VERSION ""

NS_ :

BS_:

BU_: LMFS RMFS TPMS TCU_ERAGLONASS E_APU PCCM NOX_2 NOX_1 ENGINE_CONTROL_MODULE TRANSMISSION INTARDER EBS TACHOGRAPH INSTRUMENT_CLUSTER CAMERA RADAR BCM
VAL_TABLE_ User_Data_Services_Selection 2 "Data Services On" 1 "Data Services Off" 0 "No Command" ;
VAL_TABLE_ User_Location_Selection 2 "Location On" 1 "Location Off" 0 "No Command" ;
VAL_TABLE_ UserConnectivitySelection 2 "Connectivity On" 1 "Connectivity Off" 0 "No Command" ;
VAL_TABLE_ Location_Status 3 "Reserved" 2 "On" 1 "Off" 0 "No command" ;
VAL_TABLE_ ConnectionStatusforTelltale 3 "Reserved" 2 "Sharing Data & Location" 1 "Sharing Just Data" 0 "Off" ;
VAL_TABLE_ ConnectivityHMIEnable 3 "Reserved" 2 "Connectivity Enabled" 1 "Connectivity Disabled" 0 "No Command" ;
VAL_TABLE_ RC_Window_Status 3 "Window_Calibration_is_required" 2 "Open" 1 "Inprogress" 0 "Closed" ;
VAL_TABLE_ Vt_Trip_Reset_2 3 "N/A" 2 "Error" 1 "Trip2 resetted by driver" 0 "No reset" ;
VAL_TABLE_ Vt_Trip_Reset_1 3 "N/A" 2 "Error" 1 "Trip1 resetted by driver" 0 "No reset" ;
VAL_TABLE_ PTOStatus_Vt 3 "NA" 2 "Reserved" 1 "On" 0 "Off" ;
VAL_TABLE_ RearFogLampStatus_VT 3 "NA" 2 "Reserved" 1 "On" 0 "Off" ;
VAL_TABLE_ ConnectionStatus_vt 3 "NA" 2 "Reserved" 1 "Connected" 0 "Not Connected" ;
VAL_TABLE_ FrontFogLampStatus_VT 3 "NA" 2 "Reserved" 1 "Front Fog On" 0 "Front Fog Off" ;
VAL_TABLE_ DoorLockStatus_Vt 3 "NA" 2 "No Status" 1 "Door Status is Locked" 0 "Door Status is Unlocked" ;
VAL_TABLE_ LaneDepartureWarning 3 "NA" 2 "Error" 1 "Enable Lane Departure Warning" 0 "Disable Lane Departure Warning" ;
VAL_TABLE_ DrvActivationDemand 3 "don’t care / take no action" 2 "error" 1 "no deactivation of AEBS" 0 "deactivation of AEBS" ;
VAL_TABLE_ Vt_SeatbeltStatus 3 "NA" 2 "Error" 1 "Not Belted" 0 "Belted" ;
VAL_TABLE_ LowCoolantLevel 3 "NA" 2 "Reserved" 1 "LOW Coolant Level" 0 "Coolant Level OK" ;
VAL_TABLE_ AirFilterRestriction 3 "NA" 2 "Reserved" 1 "Restriction on filter " 0 "No restricition on filter" ;
VAL_TABLE_ AutoECall_Inhibit 3 "Not available" 2 "Error indicator" 1 "E-Call Inhibit Active" 0 "E-Call Inhibit Not Active" ;
VAL_TABLE_ Vt_HeaterTimer1Status_Recurrence 3 "NA" 2 "Error" 1 "Repetitive" 0 "One Time" ;
VAL_TABLE_ Vt_HeaterTimer1Status_Day 10 "Everyday" 9 "Weekends" 8 "Weekdays" 7 "Sunday" 6 "Saturday" 5 "Friday" 4 "Thursday" 3 "Wednesday" 2 "Tuesday" 1 "Monday" ;
VAL_TABLE_ Vt_Outside_Air_Temp_Stat_Climate 255 "Invalid" 254 "Unknown" ;
VAL_TABLE_ vt_PCCScreenSelection 3 "Not Available" 2 "Error" 1 "Active" 0 "Deactive" ;
VAL_TABLE_ Vt_HazardLampStatus 3 "not available " 2 "Error" 1 "On" 0 "Off" ;
VAL_TABLE_ Vt_AC_clutch_status 3 "Not Available" 2 "Error" 1 "A/C clutch is engaged" 0 "A/C clutch is not engaged" ;
VAL_TABLE_ Vt_EcoRollSelection 3 "not available" 2 "error" 1 "active" 0 "deactive" ;
VAL_TABLE_ Vt_SpeedLimitsExceedStatus 7 "Reserved " 6 "Reserved " 5 "Reserved " 4 "Reserved " 3 "ASLD  speed limit exceed" 2 "PCC upper speed limit exceed" 1 "Cruise control set speed exceed" 0 "No exceed" ;
VAL_TABLE_ DriverRequestRCU 8 "Memory 2 Level Save" 7 "Memory 2 Height Request" 6 "Memory 1 Level Save" 5 "Memory 1 Height Request" 4 "Raise Chassis Height" 3 "Lower Chassis Height" 2 "Stop Button Pressed" 1 "Ride Height Request" ;
VAL_TABLE_ LampStatus 1 "Lamp on" 0 "Lamp off" ;
VAL_TABLE_ VtSigAuxIO03RetarderLeverPos 3 "Not Available" 2 "Error" 1 "IntarderLeverpos on" 0 "IntarderLeverpos off " ;
VAL_TABLE_ Emergency_Braking_Active 3 "not availeble" 2 "reserved" 1 "active" 0 "in-active" ;
VAL_TABLE_ Error_State 255 "Not available" 254 "Error" ;
VAL_TABLE_ VINACK_status_values 5 "VIN vaildate with previously VIN" 4 "Timout during VIN validation" 3 "Timout during VIN configuration" 2 "VIN not match previosly VIN" 1 "VIN Configuration done " 0 "Factory Def.:Config. not start" ;
VAL_TABLE_ ActiveDeactiveMode 3 "Not available" 2 "Error" 1 "Active" 0 "Deactive" ;
VAL_TABLE_ SensorIDMissingWarning 3 "Not available" 2 "Error" 1 "LearntSensorIDSupported&Missing" 0 "LearntSensorIDSupported&Present" ;
VAL_TABLE_ Vtsig_BremsomatConfiguration 7 "Not available" 6 "Reserved" 5 "Bremsomat Set Speed" 4 "Permanent Signal" 3 "Two buttons" 2 "One button" 1 "Bremsomat on pos 1 of hand lever" 0 "No Bremsomat" ;
VAL_TABLE_ Line_type 7 "no available/not installed" 6 "error" 5 "Bott'sDots detected" 4 "Double line detected" 3 "Dashed line detected" 2 "RoadEdge detected" 1 "Solid line detected" 0 "No line detected" ;
VAL_TABLE_ Hand_Lever_Signals 31 "Position 4" 15 "Position 3" 7 "Position 2" 3 "Position 1" 1 "Position 0" ;
VAL_TABLE_ Hand_lever_signals 3 "NotAvailable" 2 "Error" 1 "TCEngaged" 0 "TCNotEngaged" ;
VAL_TABLE_ OutPointer 254 "Error indicator" 255 "N/A" ;
VAL_TABLE_ OutLCD 254 "Error indicator" 255 "N/A" ;
VAL_TABLE_ OutDial 254 "Error indicator" 255 "N/A" ;
VAL_TABLE_ Time_to_collision 255 "N/A" 238 "Error indicator" ;
VAL_TABLE_ Ext_Vehicle_Speed_Enb 3 "Not available" 2 "Error" 1 "Enable external speed limit" 0 "Disable external speed limit" ;
VAL_TABLE_ SPN3698 3 "N/a" 2 "Reserved" 1 "High Exhaust System Temperature" 0 "Low Exhaust System Temperature" ;
VAL_TABLE_ SPN3712 3 "N/A" 2 "Error" 1 "Inhibited" 0 "Not_Inhibited" ;
VAL_TABLE_ TC1_BCM 3 "TakeNoAction" 2 "Reserve" 1 "Enabled" 0 "Disabled" ;
VAL_TABLE_ PTODE 3 "NA" 2 "Error" 1 "Active" 0 "NotActive" ;
VAL_TABLE_ ETC7 3 "Takenoaction" 2 "Reserve" 1 "Enable" 0 "Disable" ;
VAL_TABLE_ LowOilindicatorstatus 4 "Overfill warning" 3 "Not defined" 2 "Low oil warning" 1 "Critical Low Oil level" 0 "Oil Level OK" ;
VAL_TABLE_ OilChangeWarningIndicator 3 "Error State (Blink @ 2Hz)" 2 "Lamp On (Blinking @ 1 Hz)" 1 "Lamp On (Continuous) " 0 "Lamp Off" ;
VAL_TABLE_ EngineFuelFilterRestrictionLamp 3 "NA" 2 "NA" 1 "Lamp On" 0 "Lamp Off" ;
VAL_TABLE_ ClutchProtectionBuzzer 3 "Error" 2 "Blinking Buzzer" 1 "Continuous Buzzer" 0 "No Buzzer" ;
VAL_TABLE_ ClutchProtectionWarning 3 "Error" 2 "Blinking clutch warning lamp" 1 "Continuous clutch warning lamp" 0 "No warning" ;
VAL_TABLE_ TamperingFaultsBlockedEGR 1 "Critical Emissions Failure" 0 "No warning" ;
VAL_TABLE_ AdblueConsumption 1 "AdBlue Dosing Malfunction" 0 "No warning" ;
VAL_TABLE_ TC1 255 "Error" 253 "Hold current gear" 249 "Upshift 1 gear from current pos" 248 "Upshift 2 gears from current pos" 247 "Downshift 1 gear fromcurrentpos" 246 "Downshift 2 gear fromcurrentpos" ;
VAL_TABLE_ Inhibit 3 "na" 2 "reserved" 1 "inhibited" 0 "not inhibited" ;
VAL_TABLE_ ChargeMode 15 "Error" 14 "Mode 14" 13 "Mode 13" 12 "Mode 12" 11 "Mode 11" 10 "Mode 10" 9 "Mode 9" 8 "Mode 8" 7 "Mode 7" 6 "Mode 6" 5 "Mode 5" 4 "Mode 4" 3 "Mode 3" 2 "Mode 2" 1 "Mode 1" 0 "Mode 0" ;
VAL_TABLE_ Flag 3 "Not Available" 2 "Error" 1 "Flag set" 0 "Flag not set" ;
VAL_TABLE_ ConcretePumpStartRequest 3 "NA Error" 2 "No Request" 1 "Engine Start" ;
VAL_TABLE_ APUPressureSwitch 3 "NotAvailable" 2 "Error" 1 "On" 0 "Off" ;
VAL_TABLE_ AxleState 3 "SelfSteer and TagAxle lifted" 2 "Tag axle lifted" 1 "Self steer axle lifted" 0 "SelfSteer and TagAxle not lifted" ;
VAL_TABLE_ Warning 65 "parking brake is engaged " 17 "Failure Mode is detected" 9 "axle is overloaded" 5 "speedisover30kphduringaxlelift" 3 "Lift/Drop Other axle first" 0 "no warning is active" ;
VAL_TABLE_ Action 99 "Tag axle can’t be lifted" 77 "Self-steer can’t be lifted" 66 "Self-steer can’t be dropped" 44 "Tag axle is being dropped" 22 "Self-steer is being dropped" 10 "Tag axle can’t be dropped" 9 "Tag axle can’t be lifted" 8 "Tag axle can’t be lifted" 7 "Self-steer can’t be lifted" 6 "Self-steer can’t be dropped " 5 "Self-steer can’t be dropped" 4 "Tag axle is being dropped" 3 "Tag axle is being lifted SSisup" 2 "SSisbeingdrped/AutoDropFunc" 1 "Self-steer is being lifted " 0 "No action is occurred " ;
VAL_TABLE_ BatteryService 3 "NotAvailable" 2 "Error" 1 "BatteryServiceNeeded" 0 "BatteryServiceNotNeeded" ;
VAL_TABLE_ EnableSwitchStatus 3 "NotAvailable" 2 "Error" 1 "Active" 0 "NotActive" ;
VAL_TABLE_ ConcretePumpTransferCaseACK 3 "NotAvailable" 2 "Error" 1 "TCEngaged" 0 "TCNotEngaged" ;
VAL_TABLE_ PTOApplicationMode 7 "SIGError" 6 "MinError" 5 "MaxError" 4 "NotPlausible" 3 "Mode3" 2 "Mode2" 1 "Mode1" 0 "Mode0" ;
VAL_TABLE_ CameraStatus 14 "NotAvailable" 13 "Error" 4 "Misaligned" 3 "Blocked" 2 "PartiallyBlocked" 1 "Warningup/Initializing" 0 "FullyOperational" ;
VAL_TABLE_ EGR2EDC 1 "Failure" 0 "NoFailure" ;
VAL_TABLE_ WheelBrakeLiningInfo 255 "NotAvailable" 254 "Error" 252 "BrkPadWearSensorNOK" 251 "BrkPadWearSensorOK" ;
VAL_TABLE_ QuickRockingMode 1 "Active" 0 "NotActive" ;
VAL_TABLE_ ReqstCruiseContrlSwtchOff 3 "NotAvailable" 2 "Reserved" 1 "IntrdrIsReqstCCSwtchOff" 0 "IntrdrIsNotReqstCCSwtchOff" ;
VAL_TABLE_ RetarderOnDriverDemand 3 "NotAvailable" 2 "Reserved" 1 "RetarderOnDriverDemand" 0 "NoRetarderOnDriverDemand" ;
VAL_TABLE_ RequestIntardrPilotLamp 3 "NotAvailable" 2 "Reserved" 1 "IntIsReqstngPilotLamp" 0 "IntIsNotReqstngPilotLamp" ;
VAL_TABLE_ IntPilotLampState 3 "NotAvailable" 2 "IntarderPilotLampFlashes" 1 "IntarderPilotLampOn" 0 "IntarderPilotLampOff" ;
VAL_TABLE_ RtrdrCtrlMthd 0 "ContinuousControl" ;
VAL_TABLE_ EngRqstSpeedCntrlCondition 3 "XStbOptDrvEngaged" 2 "StbOptDrvEngaged" 1 "StbOptDrvDisengaged" 0 "TrnstOptDrvDisengaged" ;
VAL_TABLE_ GearboxNeutralPosition 3 "NotAvailable" 2 "Error" 1 "SecuredNeutralPosition" 0 "NotInSecuredNeutralPosition" ;
VAL_TABLE_ TrailerABSFullyOperational 3 "NotAvailable" 2 "Error" 1 "TrailerABSFullyOperational" 0 "TrailerABSNotFullyOperational" ;
VAL_TABLE_ TrailerABSDetected 3 "NotAvailable" 2 "Error" 1 "TrailerABSDetected" 0 "TrailerABSNotDetected" ;
VAL_TABLE_ BlendingSwitchPos 3 "NotAvailable" 2 "Error" 1 "RetarderBlendingEnabled" 0 "RetarderBlendingDiasabled" ;
VAL_TABLE_ AuxI_O05_TrailerConnected 3 "NotAvailable" 1 "TrailerConnected" 0 "TrailerNotConnected" ;
VAL_TABLE_ LaneDepartureWarningSystemStatus 15 "NotAvailable" 14 "Error" 5 "SystemIsWarning" 4 "DriverOverridesSystem" 3 "SystemIsReady" 2 "SystemIsDeactivatedByDriver" 1 "SystemIsTempNotAvailable" 0 "SystemIsNotReady" ;
VAL_TABLE_ OpticalAcousticWarning 3 "NotAvailable" 2 "Error" 1 "Active" 0 "Inactive" ;
VAL_TABLE_ AdvancedEmergencyBrkSysState 15 "NotAvailable" 14 "ErrorIndication" 7 "EmergencyBrakingActive" 6 "CollisionWarningWithBraking" 5 "CollisionWarningActive" 4 "DriverOverridesSystem" 3 "SystemIsReady" 2 "SystemDeactivatedbyDriver" 1 "SystemTemporaryNotAvailable" 0 "SystemIsnotReady" ;
VAL_TABLE_ WiperActive 3 "NotAvailable" 2 "Error" 1 "WiperActive" 0 "WiperIsNotActive" ;
VAL_TABLE_ Interlock 3 "NotAvailable" 2 "Error" 1 "InterlockEngaged" 0 "InterlockDisengaged" ;
VAL_TABLE_ ReverseGearState 255 "NotAvailable" 254 "Error" 240 "NotDefined" 223 "GearInReversePosition" 1 "NotDefined" 0 "NotInReverseGear" ;
VAL_TABLE_ ParticulateTrapRegenForceSw 3 "NotAvailable" 2 "Error" 1 "Active" 0 "NotActive" ;
VAL_TABLE_ ParticulateTrapRegenInSwitch 3 "NotAvailable" 2 "Error" 1 "Active" 0 "NotActive" ;
VAL_TABLE_ ACCompressorSwitch 3 "NotAvailable" 2 "Error" 1 "PressureNormal" 0 "Pressureisnotnormal" ;
VAL_TABLE_ AEBS2_DriverActivationDemand 3 "NotAvailable" 2 "Error" 1 "NoDeactivationofAEBS" 0 "DeactivationofAEBS" ;
VAL_TABLE_ ERC_Int_RetarderTorqueMode 15 "NotAvailable" 14 "VCMNegativeTorqueLimit" 13 "NotDefined" 12 "NotDefined" 11 "NotDefined" 10 "RetarderControl" 9 "HighSpeedGovernor" 8 "TorqueLimiter" 7 "ABSControl" 6 "TransmissionControl" 5 "ASRControl" 4 "RoadSpeedLimiter" 3 "PowerTakeOffGovernor" 2 "CruiseControl" 1 "OperatorSelection" 0 "NoRequest" ;
VAL_TABLE_ ERC1_ECM_RetarderTorqueMode 15 "NotAvailable" 14 "VCMNegativeTorqueDemand" 13 "NotDefined" 12 "NotDefined" 11 "NotDefined" 10 "RetarderControl" 9 "HighSpeedLimiter" 8 "TorqueLimiter" 7 "ABSControl" 6 "TransmissionControl" 5 "ASRControl" 4 "RoadSpeedLimiter" 3 "PowerTakeOffGovernor" 2 "CruiseControl" 1 "OperatorSelection" 0 "NoRequest" ;
VAL_TABLE_ SourceAdrsControllingDevice_EEC1 5 "Description for the value '0x5'" 4 "GearBoxControlstheEngineTorque" 3 "PTOcontrolstheEngineTorque" 2 "RetarderControlstheEngineTorque" 1 "ABS/ASRcontrolstheenginetorque" 0 "EDCcontrolsTheEngineTorque" ;
VAL_TABLE_ TBMTelltale 3 "Unknown" 2 "Flash" 1 "Off" 0 "On" ;
VAL_TABLE_ ErrorIndication 63 "ErrorCode" 62 "ErrorCode" 61 "ErrorCode" 60 "ForbiddenValues" 59 "ErrorCode" 58 "ErrorCode" 57 "ErrorCode" 56 "ErrorCode" 55 "ErrorCode" 54 "ErrorCode" 53 "ErrorCode" 52 "ErrorCode" 51 "ErrorCode" 50 "ForbiddenValues" 49 "ErrorCode" 48 "ErrorCode" 47 "ErrorCode" 46 "ErrorCode" 45 "ErrorCode" 44 "ErrorCode" 43 "ErrorCode" 42 "ErrorCode" 41 "ErrorCode" 40 "ForbiddenValues" 39 "ErrorCode" 38 "ErrorCode" 37 "ErrorCode" 36 "ErrorCode" 35 "ErrorCode" 34 "ErrorCode" 33 "ErrorCode" 32 "ErrorCode" 31 "ErrorCode" 30 "ForbiddenValues" 29 "ErrorCode" 28 "ErrorCode" 27 "ErrorCode" 26 "ErrorCode" 25 "ErrorCode" 24 "ErrorCode" 23 "ErrorCode" 22 "ErrorCode" 21 "ErrorCode" 20 "ForbiddenValues" 19 "ErrorCode" 18 "ErrorCode" 17 "ErrorCode" 16 "ErrorCode" 15 "ErrorCode" 14 "ErrorCode" 13 "ErrorCode" 12 "ErrorCode" 11 "ErrorCode" 10 "ForbiddenValues" 9 "ForbiddenValues" 8 "ForbiddenValues" 7 "ForbiddenValues" 6 "ForbiddenValues" 5 "ForbiddenValues" 4 "ForbiddenValues" 3 "ForbiddenValues" 2 "ForbiddenValues" 1 "ForbiddenValues" 0 "ForbiddenValues" ;
VAL_TABLE_ ROPSystem 3 "NotAvailable" 2 "Error" 1 "Enabled" 0 "Disabled" ;
VAL_TABLE_ YCsystemEnabledDisabled 3 "NotAvailable" 2 "Error" 1 "Enabled" 0 "Disabled" ;
VAL_TABLE_ ChechPhaseWarnings2 3 "NotAvailable" 2 "Error" 1 "CheckPhaseActive" 0 "CheckPhaseNotActive" ;
VAL_TABLE_ ReleaseAcceleratorPedalWarn2 3 "NotAvailable" 2 "Error" 1 "ReleaseAccPedal" 0 "Acc.PedalPosOk" ;
VAL_TABLE_ PTO1activeWarnings2 3 "NotAvailable" 2 "Error" 1 "PTO1Active" 0 "PTO1notActive" ;
VAL_TABLE_ PTO2activeWarning2 3 "NotAvailable" 2 "Error" 1 "PTO2Active" 0 "PTO2notactive" ;
VAL_TABLE_ ClutchWearWarnings1 3 "NotAvailable" 2 "Error" 1 "ClutchWornOut" 0 "ClutchOk" ;
VAL_TABLE_ ClutchOverloadWarnings1 3 "NotAvailable" 2 "Error" 1 "ClutchOverloaded" 0 "ClutchNotOverloaded" ;
VAL_TABLE_ ASTronicLowAirWarnings1 3 "NotAvailable" 2 "Error" 1 "AirPressureSupplytooLow" 0 "AirPressureSupplyOk" ;
VAL_TABLE_ TemperatureTooHighWarnings1 3 "NotAvailable" 2 "Error" 1 "TemperaturetooHigh" 0 "TemperatureOK" ;
VAL_TABLE_ StopWarningStatus 3 "NotAvailable" 2 "Error" 1 "StopWarning" 0 "NoStopWarning" ;
VAL_TABLE_ SpannerWarningStatus 3 "NotAvailanle" 2 "Error" 1 "SpannerWarning" 0 "NoSpannerWarning" ;
VAL_TABLE_ ManouveringModeStatus 3 "NotAvailable" 2 "Error" 1 "ManoeuveringModeActive" 0 "ManoeuveringModeNotActive" ;
VAL_TABLE_ AutomaticManualModeStat 3 "NotAvailable" 2 "Error" 1 "AutomaticModeActive" 0 "ManualModeActive" ;
VAL_TABLE_ EngineDegradationLevel 15 "notDefined" 14 "notDefined" 13 "notDefined" 12 "notDefined" 11 "notDefined" 10 "notDefined" 9 "notDefined" 8 "notDefined" 7 "notDefined" 6 "notDefined" 5 "notDefined" 4 "Degradation Level 4" 3 "Degradation Level 3" 2 "Degradation Level 2" 1 "Degradation Level 1" 0 "NoDegradation" ;
VAL_TABLE_ EDCOperationStat 15 "NotDefined" 14 "NotDefined" 13 "NotDefined" 12 "NotDefined" 11 "NotDefined" 10 "NotDefined" 9 "NotDefined" 8 "NotDefined" 7 "NotDefined" 6 "NotDefined" 5 "NotDefined" 4 "NotDefined" 3 "OverRunMonitoringActive" 2 "DiagnosticTest" 1 "AfterrunActive" 0 "NormalOperation" ;
VAL_TABLE_ EngineOilPressureLow 3 "NotAvailable" 2 "Reserved" 1 "AboveOperatingRange" 0 "Normal" ;
VAL_TABLE_ WaterInFuelDetection 3 "Description for the value '0x3'" 2 "Reserved" 1 "Yes" 0 "No" ;
VAL_TABLE_ FuelFilterHeaterStatus 3 "NotAvailable" 2 "Reserved" 1 "On" 0 "Off" ;
VAL_TABLE_ EngineOilTempHigh 3 "NotAvailable" 2 "Reserved" 1 "AboveOperatingRange" 0 "Normal" ;
VAL_TABLE_ StatOfEngCompStpButton 3 "NotAvailable" 2 "Reserved" 1 "On" 0 "Off" ;
VAL_TABLE_ StatOfEngCompStrtBut 3 "NotAvailable" 2 "Reserved" 1 "On" 0 "Off" ;
VAL_TABLE_ MILStats 3 "NotAvailable" 2 "Blink" 1 "On" 0 "Off" ;
VAL_TABLE_ AdjustableSpeedLimiterStatus 3 "Description for the value '0x3'" 2 "onn(LmtnActive" 1 "on(viaCC)" 0 "off" ;
VAL_TABLE_ ECMFuellingState 3 "NotAvailable" 1 "NotReadyto Inject" 0 "ReadytoInject" ;
VAL_TABLE_ SpeedLimiterStatus 3 "2ndspeedandprogSpdLmtnRq" 2 "Progr.VehicleSpeedLmtnrequested" 1 "2ndSpeedLimitationRequest" 0 "NoSpeedLimitationRequest" ;
VAL_TABLE_ EngineOverSpeed 3 "NotAvailable" 2 "Reserved" 1 "AboveOperatingRange" 0 "Normal" ;
VAL_TABLE_ EngineOverTemperature 3 "NotDefined" 2 "Warning" 1 "PreWarning" 0 "NoWarning" ;
VAL_TABLE_ ColdStartHeaterStatus 15 "NotDefined" 14 "NotDefined" 13 "NotDefined" 12 "NotDefined" 11 "NotDefined" 10 "NotDefined" 9 "CldStrtHtActvtdPrtcleFilterRgnrt" 8 "ColdStartHeaterTestinProgress" 7 "TemperaturePre-EvaluationPhase" 6 "PostHeatingPhase" 5 "CrankwithExtraHeatingPhase" 4 "CrankPhase" 3 "StandbyPhasew/oHeating" 2 "StandbyPhasewithHeating" 1 "Pre-HeatingPhase" 0 "OffPhase" ;
VAL_TABLE_ FuelBlockStatByImmobilizer 2 "NoImmobilizer" 1 "FuelBlocked" 0 "FuelReleased" ;
VAL_TABLE_ DiagnosticlampStat 3 "NoAction" 2 "reserved" 1 "on" 0 "off" ;

BO_ 3221225472 VECTOR__INDEPENDENT_SIG_MSG: 0 Vector__XXX
 SG_ New_Signal_4901 : 0|8@1- (1,0) [0|0] "" Vector__XXX
 SG_ ACCSetDistanceMode : 0|3@1+ (1,0) [0|7] "" Vector__XXX
 SG_ ACCMode : 0|3@1+ (1,0) [0|7] "" Vector__XXX
 SG_ ACCSetSpeed : 0|8@1+ (1,0) [0|250] "Km/h" Vector__XXX
 SG_ DistancetoForwardVehicle : 0|8@1+ (1,0) [0|250] "m" Vector__XXX
 SG_ SpeedofForwardVehicle : 0|8@1+ (1,0) [0|250] "km/h" Vector__XXX
 SG_ TesterReqTransmission : 0|64@1- (1,0) [0|0] "" Vector__XXX
 SG_ TesterReqTachograpgh : 0|64@1- (1,0) [0|0] "" Vector__XXX
 SG_ TrailerWeight : 0|16@1+ (2,0) [0|128510] "kg" Vector__XXX
 SG_ ReferenceTirePressSetting : 0|8@1+ (8,0) [0|2000] "kPa" Vector__XXX
 SG_ ReferenceTirePress : 0|8@1+ (8,0) [0|2000] "kPa" Vector__XXX
 SG_ TirePressThresholdDetection : 0|3@1+ (1,0) [0|7] "" Vector__XXX
 SG_ TireAirLeakageRate : 0|16@1+ (0.1,0) [0|6425.5] "Pa/s" Vector__XXX
 SG_ CTIWheelEndElectricalFault : 0|2@1+ (1,0) [0|3] "" Vector__XXX
 SG_ CTITireStatus : 0|2@1+ (1,0) [0|3] "" Vector__XXX
 SG_ CTIWheelSensorStatus : 0|2@1+ (1,0) [0|3] "" Vector__XXX
 SG_ TireTemp : 0|16@1+ (0.03125,-273) [-273|1734.96875] "deg C" Vector__XXX
 SG_ TirePress : 0|8@1+ (4,0) [0|1000] "kPa" Vector__XXX
 SG_ AntitheftRandomNumber : 0|56@1+ (1,0) [0|255] "" Vector__XXX
 SG_ AntitheftComponentStatusStates : 0|2@1+ (1,0) [0|3] "" Vector__XXX
 SG_ AntthftEncryptnSdPrsntIndicator : 0|2@1+ (1,0) [0|3] "" Vector__XXX
 SG_ AntitheftModifyPwdStates : 0|2@1+ (1,0) [0|3] "" Vector__XXX
 SG_ AntitheftPwdValidIndicator : 0|2@1+ (1,0) [0|3] "" Vector__XXX
 SG_ EngBuildHoursReset : 0|2@1+ (1,0) [0|3] "" Vector__XXX
 SG_ SteerStraightAheadPosReset : 0|2@1+ (1,0) [0|3] "" Vector__XXX
 SG_ ServiceComponentIdentification : 0|8@1+ (1,0) [0|250] "ID" Vector__XXX
 SG_ ServiceComponentIdentificationC : 0|8@1+ (1,0) [0|250] "ID" Vector__XXX
 SG_ ATR_Notdefined : 0|8@1+ (1,0) [0|0] "" Vector__XXX
 SG_ TrnsShftSlctorDisplayModeSwitch : 0|2@1+ (1,0) [0|3] "" Vector__XXX
 SG_ TransMode4 : 0|2@1+ (1,0) [0|3] "" Vector__XXX
 SG_ TransMode3 : 0|2@1+ (1,0) [0|3] "" Vector__XXX
 SG_ TransMode2 : 0|2@1+ (1,0) [0|3] "" Vector__XXX
 SG_ DisengageDiffLockRqCentralRear : 0|2@1+ (1,0) [0|3] "" Vector__XXX
 SG_ DisengageDiffLockRqCentralFront : 0|2@1+ (1,0) [0|3] "" Vector__XXX
 SG_ DisengageDiffLockRqCentral : 0|2@1+ (1,0) [0|3] "" Vector__XXX
 SG_ DisengageDiffLockRqRearAxle2 : 0|2@1+ (1,0) [0|3] "" Vector__XXX
 SG_ DisengageDiffLockRqRearAxle1 : 0|2@1+ (1,0) [0|3] "" Vector__XXX
 SG_ DisengageDiffLockRqFrontAxle2 : 0|2@1+ (1,0) [0|3] "" Vector__XXX
 SG_ DisengageDiffLockRqFrontAxle1 : 0|2@1+ (1,0) [0|3] "" Vector__XXX
 SG_ TransRqedGear : 0|8@1+ (1,-125) [-125|125] "" Vector__XXX
 SG_ RqedPercentClutchSlip : 0|8@1+ (0.4,0) [0|100] "%" Vector__XXX
 SG_ DisengageDrivelineRq : 0|2@1+ (1,0) [0|3] "" Vector__XXX
 SG_ TrnsTrqConverterLockupDisableRq : 0|2@1+ (1,0) [0|3] "" Vector__XXX
 SG_ TransRqedLaunchGear : 0|4@1+ (1,0) [0|15] "" Vector__XXX
 SG_ TransReverseGearShiftInhibitRq : 0|2@1+ (1,0) [0|3] "" Vector__XXX
 SG_ TransMode8 : 0|2@1+ (1,0) [0|3] "" Vector__XXX
 SG_ TransMode7 : 0|2@1+ (1,0) [0|3] "" Vector__XXX
 SG_ TransMode6 : 0|2@1+ (1,0) [0|3] "" Vector__XXX
 SG_ TransMode5 : 0|2@1+ (1,0) [0|3] "" Vector__XXX
 SG_ MessageCounter : 0|4@1+ (1,0) [0|15] "" Vector__XXX
 SG_ ControlPurpose : 0|5@1+ (1,0) [0|31] "" Vector__XXX
 SG_ TransmissionRate : 0|3@1+ (1,0) [0|7] "" Vector__XXX
 SG_ EngineRequestedTorqueHiRes : 0|4@1+ (0.125,0) [0|0.875] "%" Vector__XXX
 SG_ ControlPurpose : 0|5@1+ (1,0) [0|31] "" Vector__XXX
 SG_ TransmissionRate : 0|3@1+ (1,0) [0|7] "" Vector__XXX
 SG_ EngineRequestedTorqueHiRes : 0|4@1+ (0.125,0) [0|0.875] "%" Vector__XXX
 SG_ MessageCounter : 0|4@1+ (1,0) [0|15] "" Vector__XXX
 SG_ ControlPurpose : 0|5@1+ (1,0) [0|31] "" Vector__XXX
 SG_ TransmissionRate : 0|3@1+ (1,0) [0|7] "" Vector__XXX
 SG_ MessageChecksum : 0|4@1+ (1,0) [0|15] "" Vector__XXX
 SG_ EngineRequestedTorqueHiRes : 0|4@1+ (0.125,0) [0|0.875] "%" Vector__XXX
 SG_ PrkngBrkeActuatorFullyActivated : 0|2@1+ (1,0) [0|3] "" Vector__XXX
 SG_ DslPrtcltFltrActvRgnrtnFrcdStts : 0|3@1+ (1,0) [0|7] "" Vector__XXX
 SG_ ExhaustSystemHighTempLampCmd : 0|3@1+ (1,0) [0|7] "" Vector__XXX
 SG_ DslPrtcltFltrAtmtcActvRgnrtnIntt : 0|2@1+ (1,0) [0|3] "" Vector__XXX
 SG_ DslPrtcltFltrActvRgnrtnInhbtdDTV : 0|2@1+ (1,0) [0|3] "" Vector__XXX
 SG_ DslPrtcltFltrActvRgnrtnInhbtdDTE : 0|2@1+ (1,0) [0|3] "" Vector__XXX
 SG_ DslPrtcltFltrActvRgnrtnInhbtdDTP : 0|2@1+ (1,0) [0|3] "" Vector__XXX
 SG_ DslPrtcltFltrActvRgnrtnInhbtdDTT : 0|2@1+ (1,0) [0|3] "" Vector__XXX
 SG_ DslPrtcltFltrActvRgnrtnInhbtdDTS : 0|2@1+ (1,0) [0|3] "" Vector__XXX
 SG_ DslPrtcltFltrActvRgnrtnInhb_0000 : 0|2@1+ (1,0) [0|3] "" Vector__XXX
 SG_ DslPrtcltFltrActvRgnrtnInhbtdDTL : 0|2@1+ (1,0) [0|3] "" Vector__XXX
 SG_ DslPrtcltFltrActvRgnrtnInhb_0001 : 0|2@1+ (1,0) [0|3] "" Vector__XXX
 SG_ DslPrtcltFltrActvRgnrtnInhb_0002 : 0|2@1+ (1,0) [0|3] "" Vector__XXX
 SG_ DslPrtcltFltrActvRgnrtnInhbtdDTO : 0|2@1+ (1,0) [0|3] "" Vector__XXX
 SG_ DslPrtcltFltrActvRgnrtnInhbtdDTA : 0|2@1+ (1,0) [0|3] "" Vector__XXX
 SG_ DslPrtcltFltrActvRgnrtnInhb_0003 : 0|2@1+ (1,0) [0|3] "" Vector__XXX
 SG_ DslPrtcltFltrActvRgnrtnInhb_0004 : 0|2@1+ (1,0) [0|3] "" Vector__XXX
 SG_ DslPrtcltFltrActvRgnrtnInhbtdDTC : 0|2@1+ (1,0) [0|3] "" Vector__XXX
 SG_ DslPrtcltFltrActvRgnrtnInhbtdDTI : 0|2@1+ (1,0) [0|3] "" Vector__XXX
 SG_ DslPrtcltFltrActvRgnrtnInhbtdStt : 0|2@1+ (1,0) [0|3] "" Vector__XXX
 SG_ DslPrtcltFltrActvRgnrtionStatus : 0|2@1+ (1,0) [0|3] "" Vector__XXX
 SG_ DslPrtcltFltrPssvRgnrtionStatus : 0|2@1+ (1,0) [0|3] "" Vector__XXX
 SG_ DieselParticulateFilterLampCmd : 0|3@1+ (1,0) [0|7] "" Vector__XXX
 SG_ Aftrtrtmnt1SCRCtlystRgntTnk1HtrP : 0|5@1+ (1,0) [0|31] "" Vector__XXX
 SG_ Aftrtrtmnt1SCRCtalystTankHeater : 0|8@1+ (0.4,0) [0|100] "%" Vector__XXX
 SG_ AftrtrtmntSCROprtrIndcmntSvrity : 0|3@1+ (1,0) [0|7] "" Vector__XXX
 SG_ Aftrtrtmnt1SCRCtlystRgntTnk1TmpP : 0|5@1+ (1,0) [0|31] "" Vector__XXX
 SG_ Aftrtrtmnt1DEFTnkLwLvlIndicator : 0|3@1+ (1,0) [0|7] "" Vector__XXX
 SG_ Aftrtrtmnt1SCRCtlystTnkLvlPrlmnr : 0|5@1+ (1,0) [0|31] "" Vector__XXX
 SG_ Aftrtrtmnt1SCRCtalystTankLevel2 : 0|16@1+ (0.1,0) [0|6425.5] "mm" Vector__XXX
 SG_ Aftrtrtment1SCRCatalystTankTemp : 0|8@1+ (1,-40) [-40|210] "deg C" Vector__XXX
 SG_ Aftrtrtmnt1SCRCatalystTankLevel : 0|8@1+ (0.4,0) [0|100] "%" Vector__XXX
 SG_ EngShutdownOverrideSwitch : 0|2@1+ (1,0) [0|3] "" Vector__XXX
 SG_ EngTestModeSwitch : 0|2@1+ (1,0) [0|3] "" Vector__XXX
 SG_ EngIdleDecrementSwitch : 0|2@1+ (1,0) [0|3] "" Vector__XXX
 SG_ EngIdleIncrementSwitch : 0|2@1+ (1,0) [0|3] "" Vector__XXX
 SG_ OprtrsDesiredDelayedLampOffTime : 0|16@1+ (1,0) [0|64255] "s" Vector__XXX
 SG_ CruiseCtrlStates : 0|3@1+ (1,0) [0|7] "" Vector__XXX
 SG_ Hand_Lever_Signals : 0|8@1+ (1,0) [0|31] "" Vector__XXX
 SG_ AxleWeight_30 : 0|16@1+ (0.5,0) [0|32127.5] "kg" Vector__XXX
 SG_ AxleWeight_20 : 0|16@1+ (0.5,0) [0|32127.5] "kg" Vector__XXX
 SG_ AxleWeight_10 : 0|16@1+ (0.5,0) [0|32127.5] "kg" Vector__XXX
 SG_ AuxI_O08_GearboxNeutralPos : 0|2@1+ (1,0) [0|3] "" Vector__XXX
 SG_ AuxI_O07_TrailerABSFulOper : 0|2@1+ (1,0) [0|3] "" Vector__XXX
 SG_ AuxI_O06_TrailerABSDetected : 0|2@1+ (1,0) [0|3] "" Vector__XXX
 SG_ AuxI_O05_TrailerConnected : 0|2@1+ (1,0) [0|3] "" Vector__XXX
 SG_ AuxI_O02_BlendingSwitchPos : 0|2@1+ (1,0) [0|3] "" Vector__XXX
 SG_ PCCM_TransReqGearPriority : 0|4@1+ (1,0) [0|15] "" Vector__XXX
 SG_ PCCM_TransGearShiftRequest : 0|8@1+ (1,-125) [0|125] "" Vector__XXX
 SG_ ATS_Notdefined : 0|8@1+ (1,0) [0|255] "" Vector__XXX
 SG_ PCCMaxPosSpdOffset : 0|8@1+ (0.125,31.25) [0|32] "kmh" Vector__XXX
 SG_ PCCMaxNegSpdOffset : 0|8@1+ (0.125,-31.25) [0|32] "kmh" Vector__XXX
 SG_ TrailerBrakeStatus : 0|2@1+ (1,0) [0|3] "" Vector__XXX
 SG_ AuxHeaterMode : 0|4@1+ (1,0) [0|15] "" Vector__XXX
 SG_ EngThrottleValve2Pos : 0|8@1+ (0.4,0) [0|100] "%" Vector__XXX
 SG_ EngThrottleValve2Pos : 0|8@1+ (0.4,0) [0|100] "%" Vector__XXX
 SG_ AuxEquipmentSupplyPress : 0|8@1+ (8,0) [0|2000] "kPa" Vector__XXX
 SG_ VhclSped_Ctrl_Override_Request : 0|2@1+ (1,0) [0|3] "" Vector__XXX
 SG_ VhclSped_Ctrl_Override_EvntIndic : 0|2@1+ (1,0) [0|3] "" Vector__XXX
 SG_ PreCru_CtrlDriv_Disgage_inhbtReq : 0|2@1+ (1,0) [0|3] "" Vector__XXX
 SG_ PreCru_Ctrl_SpeedEventIndicator : 0|2@1+ (1,0) [0|3] "" Vector__XXX
 SG_ PreCru_Ctrl_NextGrade : 0|8@1- (0.125,-16) [-16|15.25] "%" Vector__XXX
 SG_ PreCru_Ctrl_EventinRange : 0|2@1+ (1,0) [0|3] "" Vector__XXX
 SG_ AuxI_O03_RetarderLeverPos : 0|3@1+ (1,0) [0|7] "SED" Vector__XXX
 SG_ ReverseGearState : 0|8@1+ (1,0) [0|0] "" Vector__XXX
 SG_ AuxiliaryHeaterMode : 0|4@1- (1,0) [-8|7] "" Vector__XXX
 SG_ GearShiftPriority : 0|4@1+ (1,0) [0|15] "" Vector__XXX
 SG_ CruiseCtrlLowSetLimitSpeed : 0|8@1+ (1,0) [0|250] "km/h" Vector__XXX
 SG_ CruiseCtrlHighSetLimitSpeed : 0|8@1+ (1,0) [0|250] "km/h" Vector__XXX
 SG_ MaxVehicleSpeedLimit : 0|8@1+ (1,0) [0|250] "km/h" Vector__XXX
 SG_ FlashRedStopLamp : 0|2@1+ (1,0) [0|3] "" Vector__XXX
 SG_ FlashProtectLamp : 0|2@1+ (1,0) [0|3] "" Vector__XXX
 SG_ FlashMalfuncIndicatorLamp : 0|2@1+ (1,0) [0|3] "" Vector__XXX
 SG_ FlashAmberWarningLamp : 0|2@1+ (1,0) [0|3] "" Vector__XXX
 SG_ MalfunctionIndicatorLampStatus : 0|2@1+ (1,0) [0|3] "" Vector__XXX
 SG_ AmberWarningLampStatus : 0|2@1+ (1,0) [0|3] "" Vector__XXX
 SG_ ProtectLampStatus : 0|2@1+ (1,0) [0|3] "" Vector__XXX
 SG_ DTC5 : 0|32@1+ (1,0) [0|4294967295] "" Vector__XXX
 SG_ DTC4 : 0|32@1+ (1,0) [0|4294967295] "" Vector__XXX
 SG_ DTC3 : 0|32@1+ (1,0) [0|4294967295] "" Vector__XXX
 SG_ DTC2 : 0|32@1+ (1,0) [0|4294967295] "" Vector__XXX
 SG_ DTC1 : 0|32@1+ (1,0) [0|4294967295] "" Vector__XXX
 SG_ SCRThermalManagementActive : 0|2@1+ (1,0) [0|3] "" Vector__XXX
 SG_ MmntryEngMaxPowerEnableFeedback : 0|2@1+ (1,0) [0|3] "" Vector__XXX
 SG_ DPFThermalManagementActive : 0|2@1+ (1,0) [0|3] "" Vector__XXX
 SG_ TwoSpeedAxleSwitch : 0|2@1+ (1,0) [0|3] "" Vector__XXX
 SG_ OTAUpdateRequest2 : 0|2@1- (1,0) [0|3] "SED" Vector__XXX
 SG_ ACC_Inhibit_CCVS : 0|2@1- (1,0) [0|3] "SED" Vector__XXX
 SG_ CatalystTankLevelPreliminaryFMI : 0|8@1+ (1,0) [0|0] "" Vector__XXX
 SG_ CatalystTankLevel2 : 0|16@1+ (0.1,0) [0|6425.5] "mm" Vector__XXX
 SG_ EngIntakeManifold1Press : 0|8@1+ (2,0) [0|500] "kPa" Vector__XXX
 SG_ FreezeFrameLength : 0|8@1+ (1,0) [0|255] "Byte" Vector__XXX
 SG_ EngSpeed : 0|16@1+ (0.125,0) [0|8031.875] "rpm" Vector__XXX
 SG_ EngTorqueMode : 0|4@1+ (1,0) [0|15] "" Vector__XXX
 SG_ WheelBasedVehicleSpeed : 0|16@1+ (0.00390625,0) [0|250.996] "km/h" Vector__XXX
 SG_ EngPercentLoadAtCurrentSpeed : 0|8@1+ (1,0) [0|250] "%" Vector__XXX
 SG_ EngineCoolantTemperature : 0|8@1+ (1,-40) [-40|210] "°C" Vector__XXX
 SG_ DTC1 : 0|32@1+ (1,0) [0|4294967295] "" Vector__XXX
 SG_ MeasuredPercentMotorSpeed : 0|16@1- (0.5,0) [0|0] "%bit" Vector__XXX
 SG_ MeasuredMotorPower : 0|16@1- (1,0) [0|0] "W/bit" Vector__XXX
 SG_ MeasuredMotorControllerTemp : 0|16@1- (0.3125,-273) [0|0] "degC/bit" Vector__XXX
 SG_ MeasuredMotorSpeed : 0|16@1- (0.5,0) [0|0] "rpm/bit" Vector__XXX
 SG_ AMTMode : 0|2@1- (1,0) [0|3] "SED" Vector__XXX
 SG_ AMTMode_BCM : 0|2@1- (1,0) [0|3] "SED" Vector__XXX
 SG_ RedStopLampState : 0|2@1+ (1,0) [0|3] "" Vector__XXX
 SG_ ProtectLampStatus : 0|2@1+ (1,0) [0|3] "" Vector__XXX
 SG_ FlashRedStopLamp : 0|2@1+ (1,0) [0|3] "" Vector__XXX
 SG_ FlashProtectLamp : 0|2@1+ (1,0) [0|3] "" Vector__XXX
 SG_ FlashMalfuncIndicatorLamp : 0|2@1+ (1,0) [0|3] "" Vector__XXX
 SG_ FlashAmberWarningLamp : 0|2@1+ (1,0) [0|3] "" Vector__XXX
 SG_ DTC5 : 0|32@1+ (1,0) [0|4294967295] "" Vector__XXX
 SG_ DTC4 : 0|32@1+ (1,0) [0|4294967295] "" Vector__XXX
 SG_ DTC3 : 0|32@1+ (1,0) [0|4294967295] "" Vector__XXX
 SG_ DTC2 : 0|32@1+ (1,0) [0|4294967295] "" Vector__XXX
 SG_ DTC1 : 0|32@1+ (1,0) [0|4294967295] "" Vector__XXX
 SG_ MalfunctionIndicatorLampStatus : 0|2@1+ (1,0) [0|3] "" Vector__XXX
 SG_ AmberWarningLampStatus : 0|2@1+ (1,0) [0|3] "" Vector__XXX
 SG_ RedStopLampState : 0|2@1+ (1,0) [0|3] "" Vector__XXX
 SG_ ProtectLampStatus : 0|2@1+ (1,0) [0|3] "" Vector__XXX
 SG_ DTC5 : 0|32@1+ (1,0) [0|4294967295] "" Vector__XXX
 SG_ DTC4 : 0|32@1+ (1,0) [0|4294967295] "" Vector__XXX
 SG_ DTC3 : 0|32@1+ (1,0) [0|4294967295] "" Vector__XXX
 SG_ DTC2 : 0|32@1+ (1,0) [0|4294967295] "" Vector__XXX
 SG_ DTC1 : 0|32@1+ (1,0) [0|4294967295] "" Vector__XXX
 SG_ ParkingBrakeSwitch_BCM : 0|2@1+ (1,0) [0|3] "" Vector__XXX
 SG_ ParkBrakeReleaseInhibitRq : 0|2@1+ (1,0) [0|3] "" Vector__XXX
 SG_ CruiseCtrlPauseSwitch : 0|2@1+ (1,0) [0|3] "" Vector__XXX
 SG_ TwoSpeedAxleSwitch : 0|2@1+ (1,0) [0|3] "" Vector__XXX
 SG_ BremsomatConfiguration : 0|3@1+ (1,0) [0|7] "" Vector__XXX
 SG_ TotalNumberOfPacketsEoMA : 0|8@1+ (1,0) [0|255] "" Vector__XXX
 SG_ TotalMessageSizeEoMA : 0|16@1+ (1,0) [0|64255] "counts" Vector__XXX
 SG_ TotalMessageSizeBAM : 0|16@1+ (1,0) [0|64255] "counts" Vector__XXX
 SG_ TotalNumberOfPacketsBAM : 0|8@1+ (1,0) [0|255] "" Vector__XXX
 SG_ ConnectionAbortReason : 0|8@1+ (1,0) [0|255] "" Vector__XXX
 SG_ NextPacketNumberToBeSent : 0|8@1+ (1,0) [0|255] "" Vector__XXX
 SG_ NumberOfPacketsThatCanBeSent : 0|8@1+ (1,0) [0|255] "" Vector__XXX
 SG_ PGNumber : 0|24@1+ (1,0) [0|16777200] "" Vector__XXX
 SG_ MaximumNumberOfPackets : 0|8@1+ (1,0) [0|255] "" Vector__XXX
 SG_ TotalNumberOfPackets : 0|8@1+ (1,0) [0|255] "" Vector__XXX
 SG_ TotalMessageSize : 0|16@1+ (1,0) [0|64255] "counts" Vector__XXX
 SG_ ControlByte : 0|8@1+ (1,0) [0|255] "" Vector__XXX
 SG_ SequenceNumber : 0|8@1+ (1,0) [0|255] "" Vector__XXX
 SG_ SPNConvMethod : 0|1@1+ (1,0) [0|1] "SED" Vector__XXX
 SG_ OccuranceCount : 0|7@1+ (1,0) [0|126] "" Vector__XXX
 SG_ FMI : 0|5@1+ (1,0) [0|31] "SED" Vector__XXX
 SG_ SPN_settozeroorPriofErr : 0|3@1+ (1,0) [0|7] "" Vector__XXX
 SG_ SPN_8LeastSigBitofSPN_2nd : 0|8@1+ (1,0) [0|255] "" Vector__XXX
 SG_ SPN_8LeastSigBitofSPN : 0|8@1+ (1,0) [0|255] "" Vector__XXX
 SG_ FlashRedStopLamp : 0|2@1+ (1,0) [0|3] "" Vector__XXX
 SG_ FlashProtectLamp : 0|2@1+ (1,0) [0|3] "" Vector__XXX
 SG_ FlashMalfuncIndicatorLamp : 0|2@1+ (1,0) [0|3] "" Vector__XXX
 SG_ FlashAmberWarningLamp : 0|2@1+ (1,0) [0|3] "" Vector__XXX
 SG_ MalfunctionIndicatorLampStatus : 0|2@1+ (1,0) [0|3] "" Vector__XXX
 SG_ AmberWarningLampStatus : 0|2@1+ (1,0) [0|3] "" Vector__XXX
 SG_ RedStopLampState : 0|2@1+ (1,0) [0|3] "" Vector__XXX
 SG_ ProtectLampStatus : 0|2@1+ (1,0) [0|3] "" Vector__XXX
 SG_ TesterReqPCCM : 0|64@1+ (1,0) [0|0] "" Vector__XXX
 SG_ TesterReqIntarder : 0|64@1+ (1,0) [0|0] "" Vector__XXX
 SG_ TesterReqEAPU : 0|64@1+ (1,0) [0|0] "" Vector__XXX
 SG_ TesterReqECM : 0|64@1+ (1,0) [0|0] "" Vector__XXX
 SG_ Memory2HeightRequest : 0|1@1+ (1,0) [0|1] "SED" Vector__XXX
 SG_ Memory2LevelSave : 0|1@1+ (1,0) [0|1] "SED" Vector__XXX
 SG_ Memory1LevelSave : 0|1@1+ (1,0) [0|1] "SED" Vector__XXX
 SG_ Memory1HeightRequest : 0|1@1+ (1,0) [0|1] "SED" Vector__XXX
 SG_ StopButtonPressed : 0|1@1+ (1,0) [0|1] "SED" Vector__XXX
 SG_ RideHeightRequest_RCU : 0|1@1+ (1,0) [0|1] "SED" Vector__XXX
 SG_ BremsomatSetSpeed : 0|8@1+ (1,0) [0|250] "km/h" Vector__XXX
 SG_ BremsomatControlPriority : 0|4@1+ (1,0) [0|15] "" Vector__XXX
 SG_ TransGearShiftInhibitRq : 0|2@1+ (1,0) [0|3] "SED" Vector__XXX
 SG_ RequestedPercentFanSpeed : 0|8@1+ (0.4,0) [0|100] "%" Vector__XXX
 SG_ Aftertreatment1OutletNOx : 0|16@1+ (0.05,-200) [-200|3012.75] "ppm" Vector__XXX
 SG_ UserLocationSelection : 0|2@1+ (1,0) [0|2] "" Vector__XXX

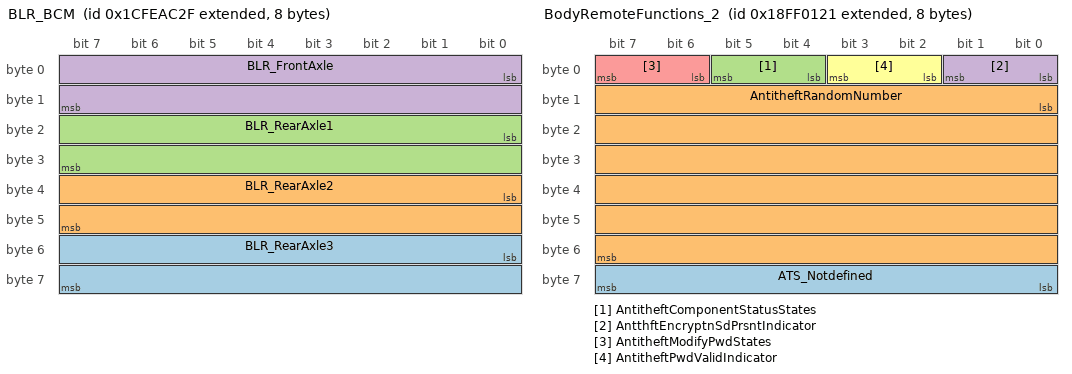
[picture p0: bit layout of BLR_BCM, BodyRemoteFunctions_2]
BO_ 2633935919 BLR_BCM: 8 BCM
 SG_ BLR_RearAxle3 : 48|16@1+ (10,0) [0|300000] "km/bit"  INSTRUMENT_CLUSTER
 SG_ BLR_RearAxle2 : 32|16@1+ (10,0) [0|300000] "km/bit"  INSTRUMENT_CLUSTER
 SG_ BLR_RearAxle1 : 16|16@1+ (10,0) [0|300000] "km/bit"  INSTRUMENT_CLUSTER
 SG_ BLR_FrontAxle : 0|16@1+ (10,0) [0|300000] "km/bit"  INSTRUMENT_CLUSTER

BO_ 2566848801 BodyRemoteFunctions_2: 8 BCM
 SG_ ATS_Notdefined : 56|8@1+ (1,0) [0|255] ""  PCCM
 SG_ AntitheftRandomNumber : 8|48@1+ (1,0) [0|4] ""  PCCM
 SG_ AntitheftComponentStatusStates : 4|2@1+ (1,0) [0|3] ""  PCCM
 SG_ AntthftEncryptnSdPrsntIndicator : 0|2@1+ (1,0) [0|3] ""  PCCM
 SG_ AntitheftModifyPwdStates : 6|2@1+ (1,0) [0|3] ""  PCCM
 SG_ AntitheftPwdValidIndicator : 2|2@1+ (1,0) [0|3] ""  PCCM

BO_ 2566848768 Prop_ECM_to_PCCM_Reserved2: 8 Vector__XXX
 SG_ dummy_ECM_to_PCCM : 0|8@1- (1,0) [0|0] ""  PCCM

BO_ 2566848512 Prop_ECM_to_PCCM_Reserved: 8 Vector__XXX
 SG_ dummy_ECm_to_PCCM : 0|8@1- (1,0) [0|0] ""  PCCM

BO_ 2564487683 UDSClientTCM_resp: 8 Vector__XXX
 SG_ SignalFiller1 : 32|32@1- (1,0) [0|0] ""  PCCM
 SG_ SignalFiller0 : 0|32@1- (1,0) [0|0] ""  PCCM

BO_ 2564488174 UDSClientTACHO_resp: 8 Vector__XXX
 SG_ SignalFiller1 : 32|32@1- (1,0) [0|0] ""  PCCM
 SG_ SignalFiller0 : 0|32@1- (1,0) [0|0] ""  PCCM

BO_ 2564485418 UDSClientRadar_resp: 8 Vector__XXX
 SG_ SignalFiller1 : 32|32@1- (1,0) [0|0] ""  PCCM
 SG_ SignalFiller0 : 0|32@1- (1,0) [0|0] ""  PCCM

BO_ 2564487696 UDSClientIntarder_resp: 8 Vector__XXX
 SG_ SignalFiller1 : 32|32@1- (1,0) [0|0] ""  PCCM
 SG_ SignalFiller0 : 0|32@1- (1,0) [0|0] ""  PCCM

BO_ 2564487680 UDSClientECM_resp: 8 Vector__XXX
 SG_ SignalFiller1 : 32|32@1- (1,0) [0|0] ""  PCCM
 SG_ SignalFiller0 : 0|32@1- (1,0) [0|0] ""  PCCM

BO_ 2564485387 UDSClientEBS_Resp: 8 Vector__XXX
 SG_ SignalFiller1 : 32|32@1- (1,0) [0|0] ""  PCCM
 SG_ SignalFiller0 : 0|32@1- (1,0) [0|0] ""  PCCM

BO_ 2564485399 UDSClientCluster_resp: 8 Vector__XXX
 SG_ SignalFiller1 : 32|32@1- (1,0) [0|0] ""  PCCM
 SG_ SignalFiller0 : 0|32@1- (1,0) [0|0] ""  PCCM

BO_ 2564485608 UDSClientCamera_resp: 8 Vector__XXX
 SG_ SignalFiller1 : 32|32@1- (1,0) [0|0] ""  PCCM
 SG_ SignalFiller0 : 0|32@1- (1,0) [0|0] ""  PCCM

BO_ 2566845212 Vehicle_Position: 8 PCCM

BO_ 2564436985 UDSClientTPMS_req: 8 PCCM
 SG_ SignalFiller1 : 32|32@1- (1,0) [0|0] "" Vector__XXX
 SG_ SignalFiller0 : 0|32@1- (1,0) [0|0] "" Vector__XXX

BO_ 2564424698 UDSClientTCM_req: 8 PCCM
 SG_ SignalFiller1 : 32|32@1- (1,0) [0|0] "" Vector__XXX
 SG_ SignalFiller0 : 0|32@1- (1,0) [0|0] "" Vector__XXX

BO_ 2564484859 UDSClientTACHO_req: 8 PCCM
 SG_ SignalFiller1 : 32|32@1- (1,0) [0|0] "" Vector__XXX
 SG_ SignalFiller0 : 0|32@1- (1,0) [0|0] "" Vector__XXX

BO_ 2564428026 UDSClientIntarder_req: 8 PCCM
 SG_ SignalFiller1 : 32|32@1- (1,0) [0|0] "" Vector__XXX
 SG_ SignalFiller0 : 0|32@1- (1,0) [0|0] "" Vector__XXX

BO_ 2564423930 UDSClientECM_req: 8 PCCM
 SG_ SignalFiller1 : 32|32@1- (1,0) [0|0] "" Vector__XXX
 SG_ SignalFiller0 : 0|32@1- (1,0) [0|0] "" Vector__XXX

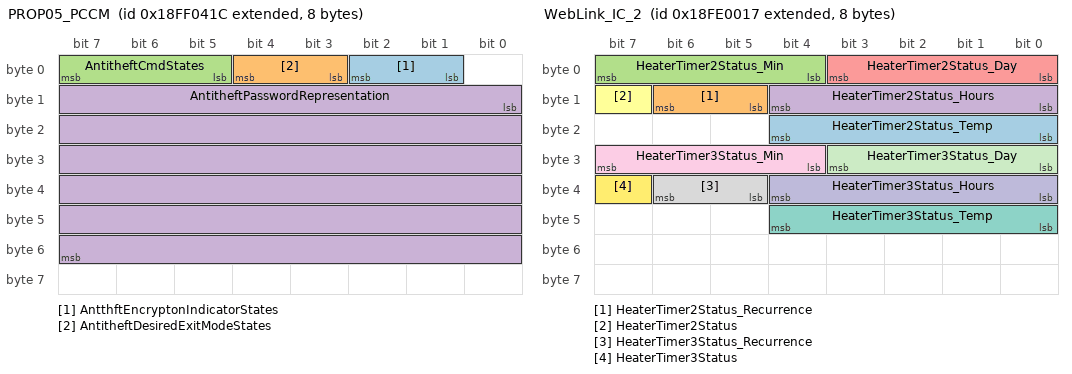
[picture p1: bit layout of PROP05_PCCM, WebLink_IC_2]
BO_ 2566849564 PROP05_PCCM: 8 PCCM
 SG_ AntthftEncryptonIndicatorStates : 1|2@1+ (1,0) [0|3] ""  BCM
 SG_ AntitheftDesiredExitModeStates : 3|2@1+ (1,0) [0|3] ""  BCM
 SG_ AntitheftCmdStates : 5|3@1+ (1,0) [0|7] ""  BCM
 SG_ AntitheftPasswordRepresentation : 8|48@1+ (1,0) [0|4] ""  BCM

BO_ 2566849308 PROP04_PCCM: 8 PCCM

BO_ 2566848545 BodyRemoteFunctionsStatus: 8 BCM
 SG_ HeaterStatus : 48|5@1+ (0.5,0) [15|30] ""  PCCM
 SG_ PassWinPosStatus : 45|3@1+ (1,0) [0|3] ""  PCCM
 SG_ DriverWinPosStatus : 42|3@1+ (1,0) [0|3] ""  PCCM
 SG_ GlobalLampStatus : 40|2@1+ (1,0) [0|3] ""  PCCM
 SG_ ParkLampStatus : 38|2@1+ (1,0) [0|3] ""  PCCM
 SG_ LowBeamStatus : 32|2@1+ (1,0) [0|3] ""  PCCM
 SG_ RmtCntrl_HighBeamStatus : 34|2@1+ (1,0) [0|3] ""  PCCM
 SG_ RearFogLampStatus : 36|2@1+ (1,0) [0|3] ""  PCCM
 SG_ PTOStatus : 29|2@1+ (1,0) [0|3] ""  PCCM
 SG_ ConnectionStatus : 6|2@1+ (1,0) [0|3] ""  PCCM
 SG_ FrontFogLampStatus : 27|2@1+ (1,0) [0|3] ""  PCCM
 SG_ TurnSignStatus : 24|3@1+ (1,0) [0|7] ""  PCCM
 SG_ DoorLockStatus : 22|2@1+ (1,0) [0|3] ""  PCCM
 SG_ SunroofStatus : 20|2@1+ (1,0) [0|3] ""  PCCM
 SG_ BedAreaLampDimmSt : 16|4@1+ (1,0) [0|15] ""  PCCM
 SG_ DomeLampDimmSt : 12|4@1+ (1,0) [0|15] ""  PCCM
 SG_ MapReadDimmLeftSt : 8|4@1+ (1,0) [0|15] ""  PCCM
 SG_ MapReadDimmRightSt : 2|4@1+ (1,0) [0|15] ""  PCCM
 SG_ AmbientLightSt : 0|2@1+ (1,0) [0|3] ""  PCCM

BO_ 2566782999 WebLink_IC_2: 8 INSTRUMENT_CLUSTER
 SG_ HeaterTimer2Status_Temp : 16|5@1+ (0.5,0) [15|30] "Degrees C"  PCCM,BCM
 SG_ HeaterTimer2Status_Recurrence : 13|2@1+ (1,0) [0|3] ""  PCCM,BCM
 SG_ HeaterTimer2Status_Min : 4|4@1+ (5,0) [0|55] "min"  PCCM,BCM
 SG_ HeaterTimer2Status_Hours : 8|5@1+ (1,0) [0|23] "h" Vector__XXX
 SG_ HeaterTimer2Status_Day : 0|4@1+ (1,0) [1|10] ""  PCCM,BCM
 SG_ HeaterTimer2Status : 15|1@1+ (1,0) [0|1] ""  PCCM,BCM
 SG_ HeaterTimer3Status_Temp : 40|5@1+ (0.5,0) [15|30] "Degrees C"  PCCM,BCM
 SG_ HeaterTimer3Status_Recurrence : 37|2@1+ (1,0) [0|3] ""  PCCM,BCM
 SG_ HeaterTimer3Status_Min : 28|4@1+ (5,0) [0|55] "min"  PCCM,BCM
 SG_ HeaterTimer3Status_Hours : 32|5@1+ (1,0) [0|23] "h" Vector__XXX
 SG_ HeaterTimer3Status_Day : 24|4@1+ (1,0) [1|10] ""  PCCM,BCM
 SG_ HeaterTimer3Status : 39|1@1+ (1,0) [0|1] ""  PCCM,BCM

BO_ 2566849052 BodyRemoteRequest: 8 PCCM
 SG_ HeaterReq : 56|5@1+ (0.5,0) [15|30] "Degrees C"  BCM
 SG_ WetFFHReq : 54|2@1+ (1,0) [0|3] ""  BCM
 SG_ DryFFHReq : 52|2@1+ (1,0) [0|3] ""  BCM
 SG_ CabTiltReq : 50|2@1+ (1,0) [0|3] ""  BCM
 SG_ PTOReq : 48|2@1+ (1,0) [0|3] ""  BCM
 SG_ EngStartReq : 46|2@1+ (1,0) [0|3] ""  BCM
 SG_ VolumeReq : 14|2@1+ (1,0) [0|3] ""  BCM
 SG_ RearFogLampReq : 44|2@1+ (1,0) [0|3] ""  BCM
 SG_ FrontFogLampReq : 42|2@1+ (1,0) [0|3] ""  BCM
 SG_ ParkLampReq : 40|2@1+ (1,0) [0|3] ""  BCM
 SG_ TurnSignReq : 36|3@1+ (1,0) [0|7] ""  BCM
 SG_ HighBeamSignReq : 34|2@1+ (1,0) [0|3] ""  BCM
 SG_ LowBeamSignReq : 32|2@1+ (1,0) [0|3] ""  BCM
 SG_ BedAreaLampDimmReq : 28|4@1+ (1,0) [0|15] "%"  BCM
 SG_ DomeLampDimmReq : 24|4@1+ (1,0) [0|15] "%"  BCM
 SG_ MapReadDimmL : 20|4@1+ (1,0) [0|15] "%"  BCM
 SG_ MapReadDimmR : 16|4@1+ (1,0) [0|15] "%"  BCM
 SG_ GlobLampOffReq : 12|2@1+ (1,0) [0|3] ""  BCM
 SG_ AmbLightReq : 10|2@1+ (1,0) [0|3] ""  BCM
 SG_ CentralLockUnlock : 8|2@1+ (1,0) [0|3] ""  BCM
 SG_ SunroofPos : 6|2@1+ (1,0) [0|3] ""  BCM
 SG_ PassWinPos : 4|2@1+ (1,0) [0|3] ""  BCM
 SG_ DriverWinPos : 2|2@1+ (1,0) [0|3] ""  BCM
 SG_ RemConnectionStatus : 0|2@1+ (1,0) [0|3] ""  BCM

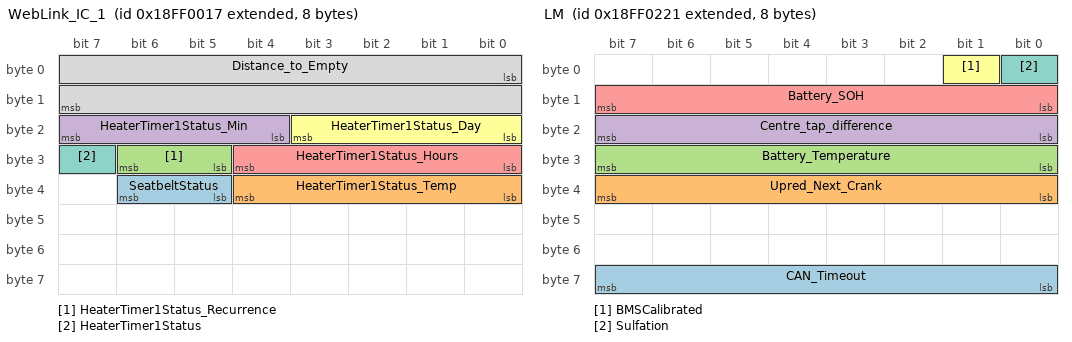
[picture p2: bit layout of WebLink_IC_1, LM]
BO_ 2566848535 WebLink_IC_1: 8 INSTRUMENT_CLUSTER
 SG_ SeatbeltStatus : 37|2@1+ (1,0) [0|3] ""  PCCM,BCM
 SG_ HeaterTimer1Status_Temp : 32|5@1+ (0.5,0) [15|30] "Degrees C"  PCCM,BCM
 SG_ HeaterTimer1Status_Recurrence : 29|2@1+ (1,0) [0|3] ""  PCCM,BCM
 SG_ HeaterTimer1Status_Min : 20|4@1+ (5,0) [0|55] "min"  PCCM,BCM
 SG_ HeaterTimer1Status_Hours : 24|5@1+ (1,0) [0|23] "h"  PCCM,BCM
 SG_ HeaterTimer1Status_Day : 16|4@1+ (1,0) [1|10] ""  PCCM,BCM
 SG_ HeaterTimer1Status : 31|1@1+ (1,0) [0|1] ""  PCCM,BCM
 SG_ Distance_to_Empty : 0|16@1+ (1,0) [0|65535] "km"  PCCM,BCM

BO_ 2566834694 DM1_LMFS: 64 LMFS
 SG_ SPNConvMethod : 47|1@1+ (1,0) [0|1] "SED"  INSTRUMENT_CLUSTER
 SG_ OccuranceCount : 40|7@1+ (1,0) [0|126] ""  INSTRUMENT_CLUSTER
 SG_ FMI : 32|5@1+ (1,0) [0|31] "SED"  INSTRUMENT_CLUSTER
 SG_ SPN_settozeroorPriofErr : 37|3@1+ (1,0) [0|7] ""  INSTRUMENT_CLUSTER
 SG_ SPN_8LeastSigBitofSPN_2nd : 24|8@1+ (1,0) [0|255] ""  INSTRUMENT_CLUSTER
 SG_ SPN_8LeastSigBitofSPN : 16|8@1+ (1,0) [0|255] ""  INSTRUMENT_CLUSTER
 SG_ FlashRedStopLamp : 12|2@1+ (1,0) [0|3] ""  INSTRUMENT_CLUSTER
 SG_ FlashProtectLamp : 8|2@1+ (1,0) [0|3] ""  INSTRUMENT_CLUSTER
 SG_ FlashMalfuncIndicatorLamp : 14|2@1+ (1,0) [0|3] ""  INSTRUMENT_CLUSTER
 SG_ FlashAmberWarningLamp : 10|2@1+ (1,0) [0|3] ""  INSTRUMENT_CLUSTER
 SG_ MalfunctionIndicatorLampStatus : 6|2@1+ (1,0) [0|3] ""  INSTRUMENT_CLUSTER
 SG_ AmberWarningLampStatus : 2|2@1+ (1,0) [0|3] ""  INSTRUMENT_CLUSTER
 SG_ RedStopLampState : 4|2@1+ (1,0) [0|3] ""  INSTRUMENT_CLUSTER
 SG_ ProtectLampStatus : 0|2@1+ (1,0) [0|3] ""  INSTRUMENT_CLUSTER

BO_ 2566834693 DM1_RMFS: 64 RMFS
 SG_ SPNConvMethod : 47|1@1+ (1,0) [0|1] "SED"  PCCM,INSTRUMENT_CLUSTER
 SG_ OccuranceCount : 40|7@1+ (1,0) [0|126] ""  PCCM,INSTRUMENT_CLUSTER
 SG_ FMI : 32|5@1+ (1,0) [0|31] "SED"  PCCM,INSTRUMENT_CLUSTER
 SG_ SPN_settozeroorPriofErr : 37|3@1+ (1,0) [0|7] ""  PCCM,INSTRUMENT_CLUSTER
 SG_ SPN_8LeastSigBitofSPN_2nd : 24|8@1+ (1,0) [0|255] ""  PCCM,INSTRUMENT_CLUSTER
 SG_ SPN_8LeastSigBitofSPN : 16|8@1+ (1,0) [0|255] ""  PCCM,INSTRUMENT_CLUSTER
 SG_ FlashRedStopLamp : 12|2@1+ (1,0) [0|3] ""  PCCM,INSTRUMENT_CLUSTER
 SG_ FlashProtectLamp : 8|2@1+ (1,0) [0|3] ""  PCCM,INSTRUMENT_CLUSTER
 SG_ FlashMalfuncIndicatorLamp : 14|2@1+ (1,0) [0|3] ""  PCCM,INSTRUMENT_CLUSTER
 SG_ FlashAmberWarningLamp : 10|2@1+ (1,0) [0|3] ""  PCCM,INSTRUMENT_CLUSTER
 SG_ MalfunctionIndicatorLampStatus : 6|2@1+ (1,0) [0|3] ""  PCCM,INSTRUMENT_CLUSTER
 SG_ AmberWarningLampStatus : 2|2@1+ (1,0) [0|3] ""  PCCM,INSTRUMENT_CLUSTER
 SG_ RedStopLampState : 4|2@1+ (1,0) [0|3] ""  PCCM,INSTRUMENT_CLUSTER
 SG_ ProtectLampStatus : 0|2@1+ (1,0) [0|3] ""  PCCM,INSTRUMENT_CLUSTER

BO_ 2566849057 LM: 8 BCM
 SG_ CAN_Timeout : 56|8@1+ (1,0) [0|255] ""  ENGINE_CONTROL_MODULE
 SG_ Upred_Next_Crank : 32|8@1+ (0.1,0) [0|254] "Volt"  ENGINE_CONTROL_MODULE
 SG_ Battery_Temperature : 24|8@1+ (1,-40) [0|254] ""  ENGINE_CONTROL_MODULE
 SG_ Centre_tap_difference : 16|8@1+ (1,-127) [0|254] "%"  ENGINE_CONTROL_MODULE
 SG_ Battery_SOH : 8|8@1+ (0.5,0) [0|200] "%"  ENGINE_CONTROL_MODULE
 SG_ BMSCalibrated : 1|1@1+ (1,0) [0|1] ""  ENGINE_CONTROL_MODULE
 SG_ Sulfation : 0|1@1+ (1,0) [0|1] ""  ENGINE_CONTROL_MODULE

BO_ 2565472256 RequestPGN: 3 ENGINE_CONTROL_MODULE
 SG_ ParameterGroupNumber : 0|24@1+ (1,0) [0|16777215] "" Vector__XXX

BO_ 2566835968 DM6_ECM: 22 ENGINE_CONTROL_MODULE
 SG_ OccuranceCount : 40|7@1+ (1,0) [0|126] "" Vector__XXX
 SG_ SPNConvMethod : 47|1@1+ (1,0) [0|1] "SED" Vector__XXX
 SG_ FMI : 32|5@1+ (1,0) [0|31] "SED" Vector__XXX
 SG_ SPN3 : 37|3@1+ (1,0) [0|7] "" Vector__XXX
 SG_ SPN2 : 24|8@1+ (1,0) [0|255] "" Vector__XXX
 SG_ SPN1 : 16|8@1+ (1,0) [0|255] "" Vector__XXX
 SG_ MalfuncIndicatorLampStatus_DM2 : 6|2@1+ (1,0) [0|1] "" Vector__XXX
 SG_ RedStopLampState_DM2 : 4|2@1+ (1,0) [0|1] "" Vector__XXX
 SG_ AmberWarningLampStatus_DM2 : 2|2@1+ (1,0) [0|1] "" Vector__XXX
 SG_ ProtectLampStatus_DM2 : 0|2@1+ (1,0) [0|1] "" Vector__XXX
 SG_ FlashRedStopLamp : 12|2@1+ (1,0) [0|3] "" Vector__XXX
 SG_ FlashProtectLamp : 8|2@1+ (1,0) [0|3] "" Vector__XXX
 SG_ FlashMalfuncIndicatorLamp : 14|2@1+ (1,0) [0|3] "" Vector__XXX
 SG_ FlashAmberWarningLamp : 10|2@1+ (1,0) [0|3] "" Vector__XXX

BO_ 2566834944 DM2_ECM: 64 ENGINE_CONTROL_MODULE
 SG_ OccuranceCount : 40|7@1+ (1,0) [0|126] "" Vector__XXX
 SG_ SPNConvMethod : 47|1@1+ (1,0) [0|1] "SED" Vector__XXX
 SG_ FMI : 32|5@1+ (1,0) [0|31] "SED" Vector__XXX
 SG_ SPN3 : 37|3@1+ (1,0) [0|7] "" Vector__XXX
 SG_ SPN2 : 24|8@1+ (1,0) [0|255] "" Vector__XXX
 SG_ SPN1 : 16|8@1+ (1,0) [0|255] "" Vector__XXX
 SG_ MalfuncIndicatorLampStatus_DM2 : 6|2@1+ (1,0) [0|1] "" Vector__XXX
 SG_ RedStopLampState_DM2 : 4|2@1+ (1,0) [0|1] "" Vector__XXX
 SG_ AmberWarningLampStatus_DM2 : 2|2@1+ (1,0) [0|1] "" Vector__XXX
 SG_ ProtectLampStatus_DM2 : 0|2@1+ (1,0) [0|1] "" Vector__XXX
 SG_ FlashRedStopLamp : 12|2@1+ (1,0) [0|3] "" Vector__XXX
 SG_ FlashProtectLamp : 8|2@1+ (1,0) [0|3] "" Vector__XXX
 SG_ FlashMalfuncIndicatorLamp : 14|2@1+ (1,0) [0|3] "" Vector__XXX
 SG_ FlashAmberWarningLamp : 10|2@1+ (1,0) [0|3] "" Vector__XXX

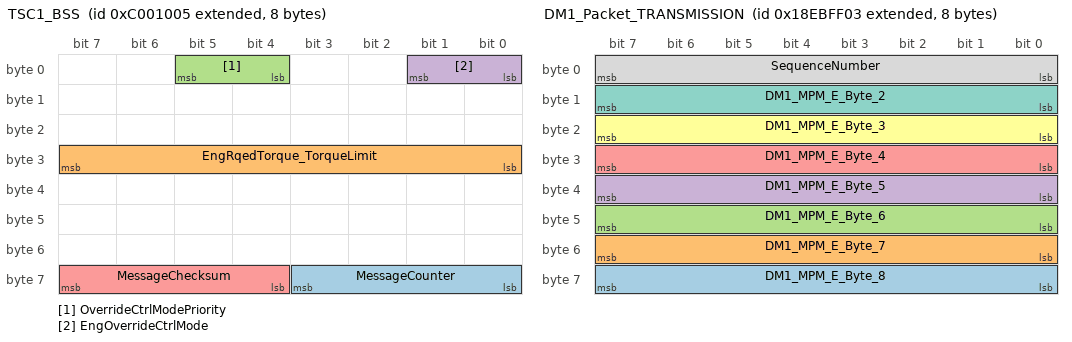
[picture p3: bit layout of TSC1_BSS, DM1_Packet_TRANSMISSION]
BO_ 2348814341 TSC1_BSS: 8 RMFS
 SG_ MessageCounter : 56|4@1+ (1,0) [0|15] ""  PCCM,INTARDER
 SG_ EngRqedTorque_TorqueLimit : 24|8@1+ (1,-125) [-125|125] "%"  PCCM,INTARDER
 SG_ OverrideCtrlModePriority : 4|2@1+ (1,0) [0|3] ""  PCCM,INTARDER
 SG_ EngOverrideCtrlMode : 0|2@1+ (1,0) [0|3] ""  PCCM,INTARDER
 SG_ MessageChecksum : 60|4@1+ (1,0) [0|15] ""  PCCM,INTARDER

BO_ 2632711987 TPDT_TPMS: 8 TPMS
 SG_ SequenceNumber : 0|8@1+ (1,0) [0|255] "" Vector__XXX

BO_ 2632777523 TPCM_TPMS: 8 TPMS
 SG_ PGNumber : 40|24@1+ (1,0) [0|16777200] "" Vector__XXX
 SG_ TotalNumberOfPackets m16 : 24|8@1+ (1,0) [0|255] "" Vector__XXX
 SG_ TotalMessageSize m16 : 8|16@1+ (1,0) [0|64255] "counts" Vector__XXX
 SG_ ControlByte M : 0|8@1+ (1,0) [0|255] "" Vector__XXX

BO_ 2633935619 ETC6_Transmission: 8 TRANSMISSION
 SG_ RecommendedGear : 0|8@1+ (1,-125) [-125|125] ""  PCCM

BO_ 2565603075 DM1_Packet_TRANSMISSION: 8 TRANSMISSION
 SG_ DM1_MPM_E_Byte_8 : 56|8@1+ (1,0) [0|255] "" Vector__XXX
 SG_ DM1_MPM_E_Byte_7 : 48|8@1+ (1,0) [0|255] "" Vector__XXX
 SG_ DM1_MPM_E_Byte_6 : 40|8@1+ (1,0) [0|255] "" Vector__XXX
 SG_ DM1_MPM_E_Byte_5 : 32|8@1+ (1,0) [0|255] "" Vector__XXX
 SG_ DM1_MPM_E_Byte_4 : 24|8@1+ (1,0) [0|255] "" Vector__XXX
 SG_ DM1_MPM_E_Byte_3 : 16|8@1+ (1,0) [0|255] "" Vector__XXX
 SG_ DM1_MPM_E_Byte_2 : 8|8@1+ (1,0) [0|255] "" Vector__XXX
 SG_ SequenceNumber : 0|8@1+ (1,0) [0|255] "" Vector__XXX

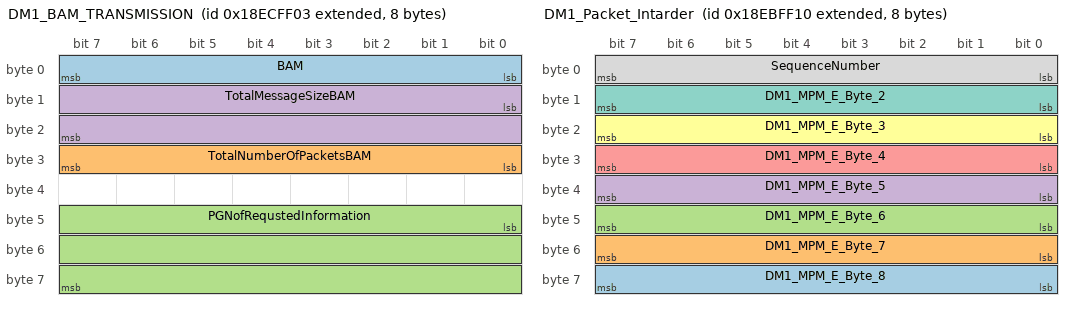
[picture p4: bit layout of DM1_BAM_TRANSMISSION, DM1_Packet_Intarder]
BO_ 2565668611 DM1_BAM_TRANSMISSION: 8 TRANSMISSION
 SG_ BAM : 0|8@1+ (1,0) [0|32] "1/bit" Vector__XXX
 SG_ TotalNumberOfPacketsBAM : 24|8@1+ (1,0) [0|255] "" Vector__XXX
 SG_ PGNofRequstedInformation : 40|24@1+ (1,0) [0|16777215] "" Vector__XXX
 SG_ TotalMessageSizeBAM : 8|16@1+ (1,0) [0|64255] "counts" Vector__XXX

BO_ 2565603088 DM1_Packet_Intarder: 8 INTARDER
 SG_ DM1_MPM_E_Byte_8 : 56|8@1+ (1,0) [0|255] "" Vector__XXX
 SG_ DM1_MPM_E_Byte_7 : 48|8@1+ (1,0) [0|255] "" Vector__XXX
 SG_ DM1_MPM_E_Byte_6 : 40|8@1+ (1,0) [0|255] "" Vector__XXX
 SG_ DM1_MPM_E_Byte_5 : 32|8@1+ (1,0) [0|255] "" Vector__XXX
 SG_ DM1_MPM_E_Byte_4 : 24|8@1+ (1,0) [0|255] "" Vector__XXX
 SG_ DM1_MPM_E_Byte_3 : 16|8@1+ (1,0) [0|255] "" Vector__XXX
 SG_ DM1_MPM_E_Byte_2 : 8|8@1+ (1,0) [0|255] "" Vector__XXX
 SG_ SequenceNumber : 0|8@1+ (1,0) [0|255] "" Vector__XXX

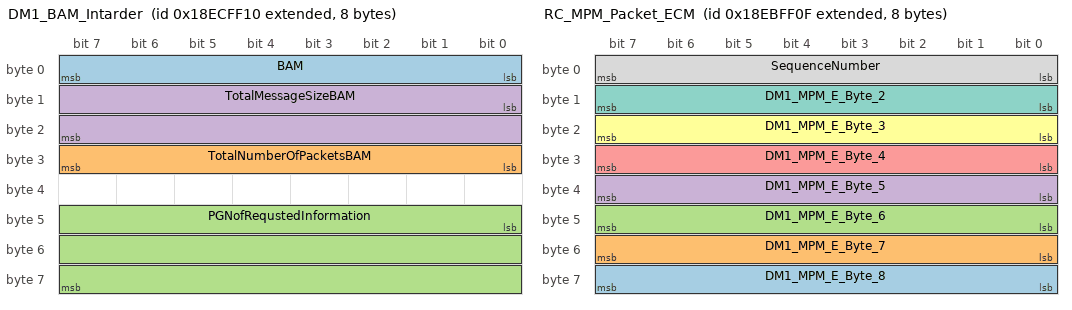
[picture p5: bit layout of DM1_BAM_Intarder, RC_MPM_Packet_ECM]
BO_ 2565668624 DM1_BAM_Intarder: 8 INTARDER
 SG_ BAM : 0|8@1+ (1,0) [0|32] "1/bit" Vector__XXX
 SG_ TotalNumberOfPacketsBAM : 24|8@1+ (1,0) [0|255] "" Vector__XXX
 SG_ PGNofRequstedInformation : 40|24@1+ (1,0) [0|16777215] "" Vector__XXX
 SG_ TotalMessageSizeBAM : 8|16@1+ (1,0) [0|64255] "counts" Vector__XXX

BO_ 2565603087 RC_MPM_Packet_ECM: 8 ENGINE_CONTROL_MODULE
 SG_ DM1_MPM_E_Byte_8 : 56|8@1+ (1,0) [0|255] "" Vector__XXX
 SG_ DM1_MPM_E_Byte_7 : 48|8@1+ (1,0) [0|255] "" Vector__XXX
 SG_ DM1_MPM_E_Byte_6 : 40|8@1+ (1,0) [0|255] "" Vector__XXX
 SG_ DM1_MPM_E_Byte_5 : 32|8@1+ (1,0) [0|255] "" Vector__XXX
 SG_ DM1_MPM_E_Byte_4 : 24|8@1+ (1,0) [0|255] "" Vector__XXX
 SG_ DM1_MPM_E_Byte_3 : 16|8@1+ (1,0) [0|255] "" Vector__XXX
 SG_ DM1_MPM_E_Byte_2 : 8|8@1+ (1,0) [0|255] "" Vector__XXX
 SG_ SequenceNumber : 0|8@1+ (1,0) [0|255] "" Vector__XXX

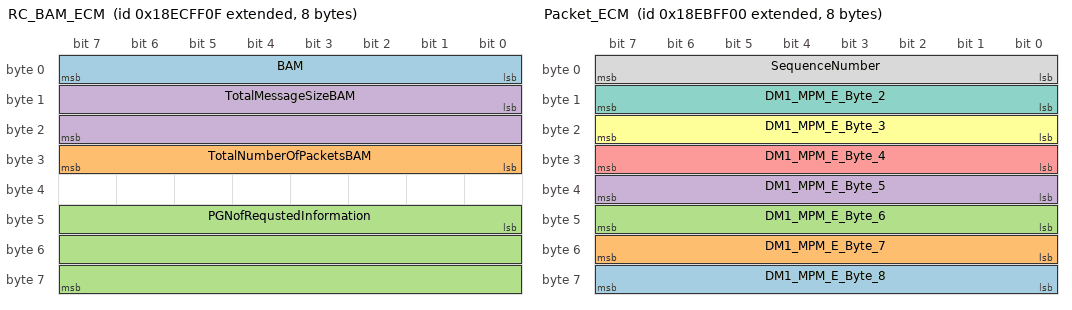
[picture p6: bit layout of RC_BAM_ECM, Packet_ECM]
BO_ 2565668623 RC_BAM_ECM: 8 ENGINE_CONTROL_MODULE
 SG_ BAM : 0|8@1+ (1,0) [0|32] "1/bit" Vector__XXX
 SG_ TotalNumberOfPacketsBAM : 24|8@1+ (1,0) [0|255] "" Vector__XXX
 SG_ PGNofRequstedInformation : 40|24@1+ (1,0) [0|16777215] "" Vector__XXX
 SG_ TotalMessageSizeBAM : 8|16@1+ (1,0) [0|64255] "counts" Vector__XXX

BO_ 2565603072 Packet_ECM: 8 ENGINE_CONTROL_MODULE
 SG_ DM1_MPM_E_Byte_8 : 56|8@1+ (1,0) [0|255] "" Vector__XXX
 SG_ DM1_MPM_E_Byte_7 : 48|8@1+ (1,0) [0|255] "" Vector__XXX
 SG_ DM1_MPM_E_Byte_6 : 40|8@1+ (1,0) [0|255] "" Vector__XXX
 SG_ DM1_MPM_E_Byte_5 : 32|8@1+ (1,0) [0|255] "" Vector__XXX
 SG_ DM1_MPM_E_Byte_4 : 24|8@1+ (1,0) [0|255] "" Vector__XXX
 SG_ DM1_MPM_E_Byte_3 : 16|8@1+ (1,0) [0|255] "" Vector__XXX
 SG_ DM1_MPM_E_Byte_2 : 8|8@1+ (1,0) [0|255] "" Vector__XXX
 SG_ SequenceNumber : 0|8@1+ (1,0) [0|255] "" Vector__XXX

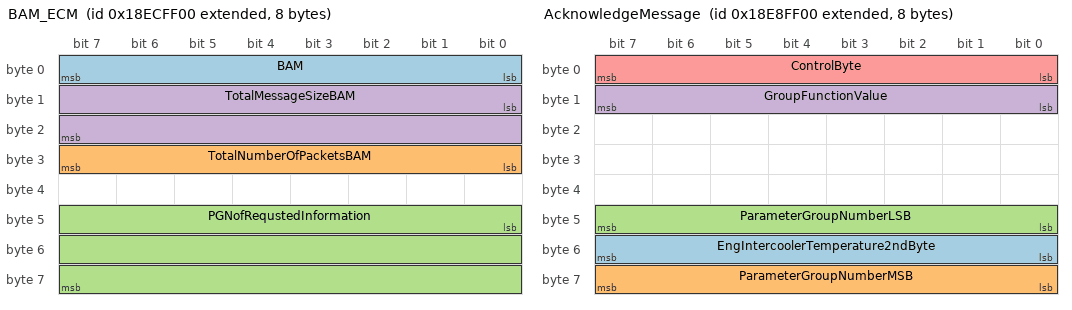
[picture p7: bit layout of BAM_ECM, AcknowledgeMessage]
BO_ 2565668608 BAM_ECM: 8 ENGINE_CONTROL_MODULE
 SG_ BAM : 0|8@1+ (1,0) [0|32] "1/bit" Vector__XXX
 SG_ TotalNumberOfPacketsBAM : 24|8@1+ (1,0) [0|255] "" Vector__XXX
 SG_ PGNofRequstedInformation : 40|24@1+ (1,0) [0|16777215] "" Vector__XXX
 SG_ TotalMessageSizeBAM : 8|16@1+ (1,0) [0|64255] "counts" Vector__XXX

BO_ 2565406464 AcknowledgeMessage: 8 ENGINE_CONTROL_MODULE
 SG_ EngIntercoolerTemperature2ndByte : 48|8@1+ (1,0) [0|255] "" Vector__XXX
 SG_ ParameterGroupNumberMSB : 56|8@1+ (1,0) [0|255] "" Vector__XXX
 SG_ ParameterGroupNumberLSB : 40|8@1+ (1,0) [0|255] "" Vector__XXX
 SG_ GroupFunctionValue : 8|8@1+ (1,0) [0|255] "" Vector__XXX
 SG_ ControlByte : 0|8@1+ (1,0) [0|255] "" Vector__XXX

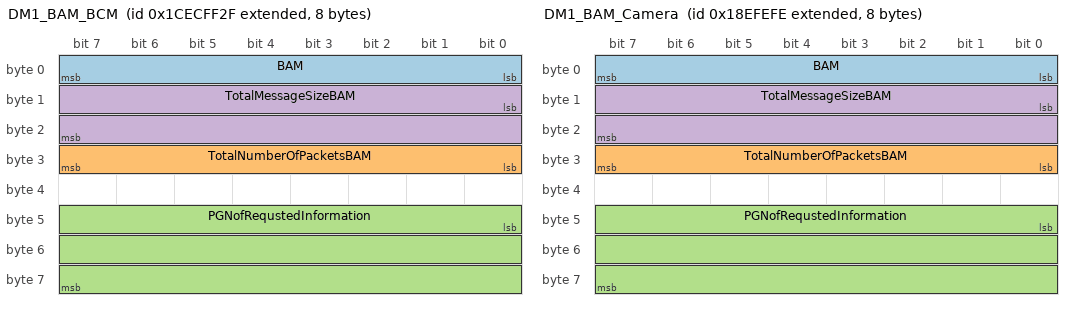
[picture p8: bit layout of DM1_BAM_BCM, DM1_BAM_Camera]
BO_ 2632777519 DM1_BAM_BCM: 8 Vector__XXX
 SG_ BAM : 0|8@1- (1,0) [0|32] "1/bit" Vector__XXX
 SG_ TotalNumberOfPacketsBAM : 24|8@1+ (1,0) [0|255] "" Vector__XXX
 SG_ PGNofRequstedInformation : 40|24@1+ (1,0) [0|16777215] "" Vector__XXX
 SG_ TotalMessageSizeBAM : 8|16@1+ (1,0) [0|64255] "counts" Vector__XXX

BO_ 2173632254 DM1_BAM_Camera: 8 Vector__XXX
 SG_ BAM : 0|8@1- (1,0) [0|32] "1/bit" Vector__XXX
 SG_ TotalNumberOfPacketsBAM : 24|8@1+ (1,0) [0|255] "" Vector__XXX
 SG_ PGNofRequstedInformation : 40|24@1+ (1,0) [0|16777215] "" Vector__XXX
 SG_ TotalMessageSizeBAM : 8|16@1+ (1,0) [0|64255] "counts" Vector__XXX

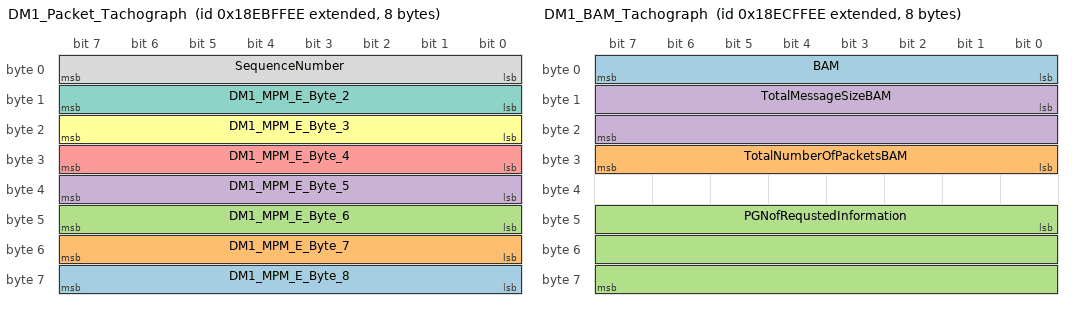
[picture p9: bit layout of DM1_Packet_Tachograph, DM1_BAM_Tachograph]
BO_ 2565603310 DM1_Packet_Tachograph: 8 TACHOGRAPH
 SG_ DM1_MPM_E_Byte_8 : 56|8@1+ (1,0) [0|255] "" Vector__XXX
 SG_ DM1_MPM_E_Byte_7 : 48|8@1+ (1,0) [0|255] "" Vector__XXX
 SG_ DM1_MPM_E_Byte_6 : 40|8@1+ (1,0) [0|255] "" Vector__XXX
 SG_ DM1_MPM_E_Byte_5 : 32|8@1+ (1,0) [0|255] "" Vector__XXX
 SG_ DM1_MPM_E_Byte_4 : 24|8@1+ (1,0) [0|255] "" Vector__XXX
 SG_ DM1_MPM_E_Byte_3 : 16|8@1+ (1,0) [0|255] "" Vector__XXX
 SG_ DM1_MPM_E_Byte_2 : 8|8@1+ (1,0) [0|255] "" Vector__XXX
 SG_ SequenceNumber : 0|8@1+ (1,0) [0|255] "" Vector__XXX

BO_ 2565668846 DM1_BAM_Tachograph: 8 TACHOGRAPH
 SG_ BAM : 0|8@1+ (1,0) [0|32] "1/bit" Vector__XXX
 SG_ TotalNumberOfPacketsBAM : 24|8@1+ (1,0) [0|255] "" Vector__XXX
 SG_ PGNofRequstedInformation : 40|24@1+ (1,0) [0|16777215] "" Vector__XXX
 SG_ TotalMessageSizeBAM : 8|16@1+ (1,0) [0|64255] "counts" Vector__XXX

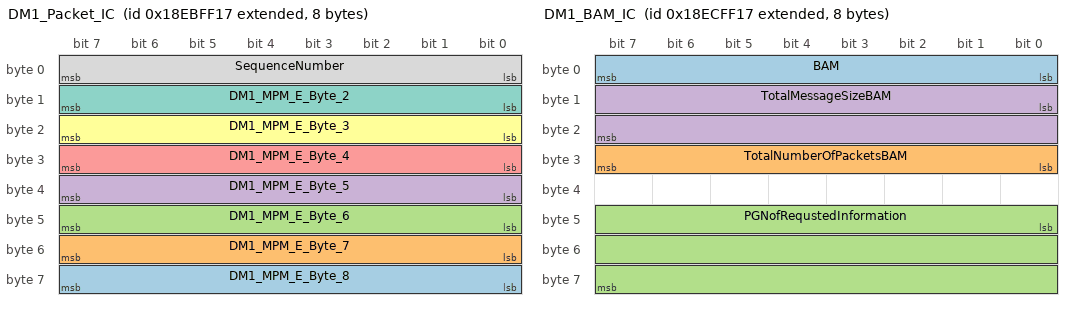
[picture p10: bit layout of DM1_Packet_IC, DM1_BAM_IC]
BO_ 2565603095 DM1_Packet_IC: 8 INSTRUMENT_CLUSTER
 SG_ DM1_MPM_E_Byte_8 : 56|8@1+ (1,0) [0|255] "" Vector__XXX
 SG_ DM1_MPM_E_Byte_7 : 48|8@1+ (1,0) [0|255] "" Vector__XXX
 SG_ DM1_MPM_E_Byte_6 : 40|8@1+ (1,0) [0|255] "" Vector__XXX
 SG_ DM1_MPM_E_Byte_5 : 32|8@1+ (1,0) [0|255] "" Vector__XXX
 SG_ DM1_MPM_E_Byte_4 : 24|8@1+ (1,0) [0|255] "" Vector__XXX
 SG_ DM1_MPM_E_Byte_3 : 16|8@1+ (1,0) [0|255] "" Vector__XXX
 SG_ DM1_MPM_E_Byte_2 : 8|8@1+ (1,0) [0|255] "" Vector__XXX
 SG_ SequenceNumber : 0|8@1+ (1,0) [0|255] "" Vector__XXX

BO_ 2565668631 DM1_BAM_IC: 8 INSTRUMENT_CLUSTER
 SG_ BAM : 0|8@1+ (1,0) [0|32] "1/bit" Vector__XXX
 SG_ TotalNumberOfPacketsBAM : 24|8@1+ (1,0) [0|255] "" Vector__XXX
 SG_ PGNofRequstedInformation : 40|24@1+ (1,0) [0|16777215] "" Vector__XXX
 SG_ TotalMessageSizeBAM : 8|16@1+ (1,0) [0|64255] "counts" Vector__XXX

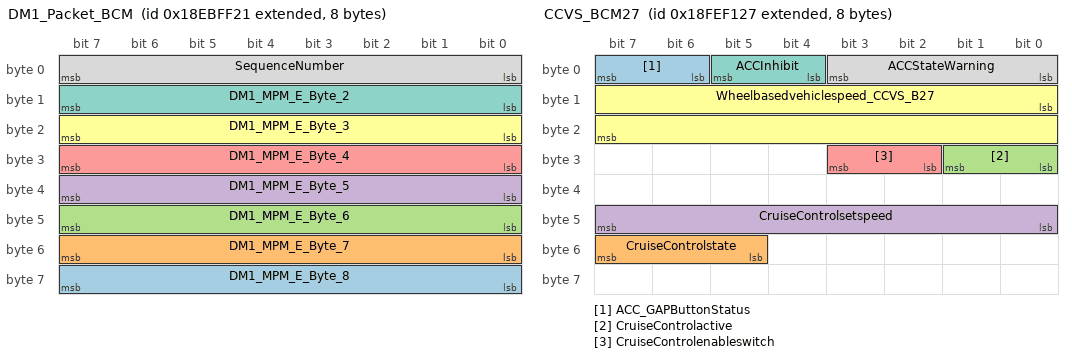
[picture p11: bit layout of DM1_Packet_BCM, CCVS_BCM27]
BO_ 2565603105 DM1_Packet_BCM: 8 BCM
 SG_ DM1_MPM_E_Byte_8 : 56|8@1+ (1,0) [0|255] ""  INSTRUMENT_CLUSTER
 SG_ DM1_MPM_E_Byte_7 : 48|8@1+ (1,0) [0|255] ""  INSTRUMENT_CLUSTER
 SG_ DM1_MPM_E_Byte_6 : 40|8@1+ (1,0) [0|255] ""  INSTRUMENT_CLUSTER
 SG_ DM1_MPM_E_Byte_5 : 32|8@1+ (1,0) [0|255] ""  INSTRUMENT_CLUSTER
 SG_ DM1_MPM_E_Byte_4 : 24|8@1+ (1,0) [0|255] ""  INSTRUMENT_CLUSTER
 SG_ DM1_MPM_E_Byte_3 : 16|8@1+ (1,0) [0|255] ""  INSTRUMENT_CLUSTER
 SG_ DM1_MPM_E_Byte_2 : 8|8@1+ (1,0) [0|255] ""  INSTRUMENT_CLUSTER
 SG_ SequenceNumber : 0|8@1+ (1,0) [0|255] ""  INSTRUMENT_CLUSTER

BO_ 2565668641 DM1_BAM_E_BCM: 8 BCM
 SG_ TotalNumberOfPacketsEoMA m19 : 24|8@1+ (1,0) [0|255] ""  INSTRUMENT_CLUSTER
 SG_ TotalMessageSizeEoMA m19 : 8|16@1+ (1,0) [0|64255] "counts"  INSTRUMENT_CLUSTER
 SG_ TotalMessageSizeBAM m32 : 8|16@1+ (1,0) [0|64255] "counts"  INSTRUMENT_CLUSTER
 SG_ TotalNumberOfPacketsBAM m32 : 24|8@1+ (1,0) [0|255] ""  INSTRUMENT_CLUSTER
 SG_ ConnectionAbortReason m255 : 8|8@1+ (1,0) [0|255] ""  INSTRUMENT_CLUSTER
 SG_ NextPacketNumberToBeSent m17 : 16|8@1+ (1,0) [0|255] ""  INSTRUMENT_CLUSTER
 SG_ NumberOfPacketsThatCanBeSent m17 : 8|8@1+ (1,0) [0|255] ""  INSTRUMENT_CLUSTER
 SG_ PGNumber : 40|24@1+ (1,0) [0|16777200] ""  INSTRUMENT_CLUSTER
 SG_ MaximumNumberOfPackets m16 : 32|8@1+ (1,0) [0|255] ""  INSTRUMENT_CLUSTER
 SG_ TotalNumberOfPackets m16 : 24|8@1+ (1,0) [0|255] ""  INSTRUMENT_CLUSTER
 SG_ TotalMessageSize m16 : 8|16@1+ (1,0) [0|64255] "counts"  INSTRUMENT_CLUSTER
 SG_ ControlByte M : 0|8@1+ (1,0) [0|255] ""  INSTRUMENT_CLUSTER

BO_ 2565537768 RQST_CAMERA: 8 CAMERA
 SG_ ParameterGroupNumber : 0|24@1+ (1,0) [0|16777215] "" Vector__XXX

BO_ 2565537578 RQST_RADAR: 8 RADAR
 SG_ ParameterGroupNumber : 0|24@1+ (1,0) [0|16777215] "" Vector__XXX

BO_ 2565864243 STDEBUGMUXMESSAGE: 8 TPMS

BO_ 2566844711 CCVS_BCM27: 8 BCM
 SG_ ACC_GAPButtonStatus : 6|2@1+ (1,0) [0|3] "" Vector__XXX
 SG_ CruiseControlstate : 53|3@1+ (1,0) [0|7] "SED"  INSTRUMENT_CLUSTER,RADAR,CAMERA
 SG_ CruiseControlactive : 24|2@1+ (1,0) [0|3] "SED"  INSTRUMENT_CLUSTER,RADAR,CAMERA
 SG_ CruiseControlsetspeed : 40|8@1+ (1,0) [0|250] "km/h"  INSTRUMENT_CLUSTER,RADAR,CAMERA
 SG_ CruiseControlenableswitch : 26|2@1+ (1,0) [0|3] ""  INSTRUMENT_CLUSTER,RADAR,CAMERA
 SG_ Wheelbasedvehiclespeed_CCVS_B27 : 8|16@1+ (0.00390625,0) [0|251] "km/h"  INSTRUMENT_CLUSTER,RADAR,CAMERA
 SG_ ACCInhibit : 4|2@1+ (1,0) [0|3] "SED"  INSTRUMENT_CLUSTER,RADAR,CAMERA
 SG_ ACCStateWarning : 0|4@1+ (1,0) [0|15] "SED"  INSTRUMENT_CLUSTER,RADAR,CAMERA

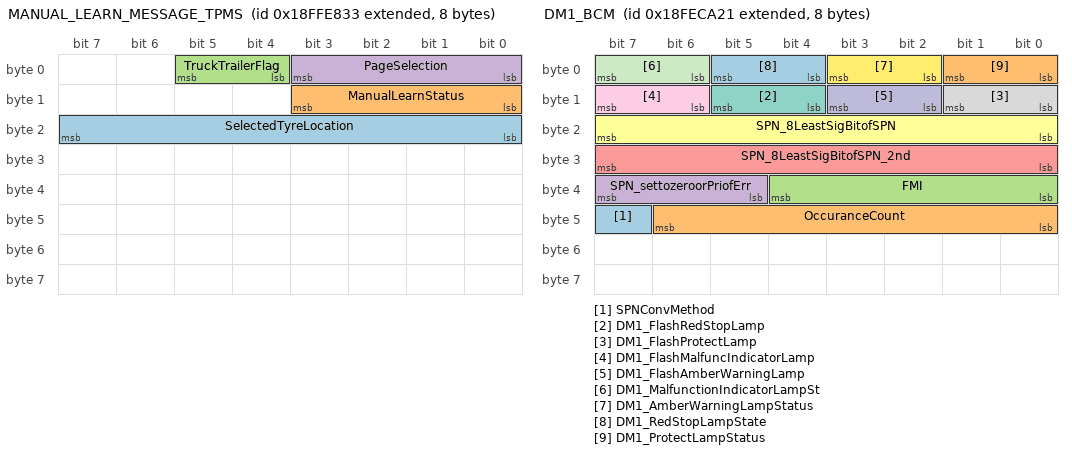
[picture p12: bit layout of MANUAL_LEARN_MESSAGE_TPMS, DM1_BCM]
BO_ 2566907955 MANUAL_LEARN_MESSAGE_TPMS: 8 TPMS
 SG_ SelectedTyreLocation : 16|8@1+ (1,0) [0|255] "SED"  INSTRUMENT_CLUSTER
 SG_ ManualLearnStatus : 8|4@1+ (1,0) [0|15] "SED"  INSTRUMENT_CLUSTER
 SG_ TruckTrailerFlag : 4|2@1+ (1,0) [0|3] "SED"  INSTRUMENT_CLUSTER
 SG_ PageSelection : 0|4@1+ (1,0) [0|15] "SED"  INSTRUMENT_CLUSTER

BO_ 2565668606 DM1_BAM_E_ECAS_BCM: 8 Vector__XXX

BO_ 2565603070 DM1_Packet_ECAS_BCM: 8 Vector__XXX

BO_ 2566834735 DM1_BCM_ECAS: 8 Vector__XXX

BO_ 2566834721 DM1_BCM: 8 BCM
 SG_ SPNConvMethod : 47|1@1+ (1,0) [0|1] "SED"  PCCM,INSTRUMENT_CLUSTER
 SG_ OccuranceCount : 40|7@1+ (1,0) [0|126] ""  PCCM,INSTRUMENT_CLUSTER
 SG_ FMI : 32|5@1+ (1,0) [0|31] "SED"  PCCM,INSTRUMENT_CLUSTER
 SG_ SPN_settozeroorPriofErr : 37|3@1+ (1,0) [0|7] ""  PCCM,INSTRUMENT_CLUSTER
 SG_ SPN_8LeastSigBitofSPN_2nd : 24|8@1+ (1,0) [0|255] ""  PCCM,INSTRUMENT_CLUSTER
 SG_ SPN_8LeastSigBitofSPN : 16|8@1+ (1,0) [0|255] ""  PCCM,INSTRUMENT_CLUSTER
 SG_ DM1_FlashRedStopLamp : 12|2@1+ (1,0) [0|3] ""  PCCM,INSTRUMENT_CLUSTER
 SG_ DM1_FlashProtectLamp : 8|2@1+ (1,0) [0|3] ""  PCCM,INSTRUMENT_CLUSTER
 SG_ DM1_FlashMalfuncIndicatorLamp : 14|2@1+ (1,0) [0|3] ""  PCCM,INSTRUMENT_CLUSTER
 SG_ DM1_FlashAmberWarningLamp : 10|2@1+ (1,0) [0|3] ""  PCCM,INSTRUMENT_CLUSTER
 SG_ DM1_MalfunctionIndicatorLampSt : 6|2@1+ (1,0) [0|3] ""  PCCM,INSTRUMENT_CLUSTER
 SG_ DM1_AmberWarningLampStatus : 2|2@1+ (1,0) [0|3] ""  PCCM,INSTRUMENT_CLUSTER
 SG_ DM1_RedStopLampState : 4|2@1+ (1,0) [0|3] ""  PCCM,INSTRUMENT_CLUSTER
 SG_ DM1_ProtectLampStatus : 0|2@1+ (1,0) [0|3] ""  PCCM,INSTRUMENT_CLUSTER

BO_ 2566852650 TransmitFLRProp: 8 RADAR
 SG_ CMTInstalledandEnabled : 54|1@1+ (1,0) [0|1] "SED"  ENGINE_CONTROL_MODULE,BCM
 SG_ TSRWarningFlag : 63|1@1+ (1,0) [0|1] "SED"  ENGINE_CONTROL_MODULE,BCM
 SG_ TSROveruse : 62|1@1+ (1,0) [0|1] "SED"  ENGINE_CONTROL_MODULE,BCM
 SG_ TSRSpeedLimit : 56|6@1+ (5,0) [0|63] "Speed/Kph"  ENGINE_CONTROL_MODULE,BCM
 SG_ FusionEnableFlag : 55|1@1+ (1,0) [0|1] "SED"  ENGINE_CONTROL_MODULE,BCM
 SG_ FLRErrorStatus : 53|1@1+ (1,0) [0|1] "SED"  ENGINE_CONTROL_MODULE,BCM
 SG_ CMTFoundationBrakeRequest : 52|1@1+ (1,0) [0|1] "SED"  ENGINE_CONTROL_MODULE,BCM
 SG_ CMTInterventionStatus : 51|1@1+ (1,0) [0|1] "SED"  ENGINE_CONTROL_MODULE,BCM
 SG_ AEBPossible : 50|1@1+ (1,0) [0|1] "SED"  ENGINE_CONTROL_MODULE,BCM
 SG_ BendixPowerOnSelfTest : 48|2@1+ (1,0) [0|3] "SED"  ENGINE_CONTROL_MODULE,BCM
 SG_ TargetFusedIndicator : 47|1@1+ (1,0) [0|1] "SED"  ENGINE_CONTROL_MODULE,BCM
 SG_ FusionAvailableFlag : 46|1@1+ (1,0) [0|1] "SED"  ENGINE_CONTROL_MODULE,BCM
 SG_ WingmanSensorBlockedNoObjectsDet : 44|2@1+ (1,0) [0|3] "SED"  ENGINE_CONTROL_MODULE,BCM
 SG_ WingmanTargetDetectLamp : 42|2@1+ (1,0) [0|3] "SED"  ENGINE_CONTROL_MODULE,BCM
 SG_ CruiseControlONTelltale : 40|2@1+ (1,0) [0|3] "SED"  ENGINE_CONTROL_MODULE,BCM
 SG_ VehicleCruiseControlSetSpeed : 32|8@1+ (1,0) [0|255] "Speed/Mph"  ENGINE_CONTROL_MODULE,BCM
 SG_ VehicleFollowingInterval : 24|8@1+ (0.125,0) [0|255] "Seconds"  ENGINE_CONTROL_MODULE,BCM
 SG_ VehicleFollowingDistance : 16|8@1+ (2,0) [0|255] "Distance/Feet"  ENGINE_CONTROL_MODULE,BCM
 SG_ ACBDisDueToExcBrakeUse : 14|2@1+ (1,0) [0|3] "D"  ENGINE_CONTROL_MODULE,BCM
 SG_ VisualFollowingDistanceAlertRec : 11|3@1+ (1,0) [0|7] "SED"  ENGINE_CONTROL_MODULE,BCM
 SG_ AudibleFollowingDistanceAlertRec : 8|3@1+ (1,0) [0|7] "SED"  ENGINE_CONTROL_MODULE,BCM
 SG_ NetVehFollowingDistanceInterval : 0|8@1+ (0.125,0) [0|255] "Seconds"  ENGINE_CONTROL_MODULE,BCM

BO_ 2566849866 ERAGLONAS_DTC: 8 TCU_ERAGLONASS
 SG_ VINACK_status : 40|3@1+ (1,0) [0|5] "" Vector__XXX
 SG_ Comm_module_failure : 28|2@1+ (1,0) [0|3] "SED"  BCM
 SG_ Last_failure : 38|2@1+ (1,0) [0|3] "SED"  BCM
 SG_ Other_not_critical_failures : 36|2@1+ (1,0) [0|3] "SED"  BCM
 SG_ Other_critical_failures : 34|2@1+ (1,0) [0|3] "SED"  BCM
 SG_ Crash_profile_memory_overflow : 32|2@1+ (1,0) [0|3] "SED"  BCM
 SG_ Events_memory_overflow : 30|2@1+ (1,0) [0|3] "SED"  BCM
 SG_ Gnss_antenna_failure : 26|2@1+ (1,0) [0|3] "SED"  BCM
 SG_ Raim_problem : 24|2@1+ (1,0) [0|3] "SED"  BCM
 SG_ Gnss_receiver_failure : 22|2@1+ (1,0) [0|3] "SED"  BCM
 SG_ Comm_module_iterface_failure : 20|2@1+ (1,0) [0|3] "SED"  BCM
 SG_ Firmware_image_corruption : 18|2@1+ (1,0) [0|3] "SED"  BCM
 SG_ Crash_sens_failure : 16|2@1+ (1,0) [0|3] "SED"  BCM
 SG_ Battery_voltage_low : 14|2@1+ (1,0) [0|3] "SED"  BCM
 SG_ Battery_failure : 12|2@1+ (1,0) [0|3] "SED"  BCM
 SG_ Status_indicator_failure : 10|2@1+ (1,0) [0|3] "SED"  BCM
 SG_ Uim_failure : 8|2@1+ (1,0) [0|3] "SED"  BCM
 SG_ Ignition_line_failure : 6|2@1+ (1,0) [0|3] "SED"  BCM
 SG_ Speakers_failure : 4|2@1+ (1,0) [0|3] "SED"  BCM
 SG_ Mic_failure : 2|2@1+ (1,0) [0|3] "SED"  BCM
 SG_ Mic_connection_failure : 0|2@1+ (1,0) [0|3] "SED"  BCM

BO_ 2566856958 RCU: 8 Vector__XXX
 SG_ DriverRequestRCU : 0|8@1+ (1,0) [0|8] "" Vector__XXX

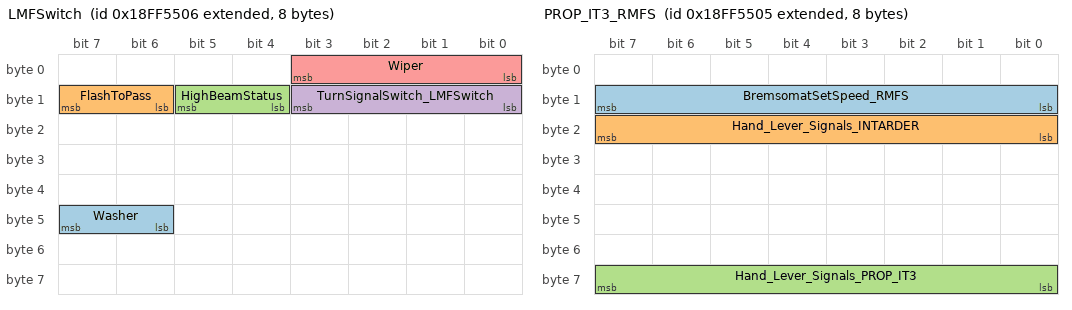
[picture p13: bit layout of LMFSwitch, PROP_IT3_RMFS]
BO_ 2566870278 LMFSwitch: 8 LMFS
 SG_ Washer : 46|2@1+ (1,0) [0|3] "SED"  BCM
 SG_ FlashToPass : 14|2@1+ (1,0) [0|3] "SED"  BCM
 SG_ HighBeamStatus : 12|2@1+ (1,0) [0|3] "SED"  BCM
 SG_ TurnSignalSwitch_LMFSwitch : 8|4@1+ (1,0) [0|16] "SED"  BCM
 SG_ Wiper : 0|4@1+ (1,0) [0|15] "SED"  BCM

BO_ 2566870277 PROP_IT3_RMFS: 8 RMFS
 SG_ BremsomatSetSpeed_RMFS : 8|8@1+ (0.5,0) [0|125] "km/h"  PCCM,ENGINE_CONTROL_MODULE,INSTRUMENT_CLUSTER,BCM,INTARDER
 SG_ Hand_Lever_Signals_INTARDER : 16|8@1+ (1,0) [0|31] ""  PCCM,ENGINE_CONTROL_MODULE,BCM,INTARDER
 SG_ Hand_Lever_Signals_PROP_IT3 : 56|8@1+ (1,0) [0|31] ""  PCCM,BCM,INSTRUMENT_CLUSTER

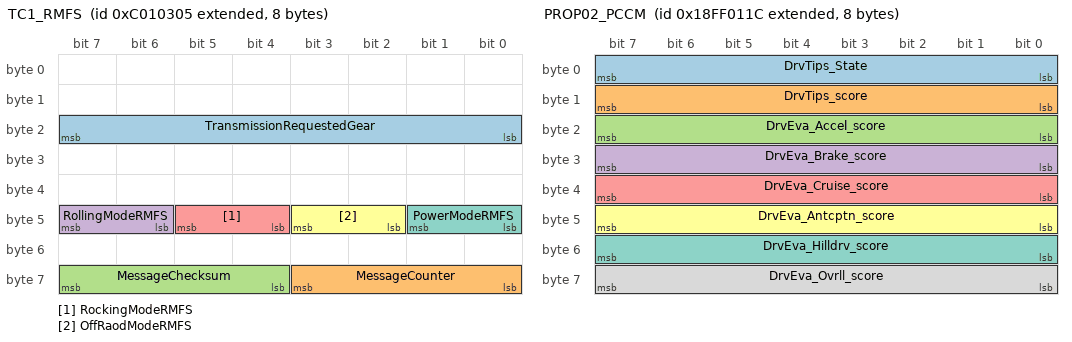
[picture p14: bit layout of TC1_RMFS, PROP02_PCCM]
BO_ 2348876549 TC1_RMFS: 8 RMFS
 SG_ TransmissionRequestedGear : 16|8@1+ (1,0) [0|255] ""  PCCM,TRANSMISSION
 SG_ MessageCounter : 56|4@1+ (1,0) [0|15] ""  PCCM,TRANSMISSION
 SG_ MessageChecksum : 60|4@1+ (1,0) [0|15] ""  PCCM,TRANSMISSION
 SG_ RollingModeRMFS : 46|2@1+ (1,0) [0|3] ""  PCCM,TRANSMISSION
 SG_ RockingModeRMFS : 44|2@1+ (1,0) [0|3] "SED"  PCCM,TRANSMISSION
 SG_ OffRaodModeRMFS : 42|2@1+ (1,0) [0|3] ""  PCCM,TRANSMISSION
 SG_ PowerModeRMFS : 40|2@1+ (1,0) [0|15] ""  PCCM,TRANSMISSION

BO_ 2566848796 PROP02_PCCM: 8 PCCM
 SG_ DrvTips_State : 0|8@1+ (1,0) [0|255] "SED"  ENGINE_CONTROL_MODULE,INSTRUMENT_CLUSTER
 SG_ DrvTips_score : 8|8@1+ (0.5,0) [0|255] "%"  ENGINE_CONTROL_MODULE,INSTRUMENT_CLUSTER
 SG_ DrvEva_Accel_score : 16|8@1+ (0.5,0) [0|125] "%"  ENGINE_CONTROL_MODULE,INSTRUMENT_CLUSTER
 SG_ DrvEva_Brake_score : 24|8@1+ (0.5,0) [0|125] "%"  ENGINE_CONTROL_MODULE,INSTRUMENT_CLUSTER
 SG_ DrvEva_Cruise_score : 32|8@1+ (0.5,0) [0|125] "%"  ENGINE_CONTROL_MODULE,INSTRUMENT_CLUSTER
 SG_ DrvEva_Antcptn_score : 40|8@1+ (0.5,0) [0|255] "%"  ENGINE_CONTROL_MODULE,INSTRUMENT_CLUSTER
 SG_ DrvEva_Hilldrv_score : 48|8@1+ (0.5,0) [0|125] "%"  ENGINE_CONTROL_MODULE,INSTRUMENT_CLUSTER
 SG_ DrvEva_Ovrll_score : 56|8@1+ (0.5,0) [0|125] "%"  ENGINE_CONTROL_MODULE,INSTRUMENT_CLUSTER

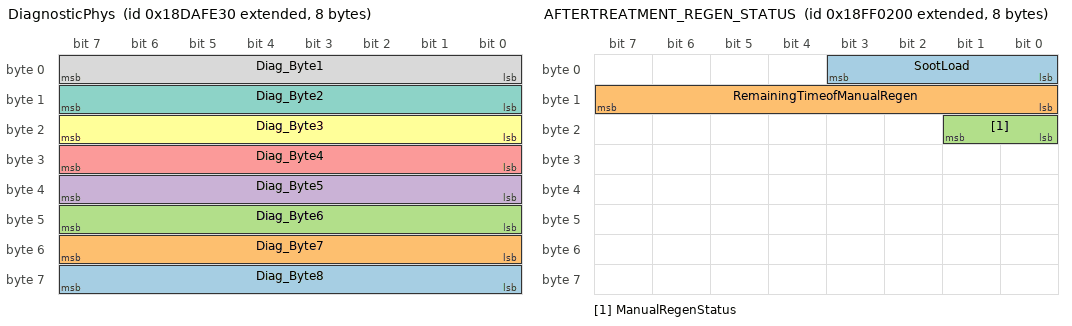
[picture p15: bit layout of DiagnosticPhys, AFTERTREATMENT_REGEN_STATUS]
BO_ 2564488752 DiagnosticPhys: 8 E_APU
 SG_ Diag_Byte8 : 56|8@1+ (1,0) [0|255] "" Vector__XXX
 SG_ Diag_Byte7 : 48|8@1+ (1,0) [0|255] "" Vector__XXX
 SG_ Diag_Byte6 : 40|8@1+ (1,0) [0|255] "" Vector__XXX
 SG_ Diag_Byte5 : 32|8@1+ (1,0) [0|255] "" Vector__XXX
 SG_ Diag_Byte4 : 24|8@1+ (1,0) [0|255] "" Vector__XXX
 SG_ Diag_Byte3 : 16|8@1+ (1,0) [0|255] "" Vector__XXX
 SG_ Diag_Byte2 : 8|8@1+ (1,0) [0|255] "" Vector__XXX
 SG_ Diag_Byte1 : 0|8@1+ (1,0) [0|255] "" Vector__XXX

BO_ 2566834736 DM1_EAPU: 64 E_APU
 SG_ AmberWarningLampStatus : 0|2@1+ (1,0) [0|3] "" Vector__XXX

BO_ 2566849024 AFTERTREATMENT_REGEN_STATUS: 8 ENGINE_CONTROL_MODULE
 SG_ SootLoad : 0|4@1+ (1,0) [0|15] "SED"  PCCM,INSTRUMENT_CLUSTER
 SG_ RemainingTimeofManualRegen : 8|8@1+ (1,0) [0|60] "min"  PCCM,INSTRUMENT_CLUSTER
 SG_ ManualRegenStatus : 16|2@1+ (1,0) [0|3] "SED"  PCCM,INSTRUMENT_CLUSTER

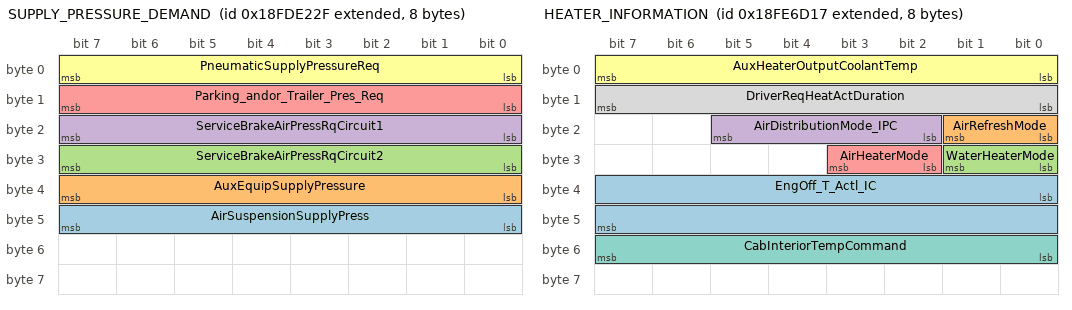
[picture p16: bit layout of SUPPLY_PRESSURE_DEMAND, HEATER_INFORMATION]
BO_ 2566775343 SUPPLY_PRESSURE_DEMAND: 8 BCM
 SG_ AirSuspensionSupplyPress : 40|8@1+ (8,0) [0|2000] "kPa" Vector__XXX
 SG_ AuxEquipSupplyPressure : 32|8@1+ (8,0) [0|2000] "kPa" Vector__XXX
 SG_ ServiceBrakeAirPressRqCircuit2 : 24|8@1+ (8,0) [0|2000] "kPa" Vector__XXX
 SG_ ServiceBrakeAirPressRqCircuit1 : 16|8@1+ (8,0) [0|2000] "kPa" Vector__XXX
 SG_ Parking_andor_Trailer_Pres_Req : 8|8@1+ (8,0) [0|2000] "kPa" Vector__XXX
 SG_ PneumaticSupplyPressureReq : 0|8@1+ (8,0) [0|2000] "kPa" Vector__XXX

BO_ 2566864417 VEHICLE_MODE: 8 BCM
 SG_ DelayedOffKL30 : 8|2@1+ (1,0) [0|3] "SED"  PCCM,TPMS
 SG_ ContactLockKL15 : 4|2@1+ (1,0) [0|3] "SED"  PCCM,TPMS

BO_ 2566810903 HEATER_INFORMATION: 8 INSTRUMENT_CLUSTER
 SG_ EngOff_T_Actl_IC : 32|16@1+ (1,0) [0|65534] "second^0.5"  PCCM,BCM
 SG_ AirRefreshMode : 16|2@1+ (1,0) [0|3] "SED"  PCCM,BCM
 SG_ WaterHeaterMode : 24|2@1+ (1,0) [0|3] "SED"  PCCM,BCM
 SG_ AirDistributionMode_IPC : 18|4@1+ (1,0) [0|15] "SED"  PCCM,BCM
 SG_ AirHeaterMode : 26|2@1+ (1,0) [0|3] "SED"  PCCM,BCM
 SG_ AuxHeaterOutputCoolantTemp : 0|8@1+ (1,-40) [-40|210] "deg C"  PCCM,BCM
 SG_ CabInteriorTempCommand : 48|8@1+ (0.5,-40) [-40|87] "deg C"  PCCM,BCM
 SG_ DriverReqHeatActDuration : 8|8@1+ (1,0) [0|660] "min"  PCCM,BCM

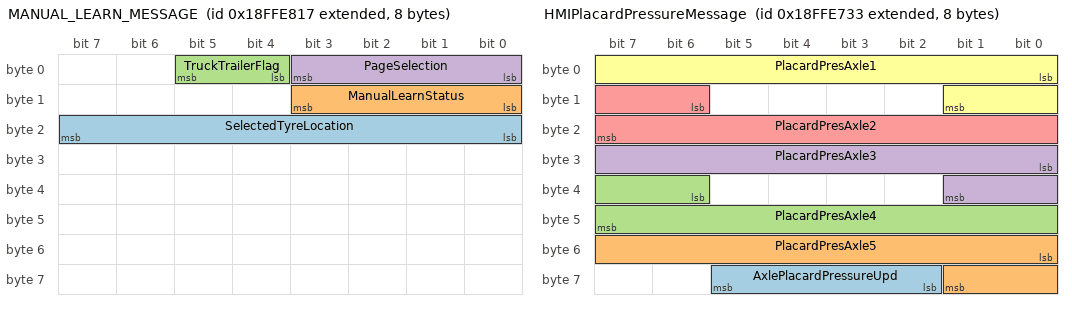
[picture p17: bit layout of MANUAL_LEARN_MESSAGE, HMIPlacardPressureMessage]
BO_ 2566907927 MANUAL_LEARN_MESSAGE: 8 INSTRUMENT_CLUSTER
 SG_ SelectedTyreLocation : 16|8@1+ (1,0) [0|255] "SED"  TPMS
 SG_ ManualLearnStatus : 8|4@1+ (1,0) [0|15] "SED"  TPMS
 SG_ TruckTrailerFlag : 4|2@1+ (1,0) [0|3] "SED"  TPMS
 SG_ PageSelection : 0|4@1+ (1,0) [0|15] "SED"  TPMS

BO_ 2566834691 DM1_TCM: 64 TRANSMISSION
 SG_ SPNConvMethod : 47|1@1+ (1,0) [0|1] "SED"  PCCM
 SG_ OccuranceCount : 40|7@1+ (1,0) [0|126] ""  PCCM
 SG_ FMI : 32|5@1+ (1,0) [0|31] "SED"  PCCM
 SG_ SPN_settozeroorPriofErr : 37|3@1+ (1,0) [0|7] ""  PCCM
 SG_ SPN_8LeastSigBitofSPN_2nd : 24|8@1+ (1,0) [0|255] ""  PCCM
 SG_ SPN_8LeastSigBitofSPN : 16|8@1+ (1,0) [0|255] ""  PCCM
 SG_ FlashRedStopLamp : 12|2@1+ (1,0) [0|3] ""  PCCM,INSTRUMENT_CLUSTER
 SG_ FlashProtectLamp : 8|2@1+ (1,0) [0|3] ""  PCCM,INSTRUMENT_CLUSTER
 SG_ FlashMalfuncIndicatorLamp : 14|2@1+ (1,0) [0|3] ""  PCCM,INSTRUMENT_CLUSTER
 SG_ FlashAmberWarningLamp : 10|2@1+ (1,0) [0|3] ""  PCCM,INSTRUMENT_CLUSTER
 SG_ MalfunctionIndicatorLampStatus : 6|2@1+ (1,0) [0|3] ""  PCCM,INSTRUMENT_CLUSTER
 SG_ AmberWarningLampStatus : 2|2@1+ (1,0) [0|3] ""  PCCM,INSTRUMENT_CLUSTER
 SG_ RedStopLampState : 4|2@1+ (1,0) [0|3] ""  PCCM,INSTRUMENT_CLUSTER
 SG_ ProtectLampStatus : 0|2@1+ (1,0) [0|3] ""  PCCM,INSTRUMENT_CLUSTER

BO_ 2566834739 DM1_TPMS: 64 TPMS
 SG_ FlashRedStopLamp : 12|2@1+ (1,0) [0|3] ""  PCCM,INSTRUMENT_CLUSTER
 SG_ FlashProtectLamp : 8|2@1+ (1,0) [0|3] ""  PCCM,INSTRUMENT_CLUSTER
 SG_ FlashMalfuncIndicatorLamp : 14|2@1+ (1,0) [0|3] ""  PCCM,INSTRUMENT_CLUSTER
 SG_ FlashAmberWarningLamp : 10|2@1+ (1,0) [0|3] ""  PCCM,INSTRUMENT_CLUSTER
 SG_ MalfunctionIndicatorLampStatus : 6|2@1+ (1,0) [0|3] ""  PCCM,INSTRUMENT_CLUSTER
 SG_ AmberWarningLampStatus : 2|2@1+ (1,0) [0|3] ""  PCCM,INSTRUMENT_CLUSTER
 SG_ RedStopLampState : 4|2@1+ (1,0) [0|3] ""  PCCM,INSTRUMENT_CLUSTER
 SG_ ProtectLampStatus : 0|2@1+ (1,0) [0|3] ""  PCCM,INSTRUMENT_CLUSTER
 SG_ DTC5 : 144|32@1+ (1,0) [0|4294967295] ""  PCCM,INSTRUMENT_CLUSTER
 SG_ DTC4 : 112|32@1+ (1,0) [0|4294967295] ""  PCCM,INSTRUMENT_CLUSTER
 SG_ DTC3 : 80|32@1+ (1,0) [0|4294967295] ""  PCCM,INSTRUMENT_CLUSTER
 SG_ DTC2 : 48|32@1+ (1,0) [0|4294967295] ""  PCCM,INSTRUMENT_CLUSTER
 SG_ DTC1 : 16|32@1+ (1,0) [0|4294967295] ""  PCCM,INSTRUMENT_CLUSTER

BO_ 2566907699 HMIPlacardPressureMessage: 8 TPMS
 SG_ AxlePlacardPressureUpd : 58|4@1+ (1,0) [0|15] "state"  PCCM
 SG_ PlacardPresAxle5 : 48|10@1+ (2,0) [0|2036] "kPA"  PCCM
 SG_ PlacardPresAxle4 : 38|10@1+ (2,0) [0|2036] "kPA"  PCCM
 SG_ PlacardPresAxle3 : 24|10@1+ (2,0) [0|2036] "kPA"  PCCM
 SG_ PlacardPresAxle2 : 14|10@1+ (2,0) [0|2036] "kPA"  PCCM
 SG_ PlacardPresAxle1 : 0|10@1+ (2,0) [0|2036] "kPA"  PCCM

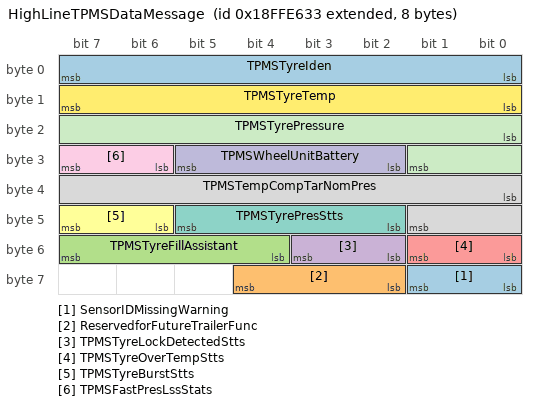
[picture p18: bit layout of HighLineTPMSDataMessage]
BO_ 2566907443 HighLineTPMSDataMessage: 8 TPMS
 SG_ SensorIDMissingWarning : 56|2@1+ (1,0) [0|3] "state"  PCCM
 SG_ ReservedforFutureTrailerFunc : 58|3@1+ (1,0) [0|7] "state"  PCCM,INSTRUMENT_CLUSTER
 SG_ TPMSTyreFillAssistant : 52|4@1+ (1,0) [0|15] "state"  PCCM,INSTRUMENT_CLUSTER
 SG_ TPMSTyreLockDetectedStts : 50|2@1+ (1,0) [0|3] "state"  PCCM,INSTRUMENT_CLUSTER
 SG_ TPMSTyreOverTempStts : 48|2@1+ (1,0) [0|3] "state"  PCCM,INSTRUMENT_CLUSTER
 SG_ TPMSTyreBurstStts : 46|2@1+ (1,0) [0|3] "state"  PCCM,INSTRUMENT_CLUSTER
 SG_ TPMSTyrePresStts : 42|4@1+ (1,0) [0|15] "state"  PCCM,INSTRUMENT_CLUSTER
 SG_ TPMSTempCompTarNomPres : 32|10@1+ (1,0) [0|2036] "SED"  PCCM,INSTRUMENT_CLUSTER
 SG_ TPMSFastPresLssStats : 30|2@1+ (1,0) [0|3] "SED"  PCCM,INSTRUMENT_CLUSTER
 SG_ TPMSWheelUnitBattery : 26|4@1+ (10,0) [0|100] "%"  PCCM,INSTRUMENT_CLUSTER
 SG_ TPMSTyrePressure : 16|10@1+ (2,0) [0|1018] "kPA"  PCCM,INSTRUMENT_CLUSTER
 SG_ TPMSTyreTemp : 8|8@1+ (1,-40) [-40|210] "degC"  PCCM,INSTRUMENT_CLUSTER
 SG_ TPMSTyreIden : 0|8@1+ (1,0) [0|255] "SED"  PCCM,INSTRUMENT_CLUSTER

CM_ BO_ 3221225472 "This is a message for not used signals, created by Vector CANdb++ DBC OLE DB Provider.";
CM_ SG_ 3221225472 DistancetoForwardVehicle "Speed of the vehicle as calculated from wheel or tailshaft speed.";
CM_ SG_ 3221225472 SpeedofForwardVehicle "Speed of the vehicle as calculated from wheel or tailshaft speed.";
CM_ SG_ 3221225472 TrailerWeight "Total mass of freight-carrying vehicle designed to be pulled by truck, including the weight of the contents.";
CM_ SG_ 3221225472 ReferenceTirePressSetting "Reference value of the tire pressure setting as basis for the tire pressure monitoring";
CM_ SG_ 3221225472 ReferenceTirePress "Reference value of the tire pressure as basis for the tire pressure monitoring";
CM_ SG_ 3221225472 TirePressThresholdDetection "Signal indicating the pressure level of the tire.";
CM_ SG_ 3221225472 TireAirLeakageRate "The pressure loss rate of a tire.";
CM_ SG_ 3221225472 CTIWheelEndElectricalFault "Indicates the status of electrical fault on CTI wheel interface.";
CM_ SG_ 3221225472 CTITireStatus "Indicates the status of the tire.";
CM_ SG_ 3221225472 CTIWheelSensorStatus "Indicates whether the wheel is being monitored by the CTI controller.";
CM_ SG_ 3221225472 TireTemp "Temperature at the surface of the tire sidewall.";
CM_ SG_ 3221225472 TirePress "Pressure at which air is contained in cavity formed by tire and rim.";
CM_ SG_ 3221225472 AntitheftRandomNumber "A seven byte random numeric code provided by the component in response to an anti-theft request.";
CM_ SG_ 3221225472 AntitheftComponentStatusStates "Indicates whether or not the component can be started.";
CM_ SG_ 3221225472 AntthftEncryptnSdPrsntIndicator "Indicates the presence of the encryption seed random number.";
CM_ SG_ 3221225472 AntitheftModifyPwdStates "This parameter is used to indicate whether a password request was successfully performed, or if the request could not be";
CM_ SG_ 3221225472 AntitheftPwdValidIndicator "Indicates the presence of a validated password.";
CM_ SG_ 3221225472 EngBuildHoursReset "Command signal used to reset the engine rebuild hours.";
CM_ SG_ 3221225472 SteerStraightAheadPosReset "Used to reset the straight ahead position for a steering sensor in the steering column or a steering controller's straight";
CM_ SG_ 3221225472 ServiceComponentIdentification "Identification of component needing service.";
CM_ SG_ 3221225472 ServiceComponentIdentificationC "Identification of component needing service.";
CM_ SG_ 3221225472 TrnsShftSlctorDisplayModeSwitch "Status of the operator’s switch used to ‘toggle’ through multiple display modes of a shift selector display.";
CM_ SG_ 3221225472 TransMode4 "Indicates whether transmission mode 4 is enabled.";
CM_ SG_ 3221225472 TransMode3 "Indicates whether transmission mode 3 is enabled.";
CM_ SG_ 3221225472 TransMode2 "Indicates whether transmission mode 2 is enabled.";
CM_ SG_ 3221225472 DisengageDiffLockRqCentralRear "Command signal used to disengage the various differential locks, e.";
CM_ SG_ 3221225472 DisengageDiffLockRqCentralFront "Command signal used to disengage the various differential locks, e.";
CM_ SG_ 3221225472 DisengageDiffLockRqCentral "Command signal used to disengage the various differential locks, e.";
CM_ SG_ 3221225472 DisengageDiffLockRqRearAxle2 "Command signal used to disengage the various differential locks, e.";
CM_ SG_ 3221225472 DisengageDiffLockRqRearAxle1 "Command signal used to disengage the various differential locks, e.";
CM_ SG_ 3221225472 DisengageDiffLockRqFrontAxle2 "Command signal used to disengage the various differential locks, e.";
CM_ SG_ 3221225472 DisengageDiffLockRqFrontAxle1 "Command signal used to disengage the various differential locks, e.";
CM_ SG_ 3221225472 TransRqedGear "Gear requested by the operator, ABS, or engine.";
CM_ SG_ 3221225472 RqedPercentClutchSlip "Parameter which represents the percent clutch slip requested by a device.";
CM_ SG_ 3221225472 DisengageDrivelineRq "Command signal used to simply disengage the driveline, e.";
CM_ SG_ 3221225472 TrnsTrqConverterLockupDisableRq "Command signal to prevent torque converter lockup, which may cause problems in certain circumstances for ASR.";
CM_ SG_ 3221225472 TransRqedLaunchGear "Initial gear for the transmission to start out in when the vehicle is launched from a standing stop, as specified by the";
CM_ SG_ 3221225472 TransReverseGearShiftInhibitRq "Allows devices external to the normal transmission shift selector system to request the transmission to inhibit shifts into";
CM_ SG_ 3221225472 TransMode8 "Indicates whether transmission mode 8 is enabled.";
CM_ SG_ 3221225472 TransMode7 "Indicates whether transmission mode 7 is enabled.";
CM_ SG_ 3221225472 TransMode6 "Indicates whether transmission mode 6 is enabled.";
CM_ SG_ 3221225472 TransMode5 "Indicates whether transmission mode 5 is enabled.";
CM_ SG_ 3221225472 MessageCounter "The message counter is used to detect situations where the transmitting ECU malfunction repeats the same frame all the time.The message counter is used to detect situations where the transmitting ECU malfunction repeats the same frame all the time.The message counter is used to detect situations where the transmitting ECU malfunction repeats the same frame all the time.";
CM_ SG_ 3221225472 ControlPurpose "State signal which indicates which control mode the sending device is using to generate the TSC1 command.State signal which indicates which control mode the sending device is using to generate the TSC1 command.State signal which indicates which control mode the sending device is using to generate the TSC1 command.";
CM_ SG_ 3221225472 TransmissionRate "This parameter indicates the transmission rate at which the sending device will transmit the TSC1 message.This parameter indicates the transmission rate at which the sending device will transmit the TSC1 message.This parameter indicates the transmission rate at which the sending device will transmit the TSC1 message.";
CM_ SG_ 3221225472 EngineRequestedTorqueHiRes "This parameter displays an additional torque in percent of the reference engine torque.This parameter displays an additional torque in percent of the reference engine torque.This parameter displays an additional torque in percent of the reference engine torque.";
CM_ SG_ 3221225472 PrkngBrkeActuatorFullyActivated "Signal which indicates when the parking brake actuator is fully activated.";
CM_ SG_ 3221225472 DslPrtcltFltrActvRgnrtnFrcdStts "Indicates the forced execution status of diesel particulate filter regeneration.";
CM_ SG_ 3221225472 ExhaustSystemHighTempLampCmd "Command to control the exhaust system high temperature lamp.";
CM_ SG_ 3221225472 DslPrtcltFltrAtmtcActvRgnrtnIntt "Indicates the configuration of diesel particulate filter active regeneration automatic initiation.";
CM_ SG_ 3221225472 DslPrtcltFltrActvRgnrtnInhbtdDTV "Speed";
CM_ SG_ 3221225472 DslPrtcltFltrActvRgnrtnInhbtdDTE "Indicates the state of diesel particulate filter active regeneration inhibition due to the engine not being warmed up.";
CM_ SG_ 3221225472 DslPrtcltFltrActvRgnrtnInhbtdDTP "Indicates the state of diesel particulate filter active regeneration inhibition due to a permanent system lockout.";
CM_ SG_ 3221225472 DslPrtcltFltrActvRgnrtnInhbtdDTT "Indicates the state of diesel particulate filter active regeneration inhibition due to a temporary system lockout.";
CM_ SG_ 3221225472 DslPrtcltFltrActvRgnrtnInhbtdDTS "Indicates the state of diesel particulate filter active regeneration inhibition due to a system timeout.";
CM_ SG_ 3221225472 DslPrtcltFltrActvRgnrtnInhb_0000 "Indicates the state of diesel particulate filter active regeneration inhibition due to a system fault being active.";
CM_ SG_ 3221225472 DslPrtcltFltrActvRgnrtnInhbtdDTL "Indicates the state of diesel particulate filter active regeneration inhibition due to the exhaust gas temperature being too";
CM_ SG_ 3221225472 DslPrtcltFltrActvRgnrtnInhb_0001 "Indicates the state of diesel particulate filter active regeneration inhibition due to the parking brake being not set.";
CM_ SG_ 3221225472 DslPrtcltFltrActvRgnrtnInhb_0002 "Speed";
CM_ SG_ 3221225472 DslPrtcltFltrActvRgnrtnInhbtdDTO "Indicates the state of diesel particulate filter active regeneration inhibition due to the transmission being out of neutral.";
CM_ SG_ 3221225472 DslPrtcltFltrActvRgnrtnInhbtdDTA "Indicates the state of diesel particulate filter active regeneration inhibition due to the accelerator pedal being off idle.";
CM_ SG_ 3221225472 DslPrtcltFltrActvRgnrtnInhb_0003 "Indicates the state of diesel particulate filter active regeneration inhibition due to the PTO being active.";
CM_ SG_ 3221225472 DslPrtcltFltrActvRgnrtnInhb_0004 "Indicates the state of diesel particulate filter active regeneration inhibition due to the service brake being active.";
CM_ SG_ 3221225472 DslPrtcltFltrActvRgnrtnInhbtdDTC "Indicates the state of diesel particulate filter active regeneration inhibition due to the clutch being disengaged.";
CM_ SG_ 3221225472 DslPrtcltFltrActvRgnrtnInhbtdDTI "Indicates the state of diesel particulate filter active regeneration inhibition due to the Diesel Particulate Filter Regeneration";
CM_ SG_ 3221225472 DslPrtcltFltrActvRgnrtnInhbtdStt "Indicates the state of diesel particulate filter active regeneration inhibition.";
CM_ SG_ 3221225472 DslPrtcltFltrActvRgnrtionStatus "Indicates the state of diesel particulate filter active regeneration.";
CM_ SG_ 3221225472 DslPrtcltFltrPssvRgnrtionStatus "Indicates the state of diesel particulate filter passive regeneration.";
CM_ SG_ 3221225472 DieselParticulateFilterLampCmd "Command to control the diesel particulate filter lamp.";
CM_ SG_ 3221225472 Aftrtrtmnt1SCRCtlystRgntTnk1HtrP "Used to identify the applicable J1939-73 FMI detected in the SCR catalyst reagent tank 1 heater, by the manufacturer’s";
CM_ SG_ 3221225472 Aftrtrtmnt1SCRCtalystTankHeater "Percentage of heating applied to the aftertreatment 1 catalyst tank heater.";
CM_ SG_ 3221225472 AftrtrtmntSCROprtrIndcmntSvrity "The severity of operator inducement for anomolies with the SCR system, such as tampering, low DEF quality, and DEF";
CM_ SG_ 3221225472 Aftrtrtmnt1SCRCtlystRgntTnk1TmpP "Used to identify the applicable J1939-73 FMI detected in the SCR catalyst reagent tank 1 temperature, by the";
CM_ SG_ 3221225472 Aftrtrtmnt1DEFTnkLwLvlIndicator "The desired illumination of the driver's warning indicator for diesel exhaust fluid (DEF) tank low level.";
CM_ SG_ 3221225472 Aftrtrtmnt1SCRCtlystTnkLvlPrlmnr "Used to identify the applicable J1939-73 FMI that applies to the most significant failure of the catalyst tank level sensor.";
CM_ SG_ 3221225472 Aftrtrtmnt1SCRCtalystTankLevel2 "The measure of the reagent level in the catalyst tank.";
CM_ SG_ 3221225472 Aftrtrtment1SCRCatalystTankTemp "Temperature of the reagent in the storage tank.";
CM_ SG_ 3221225472 Aftrtrtmnt1SCRCatalystTankLevel "A special catalyst uses a chemical reagent to reach legal requirement for NOX emissions.";
CM_ SG_ 3221225472 EngShutdownOverrideSwitch "Switch signal which indicates the position of the engine shutdown override switch.";
CM_ SG_ 3221225472 EngTestModeSwitch "Switch signal which indicates the position of the engine test mode switch.";
CM_ SG_ 3221225472 EngIdleDecrementSwitch "Switch signal which indicates the position of the idle decrement switch.";
CM_ SG_ 3221225472 EngIdleIncrementSwitch "Switch signal which indicates the position of the idle increment switch.";
CM_ SG_ 3221225472 OprtrsDesiredDelayedLampOffTime "A 16 bit parameter to be associated with Delayed Off position (1000 binary) of the Main Light Switch.";
CM_ SG_ 3221225472 CruiseCtrlStates "This parameter is used to indicate the current state, or mode, of operation by the cruise control device.";
CM_ SG_ 3221225472 AxleWeight_30 "Total mass imposed by the tires on the road surface at the specified axle.";
CM_ SG_ 3221225472 AxleWeight_20 "Total mass imposed by the tires on the road surface at the specified axle.";
CM_ SG_ 3221225472 AxleWeight_10 "Total mass imposed by the tires on the road surface at the specified axle.";
CM_ SG_ 3221225472 AuxI_O08_GearboxNeutralPos "Identifies the current status of auxiliary input/output functions that are configured uniquely per application.";
CM_ SG_ 3221225472 AuxI_O07_TrailerABSFulOper "Identifies the current status of auxiliary input/output functions that are configured uniquely per application.";
CM_ SG_ 3221225472 AuxI_O06_TrailerABSDetected "Identifies the current status of auxiliary input/output functions that are configured uniquely per application.";
CM_ SG_ 3221225472 AuxI_O05_TrailerConnected "Identifies the current status of auxiliary input/output functions that are configured uniquely per application.";
CM_ SG_ 3221225472 AuxI_O02_BlendingSwitchPos "Identifies the current status of auxiliary input/output functions that are configured uniquely per application.";
CM_ SG_ 3221225472 PCCM_TransReqGearPriority "Value of set (chosen) velocity of velocity control system.";
CM_ SG_ 3221225472 PCCM_TransGearShiftRequest "Value of set (chosen) velocity of velocity control system.";
CM_ SG_ 3221225472 PCCMaxPosSpdOffset "The pneumatic pressure in the circuit for the electronically controlled air suspension system.";
CM_ SG_ 3221225472 PCCMaxNegSpdOffset "The pneumatic pressure in the circuit for the electronically controlled air suspension system.";
CM_ SG_ 3221225472 TrailerBrakeStatus "State signal which indicates that ABS in the trailer is actively controlling the brakes.";
CM_ SG_ 3221225472 AuxHeaterMode "State of the auxiliary heater";
CM_ SG_ 3221225472 EngThrottleValve2Pos "The sensed position feedback of the valve, coming from a second electrical actuator for a second throttle plate, used toThe sensed position feedback of the valve, coming from a second electrical actuator for a second throttle plate, used to";
CM_ SG_ 3221225472 AuxEquipmentSupplyPress "The pneumatic pressure in the auxiliary circuit.";
CM_ SG_ 3221225472 VhclSped_Ctrl_Override_Request "Value of set (chosen) velocity of velocity control system.";
CM_ SG_ 3221225472 VhclSped_Ctrl_Override_EvntIndic "Value of set (chosen) velocity of velocity control system.";
CM_ SG_ 3221225472 PreCru_CtrlDriv_Disgage_inhbtReq "Value of set (chosen) velocity of velocity control system.";
CM_ SG_ 3221225472 PreCru_Ctrl_SpeedEventIndicator "Value of set (chosen) velocity of velocity control system.";
CM_ SG_ 3221225472 PreCru_Ctrl_NextGrade "Value of set (chosen) velocity of velocity control system.";
CM_ SG_ 3221225472 PreCru_Ctrl_EventinRange "Value of set (chosen) velocity of velocity control system.";
CM_ SG_ 3221225472 AuxI_O03_RetarderLeverPos "Identifies the current status of auxiliary input/output functions that are configured uniquely per application.";
CM_ SG_ 3221225472 GearShiftPriority "Switch signal which indicates the state of the accelerator pedal 2 low idle switch.";
CM_ SG_ 3221225472 CruiseCtrlLowSetLimitSpeed "Minimum vehicle velocity at which cruise can be set or minimum vehicle velocity for cruise operation before it will exit";
CM_ SG_ 3221225472 CruiseCtrlHighSetLimitSpeed "Maximum vehicle velocity at which cruise can be set.";
CM_ SG_ 3221225472 MaxVehicleSpeedLimit "Maximum vehicle velocity allowed.";
CM_ SG_ 3221225472 FlashRedStopLamp "This parameter provides the capability to flash the RSL (SPN 3039).This parameter provides the capability to flash the RSL (SPN 3039).This parameter provides the capability to flash the RSL (SPN 3039).";
CM_ SG_ 3221225472 FlashProtectLamp "This parameter provides the capability to flash the engine protect lamp (SPN 3041).This parameter provides the capability to flash the engine protect lamp (SPN 3041).This parameter provides the capability to flash the engine protect lamp (SPN 3041).";
CM_ SG_ 3221225472 FlashMalfuncIndicatorLamp "This parameter provides the capability to flash the MIL (SPN 3038).This parameter provides the capability to flash the MIL (SPN 3038).This parameter provides the capability to flash the MIL (SPN 3038).";
CM_ SG_ 3221225472 FlashAmberWarningLamp "This parameter provides the capability to flash the AWL (SPN 3040). This parameter provides the capability to flash the AWL (SPN 3040). This parameter provides the capability to flash the AWL (SPN 3040). ";
CM_ SG_ 3221225472 MalfunctionIndicatorLampStatus "A lamp used to relay only emissions-related trouble code information.A lamp used to relay only emissions-related trouble code information.A lamp used to relay only emissions-related trouble code information.A lamp used to relay only emissions-related trouble code information.";
CM_ SG_ 3221225472 AmberWarningLampStatus "This lamp is used to relay trouble code information that is reporting a problem with the vehicle system but the vehicle need
not be immediately stopped.This lamp is used to relay trouble code information that is reporting a problem with the vehicle system but the vehicle need
not be immediately stopped.This lamp is used to relay trouble code information that is reporting a problem with the vehicle system but the vehicle need
not be immediately stopped.This lamp is used to relay trouble code information ";
CM_ SG_ 3221225472 ProtectLampStatus "This lamp is used to relay trouble code informatio that is reporting a problem with a vehicle system that is most
probably not electronic subsystem related.This lamp is used to relay trouble code informatio that is reporting a problem with a vehicle system that is most
probably not electronic subsystem related.";
CM_ SG_ 3221225472 DTC5 "Diagnostic Trouble CodeDiagnostic Trouble CodeDiagnostic Trouble Code";
CM_ SG_ 3221225472 DTC4 "Diagnostic Trouble CodeDiagnostic Trouble CodeDiagnostic Trouble Code";
CM_ SG_ 3221225472 DTC3 "Diagnostic Trouble CodeDiagnostic Trouble CodeDiagnostic Trouble Code";
CM_ SG_ 3221225472 DTC2 "Diagnostic Trouble CodeDiagnostic Trouble CodeDiagnostic Trouble Code";
CM_ SG_ 3221225472 DTC1 "Diagnostic Trouble CodeDiagnostic Trouble CodeDiagnostic Trouble CodeDiagnostic Trouble Code";
CM_ SG_ 3221225472 SCRThermalManagementActive "Indicates that the exhaust temperatures have been elevated for regeneration of the SCR aftertreatment system or in";
CM_ SG_ 3221225472 MmntryEngMaxPowerEnableFeedback "Momentarily requesting Engine Maximum Power Enable - feature support feedback";
CM_ SG_ 3221225472 DPFThermalManagementActive "Indicates that the exhaust temperatures have been elevated for regeneration of the diesel particulate filter aftertreatment";
CM_ SG_ 3221225472 TwoSpeedAxleSwitch "Switch signal which indicates the current axle range.Switch signal which indicates the current axle range.";
CM_ SG_ 3221225472 EngIntakeManifold1Press "The gage pressure measurement of the air intake manifold.";
CM_ SG_ 3221225472 FreezeFrameLength "The freeze frame length shall be equal to the number of bytes in the required parameters plus the number of bytes in the
manufacturer specific parameters.";
CM_ SG_ 3221225472 EngSpeed "Actual engine speed which is calculated over a minimum crankshaft angle of 720 degrees divided by the number of cylinders.";
CM_ SG_ 3221225472 EngTorqueMode "State signal which indicates which engine torque mode is currently generating, limiting, or controlling the torque.";
CM_ SG_ 3221225472 WheelBasedVehicleSpeed "Speed of the vehicle as calculated from wheel or tailshaft speed.";
CM_ SG_ 3221225472 EngPercentLoadAtCurrentSpeed "The ratio of actual engine percent torque (indicated) to maximum indicated torque available at the current engine speed,";
CM_ SG_ 3221225472 RedStopLampState "This lamp is uesed to relay trouble code information that is of a severe enought condition that it warrants stopping the vehicle.This lamp is uesed to relay trouble code information that is of a severe enought condition that it warrants stopping the vehicle.";
CM_ SG_ 3221225472 ParkingBrakeSwitch_BCM "Switch signal which indicates when the parking brake is set.";
CM_ SG_ 3221225472 ParkBrakeReleaseInhibitRq "Park Brake Release Inhibit Request signals the desire that an applied park brake remain applied and limit the ability of the";
CM_ SG_ 3221225472 CruiseCtrlPauseSwitch "Switch signal which indicates the position of the Cruise Control Pause Switch used on Remote Cruise Control applications.";
CM_ SG_ 3221225472 BremsomatConfiguration "Signal which indicates the current mode of the halt brake function.";
CM_ SG_ 3221225472 TotalNumberOfPacketsEoMA "Total number of packets for BAM message.Total number of packets received for RTS/CTS message.Total number of packets for RTS/CTS message.";
CM_ SG_ 3221225472 TotalMessageSizeEoMA "Total message size (in bytes) for BAM message.Total message size (in bytes) for RTS/CTS message.Total message size (in bytes) for RTS/CTS message.";
CM_ SG_ 3221225472 TotalMessageSizeBAM "Total message size (in bytes) for BAM message.Total message size (in bytes) for RTS/CTS message.Total message size (in bytes) for RTS/CTS message.";
CM_ SG_ 3221225472 TotalNumberOfPacketsBAM "Total number of packets for BAM message.Total number of packets received for RTS/CTS message.Total number of packets for RTS/CTS message.";
CM_ SG_ 3221225472 ConnectionAbortReason "Reason for connection abort message.";
CM_ SG_ 3221225472 NextPacketNumberToBeSent "Next Packet Number to be sent (TP.CM_CTS)";
CM_ SG_ 3221225472 NumberOfPacketsThatCanBeSent "Number of Packets that can be sent (TP.CM_CTS)";
CM_ SG_ 3221225472 MaximumNumberOfPackets "Maximum number of packets for RTS/CTS message.";
CM_ SG_ 3221225472 TotalNumberOfPackets "Total number of packets for BAM message.Total number of packets received for RTS/CTS message.Total number of packets for RTS/CTS message.";
CM_ SG_ 3221225472 TotalMessageSize "Total message size (in bytes) for BAM message.Total message size (in bytes) for RTS/CTS message.Total message size (in bytes) for RTS/CTS message.";
CM_ SG_ 3221225472 BremsomatControlPriority "Switch signal which indicates the state of the accelerator pedal 2 low idle switch.";
CM_ SG_ 3221225472 TransGearShiftInhibitRq "Command signal to inhibit gear shifts.";
CM_ SG_ 3221225472 Aftertreatment1OutletNOx "The amount of combined NO and NO2 in the exhaust entering the aftertreatment system measured by a NOx sensor at";
CM_ BO_ 2566834694 "Active diagnostic trouble codes";
CM_ SG_ 2566834694 FlashRedStopLamp "This parameter provides the capability to flash the RSL (SPN 3039).";
CM_ SG_ 2566834694 FlashProtectLamp "This parameter provides the capability to flash the engine protect lamp (SPN 3041).";
CM_ SG_ 2566834694 FlashMalfuncIndicatorLamp "This parameter provides the capability to flash the MIL (SPN 3038).";
CM_ SG_ 2566834694 FlashAmberWarningLamp "This parameter provides the capability to flash the AWL (SPN 3040). ";
CM_ SG_ 2566834694 MalfunctionIndicatorLampStatus "A lamp used to relay only emissions-related trouble code information.";
CM_ SG_ 2566834694 AmberWarningLampStatus "This lamp is used to relay trouble code information that is reporting a problem with the vehicle system but the vehicle need
not be immediately stopped.";
CM_ SG_ 2566834694 RedStopLampState "This lamp is uesed to relay trouble code information that is of a severe enought condition that it warrants stopping the vehicle.";
CM_ SG_ 2566834694 ProtectLampStatus "This lamp is used to relay trouble code informatio that is reporting a problem with a vehicle system that is most
probably not electronic subsystem related.";
CM_ BO_ 2566834693 "Active diagnostic trouble codes";
CM_ SG_ 2566834693 FlashRedStopLamp "This parameter provides the capability to flash the RSL (SPN 3039).";
CM_ SG_ 2566834693 FlashProtectLamp "This parameter provides the capability to flash the engine protect lamp (SPN 3041).";
CM_ SG_ 2566834693 FlashMalfuncIndicatorLamp "This parameter provides the capability to flash the MIL (SPN 3038).";
CM_ SG_ 2566834693 FlashAmberWarningLamp "This parameter provides the capability to flash the AWL (SPN 3040). ";
CM_ SG_ 2566834693 MalfunctionIndicatorLampStatus "A lamp used to relay only emissions-related trouble code information.";
CM_ SG_ 2566834693 AmberWarningLampStatus "This lamp is used to relay trouble code information that is reporting a problem with the vehicle system but the vehicle need
not be immediately stopped.";
CM_ SG_ 2566834693 RedStopLampState "This lamp is uesed to relay trouble code information that is of a severe enought condition that it warrants stopping the vehicle.";
CM_ SG_ 2566834693 ProtectLampStatus "This lamp is used to relay trouble code informatio that is reporting a problem with a vehicle system that is most
probably not electronic subsystem related.";
CM_ BO_ 2565472256 "Request";
CM_ SG_ 2565472256 ParameterGroupNumber "PGN which is requested by Request2 message";
CM_ BO_ 2566835968 "Active diagnostic trouble codes";
CM_ SG_ 2566835968 RedStopLampState_DM2 "This lamp is uesed to relay trouble code information that is of a severe enought condition that it warrants stopping the vehicle.This lamp is uesed to relay trouble code information that is of a severe enought condition that it warrants stopping the vehicle.";
CM_ SG_ 2566835968 ProtectLampStatus_DM2 "This lamp is used to relay trouble code informatio that is reporting a problem with a vehicle system that is most
probably not electronic subsystem related.This lamp is used to relay trouble code informatio that is reporting a problem with a vehicle system that is most
probably not electronic subsystem related.This lamp is used to relay trouble code informatio that is reporting a problem with a vehicle system that is most
probably not electronic subsystem related.";
CM_ SG_ 2566835968 FlashRedStopLamp "This parameter provides the capability to flash the RSL (SPN 3039).";
CM_ SG_ 2566835968 FlashProtectLamp "This parameter provides the capability to flash the engine protect lamp (SPN 3041).";
CM_ SG_ 2566835968 FlashMalfuncIndicatorLamp "This parameter provides the capability to flash the MIL (SPN 3038).";
CM_ SG_ 2566835968 FlashAmberWarningLamp "This parameter provides the capability to flash the AWL (SPN 3040). ";
CM_ BO_ 2566834944 "Active diagnostic trouble codes";
CM_ SG_ 2566834944 RedStopLampState_DM2 "This lamp is uesed to relay trouble code information that is of a severe enought condition that it warrants stopping the vehicle.This lamp is uesed to relay trouble code information that is of a severe enought condition that it warrants stopping the vehicle.";
CM_ SG_ 2566834944 ProtectLampStatus_DM2 "This lamp is used to relay trouble code informatio that is reporting a problem with a vehicle system that is most
probably not electronic subsystem related.This lamp is used to relay trouble code informatio that is reporting a problem with a vehicle system that is most
probably not electronic subsystem related.This lamp is used to relay trouble code informatio that is reporting a problem with a vehicle system that is most
probably not electronic subsystem related.";
CM_ SG_ 2566834944 FlashRedStopLamp "This parameter provides the capability to flash the RSL (SPN 3039).";
CM_ SG_ 2566834944 FlashProtectLamp "This parameter provides the capability to flash the engine protect lamp (SPN 3041).";
CM_ SG_ 2566834944 FlashMalfuncIndicatorLamp "This parameter provides the capability to flash the MIL (SPN 3038).";
CM_ SG_ 2566834944 FlashAmberWarningLamp "This parameter provides the capability to flash the AWL (SPN 3040). ";
CM_ BO_ 2348814341 "Torque/Speed Control 1";
CM_ SG_ 2348814341 MessageCounter "The message counter is used to detect situations where the transmitting ECU malfunction repeats the same frame all the time.";
CM_ SG_ 2348814341 EngRqedTorque_TorqueLimit "Parameter provided to the engine or retarder in the torque/speed control message for controlling or limiting the output torque.";
CM_ SG_ 2348814341 MessageChecksum "The checksum is used to verify the signal path from the transmitting device to the receiving device.";
CM_ BO_ 2632711987 "Transport Protocol - Data Transfer";
CM_ BO_ 2632777523 "Transport Protocol - Connection Management";
CM_ SG_ 2632777523 TotalNumberOfPackets "Total number of packets for BAM message.Total number of packets received for RTS/CTS message.Total number of packets for RTS/CTS message.";
CM_ SG_ 2632777523 TotalMessageSize "Total message size (in bytes) for BAM message.Total message size (in bytes) for RTS/CTS message.Total message size (in bytes) for RTS/CTS message.";
CM_ BO_ 2633935619 "Electronic Transmission Controller 6";
CM_ SG_ 2633935619 RecommendedGear "The transmission calculates this gear continuously.";
CM_ SG_ 2565668611 TotalNumberOfPacketsBAM "Total number of packets for BAM message.Total number of packets received for RTS/CTS message.Total number of packets for RTS/CTS message.";
CM_ SG_ 2565668611 PGNofRequstedInformation "PGN associated with this transfer message";
CM_ SG_ 2565668611 TotalMessageSizeBAM "Total message size (in bytes) for BAM message.Total message size (in bytes) for RTS/CTS message.Total message size (in bytes) for RTS/CTS message.";
CM_ SG_ 2565668624 TotalNumberOfPacketsBAM "Total number of packets for BAM message.Total number of packets received for RTS/CTS message.Total number of packets for RTS/CTS message.";
CM_ SG_ 2565668624 PGNofRequstedInformation "PGN associated with this transfer message";
CM_ SG_ 2565668624 TotalMessageSizeBAM "Total message size (in bytes) for BAM message.Total message size (in bytes) for RTS/CTS message.Total message size (in bytes) for RTS/CTS message.";
CM_ SG_ 2565668623 TotalNumberOfPacketsBAM "Total number of packets for BAM message.Total number of packets received for RTS/CTS message.Total number of packets for RTS/CTS message.";
CM_ SG_ 2565668623 PGNofRequstedInformation "PGN associated with this transfer message";
CM_ SG_ 2565668623 TotalMessageSizeBAM "Total message size (in bytes) for BAM message.Total message size (in bytes) for RTS/CTS message.Total message size (in bytes) for RTS/CTS message.";
CM_ SG_ 2565668608 TotalNumberOfPacketsBAM "Total number of packets for BAM message.Total number of packets received for RTS/CTS message.Total number of packets for RTS/CTS message.";
CM_ SG_ 2565668608 PGNofRequstedInformation "PGN associated with this transfer message";
CM_ SG_ 2565668608 TotalMessageSizeBAM "Total message size (in bytes) for BAM message.Total message size (in bytes) for RTS/CTS message.Total message size (in bytes) for RTS/CTS message.";
CM_ SG_ 2565406464 GroupFunctionValue "Group Function of PGN being acknowledged. This field identifies for a device the specific group function of a PGN being acknowledged or declined.  This field is not used if the PGN being acknowledged or declined is not a group function PGN.";
CM_ SG_ 2632777519 TotalNumberOfPacketsBAM "Total number of packets for BAM message.Total number of packets received for RTS/CTS message.Total number of packets for RTS/CTS message.";
CM_ SG_ 2632777519 PGNofRequstedInformation "PGN associated with this transfer message";
CM_ SG_ 2632777519 TotalMessageSizeBAM "Total message size (in bytes) for BAM message.Total message size (in bytes) for RTS/CTS message.Total message size (in bytes) for RTS/CTS message.";
CM_ SG_ 2173632254 TotalNumberOfPacketsBAM "Total number of packets for BAM message.Total number of packets received for RTS/CTS message.Total number of packets for RTS/CTS message.";
CM_ SG_ 2173632254 PGNofRequstedInformation "PGN associated with this transfer message";
CM_ SG_ 2173632254 TotalMessageSizeBAM "Total message size (in bytes) for BAM message.Total message size (in bytes) for RTS/CTS message.Total message size (in bytes) for RTS/CTS message.";
CM_ SG_ 2565668846 TotalNumberOfPacketsBAM "Total number of packets for BAM message.Total number of packets received for RTS/CTS message.Total number of packets for RTS/CTS message.";
CM_ SG_ 2565668846 PGNofRequstedInformation "PGN associated with this transfer message";
CM_ SG_ 2565668846 TotalMessageSizeBAM "Total message size (in bytes) for BAM message.Total message size (in bytes) for RTS/CTS message.Total message size (in bytes) for RTS/CTS message.";
CM_ SG_ 2565668631 TotalNumberOfPacketsBAM "Total number of packets for BAM message.Total number of packets received for RTS/CTS message.Total number of packets for RTS/CTS message.";
CM_ SG_ 2565668631 PGNofRequstedInformation "PGN associated with this transfer message";
CM_ SG_ 2565668631 TotalMessageSizeBAM "Total message size (in bytes) for BAM message.Total message size (in bytes) for RTS/CTS message.Total message size (in bytes) for RTS/CTS message.";
CM_ BO_ 2565603105 "Transport Protocol - Data Transfer";
CM_ BO_ 2565668641 "Transport Protocol - Connection Management";
CM_ SG_ 2565668641 TotalNumberOfPacketsEoMA "Total number of packets for BAM message.Total number of packets received for RTS/CTS message.Total number of packets for RTS/CTS message.";
CM_ SG_ 2565668641 TotalMessageSizeEoMA "Total message size (in bytes) for BAM message.Total message size (in bytes) for RTS/CTS message.Total message size (in bytes) for RTS/CTS message.";
CM_ SG_ 2565668641 TotalMessageSizeBAM "Total message size (in bytes) for BAM message.Total message size (in bytes) for RTS/CTS message.Total message size (in bytes) for RTS/CTS message.";
CM_ SG_ 2565668641 TotalNumberOfPacketsBAM "Total number of packets for BAM message.Total number of packets received for RTS/CTS message.Total number of packets for RTS/CTS message.";
CM_ SG_ 2565668641 ConnectionAbortReason "Reason for connection abort message.";
CM_ SG_ 2565668641 NextPacketNumberToBeSent "Next Packet Number to be sent (TP.CM_CTS)";
CM_ SG_ 2565668641 NumberOfPacketsThatCanBeSent "Number of Packets that can be sent (TP.CM_CTS)";
CM_ SG_ 2565668641 MaximumNumberOfPackets "Maximum number of packets for RTS/CTS message.";
CM_ SG_ 2565668641 TotalNumberOfPackets "Total number of packets for BAM message.Total number of packets received for RTS/CTS message.Total number of packets for RTS/CTS message.";
CM_ SG_ 2565668641 TotalMessageSize "Total message size (in bytes) for BAM message.Total message size (in bytes) for RTS/CTS message.Total message size (in bytes) for RTS/CTS message.";
CM_ SG_ 2565537768 ParameterGroupNumber "PGN which is requested by Request2 message";
CM_ SG_ 2565537578 ParameterGroupNumber "PGN which is requested by Request2 message";
CM_ SG_ 2566844711 CruiseControlsetspeed "Value of set (chosen) velocity of velocity control system.";
CM_ SG_ 2566844711 CruiseControlenableswitch "Switch signal which indicates that it is possible to manage the cruise control function.";
CM_ SG_ 2566844711 Wheelbasedvehiclespeed_CCVS_B27 "Speed of the vehicle as calculated from wheel or tailshaft speed.";
CM_ BO_ 2565668606 "Transport Protocol - Connection Management";
CM_ BO_ 2565603070 "Transport Protocol - Data Transfer";
CM_ BO_ 2566834735 "Active diagnostic trouble codes";
CM_ BO_ 2566834721 "Active diagnostic trouble codes";
CM_ SG_ 2566834721 DM1_FlashRedStopLamp "This parameter provides the capability to flash the RSL (SPN 3039).";
CM_ SG_ 2566834721 DM1_FlashProtectLamp "This parameter provides the capability to flash the engine protect lamp (SPN 3041).";
CM_ SG_ 2566834721 DM1_FlashMalfuncIndicatorLamp "This parameter provides the capability to flash the MIL (SPN 3038).";
CM_ SG_ 2566834721 DM1_FlashAmberWarningLamp "This parameter provides the capability to flash the AWL (SPN 3040). ";
CM_ SG_ 2566834721 DM1_MalfunctionIndicatorLampSt "A lamp used to relay only emissions-related trouble code information.";
CM_ SG_ 2566834721 DM1_AmberWarningLampStatus "This lamp is used to relay trouble code information that is reporting a problem with the vehicle system but the vehicle need
not be immediately stopped.";
CM_ SG_ 2566834721 DM1_RedStopLampState "This lamp is uesed to relay trouble code information that is of a severe enought condition that it warrants stopping the vehicle.";
CM_ SG_ 2566834721 DM1_ProtectLampStatus "This lamp is used to relay trouble code informatio that is reporting a problem with a vehicle system that is most
probably not electronic subsystem related.";
CM_ BO_ 2348876549 "Transmission Control 1";
CM_ SG_ 2348876549 MessageCounter "The message counter is used to detect situations where the transmitting ECU malfunction repeats the same frame all the time.";
CM_ SG_ 2348876549 MessageChecksum "The checksum is used to verify the signal path from the transmitting device to the receiving device.The checksum is used to verify the signal path from the transmitting device to the receiving device.The checksum is used to verify the signal path from the transmitting device to the receiving device.";
CM_ SG_ 2566834736 AmberWarningLampStatus "This lamp is used to relay trouble code information that is reporting a problem with the vehicle system but the vehicle need
not be immediately stopped.";
CM_ SG_ 2566775343 AirSuspensionSupplyPress "The pneumatic pressure in the circuit for the electronically controlled air suspension system.";
CM_ SG_ 2566775343 AuxEquipSupplyPressure "The pneumatic pressure in the auxiliary circuit.";
CM_ SG_ 2566775343 ServiceBrakeAirPressRqCircuit2 "Command signal to influence the pneumatic pressure in the service brake circuit or reservoir #2.";
CM_ SG_ 2566775343 ServiceBrakeAirPressRqCircuit1 "Command signal to influence the pneumatic pressure in the service brake circuit or reservoir #1.";
CM_ BO_ 2566834691 "Active diagnostic trouble codes";
CM_ SG_ 2566834691 FlashRedStopLamp "This parameter provides the capability to flash the RSL (SPN 3039).";
CM_ SG_ 2566834691 FlashProtectLamp "This parameter provides the capability to flash the engine protect lamp (SPN 3041).";
CM_ SG_ 2566834691 FlashMalfuncIndicatorLamp "This parameter provides the capability to flash the MIL (SPN 3038).";
CM_ SG_ 2566834691 FlashAmberWarningLamp "This parameter provides the capability to flash the AWL (SPN 3040). ";
CM_ SG_ 2566834691 MalfunctionIndicatorLampStatus "A lamp used to relay only emissions-related trouble code information.";
CM_ SG_ 2566834691 AmberWarningLampStatus "This lamp is used to relay trouble code information that is reporting a problem with the vehicle system but the vehicle need
not be immediately stopped.";
CM_ SG_ 2566834691 RedStopLampState "This lamp is uesed to relay trouble code information that is of a severe enought condition that it warrants stopping the vehicle.";
CM_ SG_ 2566834691 ProtectLampStatus "This lamp is used to relay trouble code informatio that is reporting a problem with a vehicle system that is most
probably not electronic subsystem related.";
CM_ BO_ 2566834739 "Active diagnostic trouble codes";
CM_ SG_ 2566834739 FlashRedStopLamp "This parameter provides the capability to flash the RSL (SPN 3039).";
CM_ SG_ 2566834739 FlashProtectLamp "This parameter provides the capability to flash the engine protect lamp (SPN 3041).";
CM_ SG_ 2566834739 FlashMalfuncIndicatorLamp "This parameter provides the capability to flash the MIL (SPN 3038).";
CM_ SG_ 2566834739 FlashAmberWarningLamp "This parameter provides the capability to flash the AWL (SPN 3040). ";
CM_ SG_ 2566834739 MalfunctionIndicatorLampStatus "A lamp used to relay only emissions-related trouble code information.";
CM_ SG_ 2566834739 AmberWarningLampStatus "This lamp is used to relay trouble code information that is reporting a problem with the vehicle system but the vehicle need
not be immediately stopped.";
CM_ SG_ 2566834739 RedStopLampState "This lamp is uesed to relay trouble code information that is of a severe enought condition that it warrants stopping the vehicle.";
CM_ SG_ 2566834739 ProtectLampStatus "This lamp is used to relay trouble code informatio that is reporting a problem with a vehicle system that is most
probably not electronic subsystem related.";
CM_ SG_ 2566834739 DTC5 "Diagnostic Trouble Code";
CM_ SG_ 2566834739 DTC4 "Diagnostic Trouble Code";
CM_ SG_ 2566834739 DTC3 "Diagnostic Trouble Code";
CM_ SG_ 2566834739 DTC2 "Diagnostic Trouble Code";
CM_ SG_ 2566834739 DTC1 "Diagnostic Trouble Code";
BA_DEF_ SG_  "SigType" ENUM  "Default","Range","RangeSigned","ASCII","Discrete","Control","ReferencePGN","DTC","StringDelimiter","StringLength","StringLengthControl";
BA_DEF_ SG_  "GenSigStartValue" INT 0 10000;
BA_DEF_ SG_  "GenSigSendType" ENUM  "Cyclic","OnWrite","reserved","OnChange","reserved","reserved","reserved","NoSigSendType";
BA_DEF_ SG_  "GenSigILSupport" ENUM  "Yes","No";
BA_DEF_ SG_  "GenSigEVName" STRING ;
BA_DEF_ SG_  "SPN" INT 0 524287;
BA_DEF_ BO_  "GenMsgStartDelayTime" INT 0 100000;
BA_DEF_ BO_  "GenMsgILSupport" ENUM  "Yes","No";
BA_DEF_ BO_  "GenMsgDelayTime" INT 0 1000;
BA_DEF_ BO_  "GenMsgRequestable" INT 0 1;
BA_DEF_ BO_  "GenMsgSendType" ENUM  "cyclic","Spontaneus","cyclicIfActive","reserved","reserved","reserved","reserved","reserved","noMsgSendType","OnRequest";
BA_DEF_ BO_  "VFrameFormat" ENUM  "StandardCAN","ExtendedCAN","reserved","J1939PG";
BA_DEF_ BO_  "GenMsgCycleTime" INT 0 3600000;
BA_DEF_ BU_  "NmStationAddress" INT 0 255;
BA_DEF_  "DatabaseVersion" STRING ;
BA_DEF_  "BusType" STRING ;
BA_DEF_  "DBName" STRING ;
BA_DEF_  "ProtocolType" STRING ;
BA_DEF_  "SAE_J1939_75_SpecVersion" STRING ;
BA_DEF_  "SAE_J1939_21_SpecVersion" STRING ;
BA_DEF_  "SAE_J1939_73_SpecVersion" STRING ;
BA_DEF_  "SAE_J1939_71_SpecVersion" STRING ;
BA_DEF_ SG_  "SystemSignalLongSymbol" STRING ;
BA_DEF_DEF_  "SigType" "Default";
BA_DEF_DEF_  "GenSigStartValue" 0;
BA_DEF_DEF_  "GenSigSendType" "NoSigSendType";
BA_DEF_DEF_  "GenSigILSupport" "Yes";
BA_DEF_DEF_  "GenSigEVName" "Env@Nodename_@Signame";
BA_DEF_DEF_  "SPN" 0;
BA_DEF_DEF_  "GenMsgStartDelayTime" 0;
BA_DEF_DEF_  "GenMsgILSupport" "Yes";
BA_DEF_DEF_  "GenMsgDelayTime" 0;
BA_DEF_DEF_  "GenMsgRequestable" 1;
BA_DEF_DEF_  "GenMsgSendType" "noMsgSendType";
BA_DEF_DEF_  "VFrameFormat" "J1939PG";
BA_DEF_DEF_  "GenMsgCycleTime" 0;
BA_DEF_DEF_  "NmStationAddress" 254;
BA_DEF_DEF_  "DatabaseVersion" "";
BA_DEF_DEF_  "BusType" "";
BA_DEF_DEF_  "DBName" "";
BA_DEF_DEF_  "ProtocolType" "";
BA_DEF_DEF_  "SAE_J1939_75_SpecVersion" "";
BA_DEF_DEF_  "SAE_J1939_21_SpecVersion" "";
BA_DEF_DEF_  "SAE_J1939_73_SpecVersion" "";
BA_DEF_DEF_  "SAE_J1939_71_SpecVersion" "";
BA_DEF_DEF_  "SystemSignalLongSymbol" "";
BA_ "SAE_J1939_71_SpecVersion" "2009-09";
BA_ "SAE_J1939_73_SpecVersion" "2009-09";
BA_ "SAE_J1939_21_SpecVersion" "2006-10";
BA_ "SAE_J1939_75_SpecVersion" "2005-10";
BA_ "ProtocolType" "J1939";
BA_ "BusType" "CAN";
BA_ "DatabaseVersion" "7.2";
BA_ "DBName" "VCAN";
BA_ "NmStationAddress" BU_ LMFS 6;
BA_ "NmStationAddress" BU_ RMFS 5;
BA_ "NmStationAddress" BU_ TPMS 51;
BA_ "NmStationAddress" BU_ TCU_ERAGLONASS 74;
BA_ "NmStationAddress" BU_ E_APU 48;
BA_ "NmStationAddress" BU_ PCCM 28;
BA_ "NmStationAddress" BU_ NOX_2 82;
BA_ "NmStationAddress" BU_ NOX_1 81;
BA_ "NmStationAddress" BU_ ENGINE_CONTROL_MODULE 0;
BA_ "NmStationAddress" BU_ TRANSMISSION 3;
BA_ "NmStationAddress" BU_ INTARDER 16;
BA_ "NmStationAddress" BU_ EBS 11;
BA_ "NmStationAddress" BU_ TACHOGRAPH 238;
BA_ "NmStationAddress" BU_ INSTRUMENT_CLUSTER 23;
BA_ "NmStationAddress" BU_ CAMERA 232;
BA_ "NmStationAddress" BU_ RADAR 42;
BA_ "NmStationAddress" BU_ BCM 33;
BA_ "GenMsgSendType" BO_ 2633935919 0;
BA_ "GenMsgCycleTime" BO_ 2633935919 5000;
BA_ "GenMsgSendType" BO_ 2566848801 9;
BA_ "GenMsgCycleTime" BO_ 2566848768 100;
BA_ "GenMsgSendType" BO_ 2566848768 0;
BA_ "GenMsgCycleTime" BO_ 2566848512 100;
BA_ "GenMsgSendType" BO_ 2566848512 0;
BA_ "GenMsgCycleTime" BO_ 2566849308 1000;
BA_ "GenMsgSendType" BO_ 2566849308 0;
BA_ "GenMsgSendType" BO_ 2566848545 0;
BA_ "GenMsgCycleTime" BO_ 2566848545 100;
BA_ "GenMsgCycleTime" BO_ 2566782999 1000;
BA_ "GenMsgSendType" BO_ 2566782999 0;
BA_ "GenMsgCycleTime" BO_ 2566849052 100;
BA_ "GenMsgSendType" BO_ 2566849052 0;
BA_ "GenMsgSendType" BO_ 2566848535 0;
BA_ "GenMsgCycleTime" BO_ 2566848535 1000;
BA_ "GenMsgCycleTime" BO_ 2566834694 1000;
BA_ "GenMsgSendType" BO_ 2566834694 0;
BA_ "GenMsgCycleTime" BO_ 2566834693 1000;
BA_ "GenMsgSendType" BO_ 2566834693 2;
BA_ "GenMsgSendType" BO_ 2566849057 0;
BA_ "GenMsgCycleTime" BO_ 2566849057 1000;
BA_ "GenMsgCycleTime" BO_ 2565472256 1000;
BA_ "GenMsgSendType" BO_ 2348814341 2;
BA_ "GenMsgCycleTime" BO_ 2348814341 100;
BA_ "GenMsgSendType" BO_ 2565603075 1;
BA_ "GenMsgCycleTime" BO_ 2565603075 50;
BA_ "GenMsgSendType" BO_ 2565668611 1;
BA_ "GenMsgCycleTime" BO_ 2565668611 1000;
BA_ "GenMsgSendType" BO_ 2565603088 1;
BA_ "GenMsgCycleTime" BO_ 2565603088 50;
BA_ "GenMsgSendType" BO_ 2565668624 1;
BA_ "GenMsgCycleTime" BO_ 2565668624 5000;
BA_ "GenMsgSendType" BO_ 2565603087 1;
BA_ "GenMsgCycleTime" BO_ 2565603087 50;
BA_ "GenMsgSendType" BO_ 2565668623 1;
BA_ "GenMsgCycleTime" BO_ 2565668623 5000;
BA_ "GenMsgCycleTime" BO_ 2565603072 50;
BA_ "GenMsgSendType" BO_ 2565603072 1;
BA_ "GenMsgCycleTime" BO_ 2565668608 5000;
BA_ "GenMsgSendType" BO_ 2565668608 1;
BA_ "GenMsgCycleTime" BO_ 2565603310 50;
BA_ "GenMsgSendType" BO_ 2565603310 1;
BA_ "GenMsgCycleTime" BO_ 2565668846 1000;
BA_ "GenMsgSendType" BO_ 2565668846 1;
BA_ "GenMsgCycleTime" BO_ 2565603095 50;
BA_ "GenMsgSendType" BO_ 2565603095 1;
BA_ "GenMsgCycleTime" BO_ 2565668631 1000;
BA_ "GenMsgSendType" BO_ 2565668631 1;
BA_ "GenMsgSendType" BO_ 2565603105 1;
BA_ "GenMsgCycleTime" BO_ 2565603105 50;
BA_ "GenMsgSendType" BO_ 2565668641 1;
BA_ "GenMsgCycleTime" BO_ 2565668641 1000;
BA_ "GenMsgSendType" BO_ 2565537768 9;
BA_ "GenMsgCycleTime" BO_ 2565864243 2000;
BA_ "GenMsgCycleTime" BO_ 2566844711 100;
BA_ "GenMsgSendType" BO_ 2566844711 0;
BA_ "GenMsgCycleTime" BO_ 2566907955 100;
BA_ "GenMsgSendType" BO_ 2565668606 1;
BA_ "GenMsgSendType" BO_ 2565603070 1;
BA_ "GenMsgCycleTime" BO_ 2566834735 1000;
BA_ "GenMsgSendType" BO_ 2566834735 1;
BA_ "GenMsgCycleTime" BO_ 2566834721 1000;
BA_ "GenMsgSendType" BO_ 2566834721 2;
BA_ "GenMsgSendType" BO_ 2566852650 2;
BA_ "GenMsgCycleTime" BO_ 2566852650 100;
BA_ "GenMsgSendType" BO_ 2566849866 2;
BA_ "GenMsgCycleTime" BO_ 2566849866 1000;
BA_ "GenMsgSendType" BO_ 2566856958 0;
BA_ "GenMsgCycleTime" BO_ 2566856958 100;
BA_ "GenMsgSendType" BO_ 2566870278 0;
BA_ "GenMsgCycleTime" BO_ 2566870278 100;
BA_ "GenMsgSendType" BO_ 2566870277 0;
BA_ "GenMsgCycleTime" BO_ 2566870277 100;
BA_ "GenMsgSendType" BO_ 2348876549 0;
BA_ "GenMsgCycleTime" BO_ 2348876549 50;
BA_ "GenMsgSendType" BO_ 2566848796 0;
BA_ "GenMsgCycleTime" BO_ 2566848796 100;
BA_ "GenMsgSendType" BO_ 2566834736 0;
BA_ "GenMsgCycleTime" BO_ 2566834736 1000;
BA_ "GenMsgCycleTime" BO_ 2566849024 1000;
BA_ "GenMsgCycleTime" BO_ 2566775343 1000;
BA_ "GenMsgSendType" BO_ 2566775343 0;
BA_ "GenMsgCycleTime" BO_ 2566864417 100;
BA_ "GenMsgSendType" BO_ 2566864417 0;
BA_ "GenMsgSendType" BO_ 2566810903 0;
BA_ "GenMsgCycleTime" BO_ 2566810903 1000;
BA_ "GenMsgCycleTime" BO_ 2566907927 100;
BA_ "GenMsgSendType" BO_ 2566907927 2;
BA_ "GenMsgCycleTime" BO_ 2566834691 1000;
BA_ "GenMsgSendType" BO_ 2566834691 2;
BA_ "GenMsgSendType" BO_ 2566834739 2;
BA_ "GenMsgCycleTime" BO_ 2566834739 1000;
BA_ "GenMsgCycleTime" BO_ 2566907699 60000;
BA_ "GenMsgSendType" BO_ 2566907443 0;
BA_ "GenMsgCycleTime" BO_ 2566907443 200;
BA_ "SigType" SG_ 3221225472 ACCSetDistanceMode 1;
BA_ "SPN" SG_ 3221225472 ACCSetDistanceMode 84;
BA_ "SigType" SG_ 3221225472 ACCMode 1;
BA_ "SPN" SG_ 3221225472 ACCMode 84;
BA_ "SigType" SG_ 3221225472 ACCSetSpeed 1;
BA_ "SPN" SG_ 3221225472 ACCSetSpeed 84;
BA_ "SigType" SG_ 3221225472 DistancetoForwardVehicle 1;
BA_ "SPN" SG_ 3221225472 DistancetoForwardVehicle 84;
BA_ "SigType" SG_ 3221225472 SpeedofForwardVehicle 1;
BA_ "SPN" SG_ 3221225472 SpeedofForwardVehicle 84;
BA_ "GenSigEVName" SG_ 3221225472 TesterReqTransmission "TesterReqRadar";
BA_ "GenSigSendType" SG_ 3221225472 TesterReqTransmission 3;
BA_ "GenSigEVName" SG_ 3221225472 TesterReqTachograpgh "TesterReqTachograpgh";
BA_ "GenSigSendType" SG_ 3221225472 TesterReqTachograpgh 3;
BA_ "SPN" SG_ 3221225472 TrailerWeight 180;
BA_ "SigType" SG_ 3221225472 TrailerWeight 1;
BA_ "SPN" SG_ 3221225472 ReferenceTirePressSetting 3193;
BA_ "SigType" SG_ 3221225472 ReferenceTirePressSetting 1;
BA_ "SPN" SG_ 3221225472 ReferenceTirePress 3191;
BA_ "SigType" SG_ 3221225472 ReferenceTirePress 1;
BA_ "SPN" SG_ 3221225472 TirePressThresholdDetection 2587;
BA_ "SigType" SG_ 3221225472 TirePressThresholdDetection 4;
BA_ "SPN" SG_ 3221225472 TireAirLeakageRate 2586;
BA_ "SigType" SG_ 3221225472 TireAirLeakageRate 1;
BA_ "SPN" SG_ 3221225472 CTIWheelEndElectricalFault 1697;
BA_ "SigType" SG_ 3221225472 CTIWheelEndElectricalFault 4;
BA_ "SPN" SG_ 3221225472 CTITireStatus 1698;
BA_ "SigType" SG_ 3221225472 CTITireStatus 4;
BA_ "SPN" SG_ 3221225472 CTIWheelSensorStatus 1699;
BA_ "SigType" SG_ 3221225472 CTIWheelSensorStatus 4;
BA_ "SPN" SG_ 3221225472 TireTemp 242;
BA_ "SigType" SG_ 3221225472 TireTemp 1;
BA_ "SPN" SG_ 3221225472 TirePress 241;
BA_ "SigType" SG_ 3221225472 TirePress 1;
BA_ "SPN" SG_ 3221225472 AntitheftRandomNumber 1198;
BA_ "SigType" SG_ 3221225472 AntitheftRandomNumber 1;
BA_ "SPN" SG_ 3221225472 AntitheftComponentStatusStates 1196;
BA_ "SigType" SG_ 3221225472 AntitheftComponentStatusStates 4;
BA_ "SPN" SG_ 3221225472 AntthftEncryptnSdPrsntIndicator 1194;
BA_ "SigType" SG_ 3221225472 AntthftEncryptnSdPrsntIndicator 4;
BA_ "SPN" SG_ 3221225472 AntitheftModifyPwdStates 1197;
BA_ "SigType" SG_ 3221225472 AntitheftModifyPwdStates 4;
BA_ "SPN" SG_ 3221225472 AntitheftPwdValidIndicator 1195;
BA_ "SigType" SG_ 3221225472 AntitheftPwdValidIndicator 4;
BA_ "SPN" SG_ 3221225472 EngBuildHoursReset 1211;
BA_ "SigType" SG_ 3221225472 EngBuildHoursReset 4;
BA_ "SPN" SG_ 3221225472 SteerStraightAheadPosReset 3600;
BA_ "SigType" SG_ 3221225472 SteerStraightAheadPosReset 4;
BA_ "SPN" SG_ 3221225472 ServiceComponentIdentification 1584;
BA_ "SigType" SG_ 3221225472 ServiceComponentIdentification 1;
BA_ "SPN" SG_ 3221225472 ServiceComponentIdentificationC 1584;
BA_ "SigType" SG_ 3221225472 ServiceComponentIdentificationC 1;
BA_ "GenSigStartValue" SG_ 3221225472 ATR_Notdefined 255;
BA_ "SPN" SG_ 3221225472 TrnsShftSlctorDisplayModeSwitch 2985;
BA_ "SigType" SG_ 3221225472 TrnsShftSlctorDisplayModeSwitch 4;
BA_ "SPN" SG_ 3221225472 TransMode4 1855;
BA_ "SigType" SG_ 3221225472 TransMode4 4;
BA_ "SPN" SG_ 3221225472 TransMode3 1854;
BA_ "SigType" SG_ 3221225472 TransMode3 4;
BA_ "SPN" SG_ 3221225472 TransMode2 1853;
BA_ "SigType" SG_ 3221225472 TransMode2 4;
BA_ "SPN" SG_ 3221225472 DisengageDiffLockRqCentralRear 691;
BA_ "SigType" SG_ 3221225472 DisengageDiffLockRqCentralRear 4;
BA_ "SPN" SG_ 3221225472 DisengageDiffLockRqCentralFront 690;
BA_ "SigType" SG_ 3221225472 DisengageDiffLockRqCentralFront 4;
BA_ "SPN" SG_ 3221225472 DisengageDiffLockRqCentral 689;
BA_ "SigType" SG_ 3221225472 DisengageDiffLockRqCentral 4;
BA_ "SPN" SG_ 3221225472 DisengageDiffLockRqRearAxle2 688;
BA_ "SigType" SG_ 3221225472 DisengageDiffLockRqRearAxle2 4;
BA_ "SPN" SG_ 3221225472 DisengageDiffLockRqRearAxle1 687;
BA_ "SigType" SG_ 3221225472 DisengageDiffLockRqRearAxle1 4;
BA_ "SPN" SG_ 3221225472 DisengageDiffLockRqFrontAxle2 686;
BA_ "SigType" SG_ 3221225472 DisengageDiffLockRqFrontAxle2 4;
BA_ "SPN" SG_ 3221225472 DisengageDiffLockRqFrontAxle1 685;
BA_ "SigType" SG_ 3221225472 DisengageDiffLockRqFrontAxle1 4;
BA_ "SPN" SG_ 3221225472 TransRqedGear 525;
BA_ "SigType" SG_ 3221225472 TransRqedGear 1;
BA_ "SPN" SG_ 3221225472 RqedPercentClutchSlip 684;
BA_ "SigType" SG_ 3221225472 RqedPercentClutchSlip 1;
BA_ "SPN" SG_ 3221225472 DisengageDrivelineRq 683;
BA_ "SigType" SG_ 3221225472 DisengageDrivelineRq 4;
BA_ "SPN" SG_ 3221225472 TrnsTrqConverterLockupDisableRq 682;
BA_ "SigType" SG_ 3221225472 TrnsTrqConverterLockupDisableRq 4;
BA_ "SPN" SG_ 3221225472 TransRqedLaunchGear 4255;
BA_ "SigType" SG_ 3221225472 TransRqedLaunchGear 4;
BA_ "SPN" SG_ 3221225472 TransReverseGearShiftInhibitRq 4242;
BA_ "SigType" SG_ 3221225472 TransReverseGearShiftInhibitRq 4;
BA_ "SPN" SG_ 3221225472 TransMode8 4249;
BA_ "SigType" SG_ 3221225472 TransMode8 4;
BA_ "SPN" SG_ 3221225472 TransMode7 4248;
BA_ "SigType" SG_ 3221225472 TransMode7 4;
BA_ "SPN" SG_ 3221225472 TransMode6 4247;
BA_ "SigType" SG_ 3221225472 TransMode6 4;
BA_ "SPN" SG_ 3221225472 TransMode5 4246;
BA_ "SigType" SG_ 3221225472 TransMode5 4;
BA_ "SPN" SG_ 3221225472 MessageCounter 4206;
BA_ "SPN" SG_ 3221225472 ControlPurpose 3350;
BA_ "SPN" SG_ 3221225472 TransmissionRate 3349;
BA_ "SPN" SG_ 3221225472 EngineRequestedTorqueHiRes 4191;
BA_ "SPN" SG_ 3221225472 PrkngBrkeActuatorFullyActivated 5275;
BA_ "SigType" SG_ 3221225472 PrkngBrkeActuatorFullyActivated 4;
BA_ "SPN" SG_ 3221225472 DslPrtcltFltrActvRgnrtnFrcdStts 4175;
BA_ "SigType" SG_ 3221225472 DslPrtcltFltrActvRgnrtnFrcdStts 4;
BA_ "SPN" SG_ 3221225472 ExhaustSystemHighTempLampCmd 3698;
BA_ "SigType" SG_ 3221225472 ExhaustSystemHighTempLampCmd 4;
BA_ "SPN" SG_ 3221225472 DslPrtcltFltrAtmtcActvRgnrtnIntt 3718;
BA_ "SigType" SG_ 3221225472 DslPrtcltFltrAtmtcActvRgnrtnIntt 4;
BA_ "SystemSignalLongSymbol" SG_ 3221225472 DslPrtcltFltrAtmtcActvRgnrtnIntt "DslPrtcltFltrAtmtcActvRgnrtnInttnCnfg";
BA_ "SPN" SG_ 3221225472 DslPrtcltFltrActvRgnrtnInhbtdDTV 3717;
BA_ "SigType" SG_ 3221225472 DslPrtcltFltrActvRgnrtnInhbtdDTV 4;
BA_ "SystemSignalLongSymbol" SG_ 3221225472 DslPrtcltFltrActvRgnrtnInhbtdDTV "DslPrtcltFltrActvRgnrtnInhbtdDTVhclSpdBlwAllwd";
BA_ "SPN" SG_ 3221225472 DslPrtcltFltrActvRgnrtnInhbtdDTE 3716;
BA_ "SigType" SG_ 3221225472 DslPrtcltFltrActvRgnrtnInhbtdDTE 4;
BA_ "SystemSignalLongSymbol" SG_ 3221225472 DslPrtcltFltrActvRgnrtnInhbtdDTE "DslPrtcltFltrActvRgnrtnInhbtdDTEngNtWrmdUp";
BA_ "SPN" SG_ 3221225472 DslPrtcltFltrActvRgnrtnInhbtdDTP 3715;
BA_ "SigType" SG_ 3221225472 DslPrtcltFltrActvRgnrtnInhbtdDTP 4;
BA_ "SystemSignalLongSymbol" SG_ 3221225472 DslPrtcltFltrActvRgnrtnInhbtdDTP "DslPrtcltFltrActvRgnrtnInhbtdDTPrmnntSystmLckt";
BA_ "SPN" SG_ 3221225472 DslPrtcltFltrActvRgnrtnInhbtdDTT 3714;
BA_ "SigType" SG_ 3221225472 DslPrtcltFltrActvRgnrtnInhbtdDTT 4;
BA_ "SystemSignalLongSymbol" SG_ 3221225472 DslPrtcltFltrActvRgnrtnInhbtdDTT "DslPrtcltFltrActvRgnrtnInhbtdDTTmprrySystmLckt";
BA_ "SPN" SG_ 3221225472 DslPrtcltFltrActvRgnrtnInhbtdDTS 3713;
BA_ "SigType" SG_ 3221225472 DslPrtcltFltrActvRgnrtnInhbtdDTS 4;
BA_ "SystemSignalLongSymbol" SG_ 3221225472 DslPrtcltFltrActvRgnrtnInhbtdDTS "DslPrtcltFltrActvRgnrtnInhbtdDTSystmTmt";
BA_ "SPN" SG_ 3221225472 DslPrtcltFltrActvRgnrtnInhb_0000 3712;
BA_ "SigType" SG_ 3221225472 DslPrtcltFltrActvRgnrtnInhb_0000 4;
BA_ "SystemSignalLongSymbol" SG_ 3221225472 DslPrtcltFltrActvRgnrtnInhb_0000 "DslPrtcltFltrActvRgnrtnInhbtdDTSystmFltActv";
BA_ "SPN" SG_ 3221225472 DslPrtcltFltrActvRgnrtnInhbtdDTL 3711;
BA_ "SigType" SG_ 3221225472 DslPrtcltFltrActvRgnrtnInhbtdDTL 4;
BA_ "SystemSignalLongSymbol" SG_ 3221225472 DslPrtcltFltrActvRgnrtnInhbtdDTL "DslPrtcltFltrActvRgnrtnInhbtdDTLwExhstGsTmp";
BA_ "SPN" SG_ 3221225472 DslPrtcltFltrActvRgnrtnInhb_0001 3710;
BA_ "SigType" SG_ 3221225472 DslPrtcltFltrActvRgnrtnInhb_0001 4;
BA_ "SystemSignalLongSymbol" SG_ 3221225472 DslPrtcltFltrActvRgnrtnInhb_0001 "DslPrtcltFltrActvRgnrtnInhbtdDTPrkngBrkNtSt";
BA_ "SPN" SG_ 3221225472 DslPrtcltFltrActvRgnrtnInhb_0002 3709;
BA_ "SigType" SG_ 3221225472 DslPrtcltFltrActvRgnrtnInhb_0002 4;
BA_ "SystemSignalLongSymbol" SG_ 3221225472 DslPrtcltFltrActvRgnrtnInhb_0002 "DslPrtcltFltrActvRgnrtnInhbtdDTVhclSpdAbvAllwd";
BA_ "SPN" SG_ 3221225472 DslPrtcltFltrActvRgnrtnInhbtdDTO 3708;
BA_ "SigType" SG_ 3221225472 DslPrtcltFltrActvRgnrtnInhbtdDTO 4;
BA_ "SystemSignalLongSymbol" SG_ 3221225472 DslPrtcltFltrActvRgnrtnInhbtdDTO "DslPrtcltFltrActvRgnrtnInhbtdDTOtOfNtrl";
BA_ "SPN" SG_ 3221225472 DslPrtcltFltrActvRgnrtnInhbtdDTA 3707;
BA_ "SigType" SG_ 3221225472 DslPrtcltFltrActvRgnrtnInhbtdDTA 4;
BA_ "SystemSignalLongSymbol" SG_ 3221225472 DslPrtcltFltrActvRgnrtnInhbtdDTA "DslPrtcltFltrActvRgnrtnInhbtdDTAcclPdlOffIdl";
BA_ "SPN" SG_ 3221225472 DslPrtcltFltrActvRgnrtnInhb_0003 3706;
BA_ "SigType" SG_ 3221225472 DslPrtcltFltrActvRgnrtnInhb_0003 4;
BA_ "SystemSignalLongSymbol" SG_ 3221225472 DslPrtcltFltrActvRgnrtnInhb_0003 "DslPrtcltFltrActvRgnrtnInhbtdDTPTOActv";
BA_ "SPN" SG_ 3221225472 DslPrtcltFltrActvRgnrtnInhb_0004 3705;
BA_ "SigType" SG_ 3221225472 DslPrtcltFltrActvRgnrtnInhb_0004 4;
BA_ "SystemSignalLongSymbol" SG_ 3221225472 DslPrtcltFltrActvRgnrtnInhb_0004 "DslPrtcltFltrActvRgnrtnInhbtdDTSrvcBrkActv";
BA_ "SPN" SG_ 3221225472 DslPrtcltFltrActvRgnrtnInhbtdDTC 3704;
BA_ "SigType" SG_ 3221225472 DslPrtcltFltrActvRgnrtnInhbtdDTC 4;
BA_ "SystemSignalLongSymbol" SG_ 3221225472 DslPrtcltFltrActvRgnrtnInhbtdDTC "DslPrtcltFltrActvRgnrtnInhbtdDTCltchDsnggd";
BA_ "SPN" SG_ 3221225472 DslPrtcltFltrActvRgnrtnInhbtdDTI 3703;
BA_ "SigType" SG_ 3221225472 DslPrtcltFltrActvRgnrtnInhbtdDTI 4;
BA_ "SystemSignalLongSymbol" SG_ 3221225472 DslPrtcltFltrActvRgnrtnInhbtdDTI "DslPrtcltFltrActvRgnrtnInhbtdDTInhbtSwtch";
BA_ "SPN" SG_ 3221225472 DslPrtcltFltrActvRgnrtnInhbtdStt 3702;
BA_ "SigType" SG_ 3221225472 DslPrtcltFltrActvRgnrtnInhbtdStt 4;
BA_ "SystemSignalLongSymbol" SG_ 3221225472 DslPrtcltFltrActvRgnrtnInhbtdStt "DslPrtcltFltrActvRgnrtnInhbtdStts";
BA_ "SPN" SG_ 3221225472 DslPrtcltFltrActvRgnrtionStatus 3700;
BA_ "SigType" SG_ 3221225472 DslPrtcltFltrActvRgnrtionStatus 4;
BA_ "SPN" SG_ 3221225472 DslPrtcltFltrPssvRgnrtionStatus 3699;
BA_ "SigType" SG_ 3221225472 DslPrtcltFltrPssvRgnrtionStatus 4;
BA_ "SPN" SG_ 3221225472 DieselParticulateFilterLampCmd 3697;
BA_ "SigType" SG_ 3221225472 DieselParticulateFilterLampCmd 4;
BA_ "SPN" SG_ 3221225472 Aftrtrtmnt1SCRCtlystRgntTnk1HtrP 4366;
BA_ "SigType" SG_ 3221225472 Aftrtrtmnt1SCRCtlystRgntTnk1HtrP 1;
BA_ "SystemSignalLongSymbol" SG_ 3221225472 Aftrtrtmnt1SCRCtlystRgntTnk1HtrP "Aftrtrtmnt1SCRCtlystRgntTnk1HtrPrlmnryFMI";
BA_ "SPN" SG_ 3221225472 Aftrtrtmnt1SCRCtalystTankHeater 3363;
BA_ "SigType" SG_ 3221225472 Aftrtrtmnt1SCRCtalystTankHeater 1;
BA_ "SPN" SG_ 3221225472 AftrtrtmntSCROprtrIndcmntSvrity 5246;
BA_ "SigType" SG_ 3221225472 AftrtrtmntSCROprtrIndcmntSvrity 4;
BA_ "SPN" SG_ 3221225472 Aftrtrtmnt1SCRCtlystRgntTnk1TmpP 4365;
BA_ "SigType" SG_ 3221225472 Aftrtrtmnt1SCRCtlystRgntTnk1TmpP 1;
BA_ "SystemSignalLongSymbol" SG_ 3221225472 Aftrtrtmnt1SCRCtlystRgntTnk1TmpP "Aftrtrtmnt1SCRCtlystRgntTnk1TmpPrlmnryFMI";
BA_ "SPN" SG_ 3221225472 Aftrtrtmnt1DEFTnkLwLvlIndicator 5245;
BA_ "SigType" SG_ 3221225472 Aftrtrtmnt1DEFTnkLwLvlIndicator 4;
BA_ "SPN" SG_ 3221225472 Aftrtrtmnt1SCRCtlystTnkLvlPrlmnr 3532;
BA_ "SigType" SG_ 3221225472 Aftrtrtmnt1SCRCtlystTnkLvlPrlmnr 1;
BA_ "SystemSignalLongSymbol" SG_ 3221225472 Aftrtrtmnt1SCRCtlystTnkLvlPrlmnr "Aftrtrtmnt1SCRCtlystTnkLvlPrlmnryFMI";
BA_ "SPN" SG_ 3221225472 Aftrtrtmnt1SCRCtalystTankLevel2 3517;
BA_ "SigType" SG_ 3221225472 Aftrtrtmnt1SCRCtalystTankLevel2 1;
BA_ "SPN" SG_ 3221225472 Aftrtrtment1SCRCatalystTankTemp 3031;
BA_ "SigType" SG_ 3221225472 Aftrtrtment1SCRCatalystTankTemp 1;
BA_ "SPN" SG_ 3221225472 Aftrtrtmnt1SCRCatalystTankLevel 1761;
BA_ "SigType" SG_ 3221225472 Aftrtrtmnt1SCRCatalystTankLevel 1;
BA_ "SPN" SG_ 3221225472 EngShutdownOverrideSwitch 1237;
BA_ "SigType" SG_ 3221225472 EngShutdownOverrideSwitch 4;
BA_ "SPN" SG_ 3221225472 EngTestModeSwitch 966;
BA_ "SigType" SG_ 3221225472 EngTestModeSwitch 4;
BA_ "SPN" SG_ 3221225472 EngIdleDecrementSwitch 967;
BA_ "SigType" SG_ 3221225472 EngIdleDecrementSwitch 4;
BA_ "SPN" SG_ 3221225472 EngIdleIncrementSwitch 968;
BA_ "SigType" SG_ 3221225472 EngIdleIncrementSwitch 4;
BA_ "SPN" SG_ 3221225472 OprtrsDesiredDelayedLampOffTime 2877;
BA_ "SigType" SG_ 3221225472 OprtrsDesiredDelayedLampOffTime 1;
BA_ "SPN" SG_ 3221225472 CruiseCtrlStates 527;
BA_ "SPN" SG_ 3221225472 AxleWeight_30 522030;
BA_ "SigType" SG_ 3221225472 AxleWeight_30 1;
BA_ "SPN" SG_ 3221225472 AxleWeight_20 522020;
BA_ "SigType" SG_ 3221225472 AxleWeight_20 1;
BA_ "SPN" SG_ 3221225472 AxleWeight_10 522010;
BA_ "SigType" SG_ 3221225472 AxleWeight_10 1;
BA_ "SPN" SG_ 3221225472 AuxI_O08_GearboxNeutralPos 708;
BA_ "SigType" SG_ 3221225472 AuxI_O08_GearboxNeutralPos 4;
BA_ "SPN" SG_ 3221225472 AuxI_O07_TrailerABSFulOper 707;
BA_ "SigType" SG_ 3221225472 AuxI_O07_TrailerABSFulOper 4;
BA_ "SPN" SG_ 3221225472 AuxI_O06_TrailerABSDetected 706;
BA_ "SigType" SG_ 3221225472 AuxI_O06_TrailerABSDetected 4;
BA_ "SPN" SG_ 3221225472 AuxI_O05_TrailerConnected 705;
BA_ "SigType" SG_ 3221225472 AuxI_O05_TrailerConnected 4;
BA_ "GenSigStartValue" SG_ 3221225472 AuxI_O05_TrailerConnected 3;
BA_ "SPN" SG_ 3221225472 AuxI_O02_BlendingSwitchPos 702;
BA_ "SigType" SG_ 3221225472 AuxI_O02_BlendingSwitchPos 4;
BA_ "SigType" SG_ 3221225472 PCCM_TransReqGearPriority 1;
BA_ "SPN" SG_ 3221225472 PCCM_TransReqGearPriority 86;
BA_ "SigType" SG_ 3221225472 PCCM_TransGearShiftRequest 1;
BA_ "SPN" SG_ 3221225472 PCCM_TransGearShiftRequest 86;
BA_ "GenSigStartValue" SG_ 3221225472 ATS_Notdefined 255;
BA_ "SigType" SG_ 3221225472 PCCMaxPosSpdOffset 1;
BA_ "GenSigStartValue" SG_ 3221225472 PCCMaxPosSpdOffset 250;
BA_ "SPN" SG_ 3221225472 PCCMaxPosSpdOffset 1090;
BA_ "SPN" SG_ 3221225472 PCCMaxNegSpdOffset 1090;
BA_ "SigType" SG_ 3221225472 PCCMaxNegSpdOffset 1;
BA_ "GenSigStartValue" SG_ 3221225472 PCCMaxNegSpdOffset 250;
BA_ "SigType" SG_ 3221225472 TrailerBrakeStatus 4;
BA_ "SPN" SG_ 3221225472 TrailerBrakeStatus 1836;
BA_ "SPN" SG_ 3221225472 AuxHeaterMode 1677;
BA_ "SigType" SG_ 3221225472 AuxHeaterMode 4;
BA_ "SPN" SG_ 3221225472 EngThrottleValve2Pos 3673;
BA_ "SigType" SG_ 3221225472 EngThrottleValve2Pos 1;
BA_ "SPN" SG_ 3221225472 AuxEquipmentSupplyPress 1089;
BA_ "SigType" SG_ 3221225472 AuxEquipmentSupplyPress 1;
BA_ "GenSigStartValue" SG_ 3221225472 AuxEquipmentSupplyPress 31.875;
BA_ "SigType" SG_ 3221225472 VhclSped_Ctrl_Override_Request 1;
BA_ "SPN" SG_ 3221225472 VhclSped_Ctrl_Override_Request 86;
BA_ "SigType" SG_ 3221225472 VhclSped_Ctrl_Override_EvntIndic 1;
BA_ "SPN" SG_ 3221225472 VhclSped_Ctrl_Override_EvntIndic 86;
BA_ "SigType" SG_ 3221225472 PreCru_CtrlDriv_Disgage_inhbtReq 1;
BA_ "SPN" SG_ 3221225472 PreCru_CtrlDriv_Disgage_inhbtReq 86;
BA_ "SigType" SG_ 3221225472 PreCru_Ctrl_SpeedEventIndicator 1;
BA_ "SPN" SG_ 3221225472 PreCru_Ctrl_SpeedEventIndicator 86;
BA_ "SigType" SG_ 3221225472 PreCru_Ctrl_NextGrade 1;
BA_ "SPN" SG_ 3221225472 PreCru_Ctrl_NextGrade 86;
BA_ "SigType" SG_ 3221225472 PreCru_Ctrl_EventinRange 1;
BA_ "SPN" SG_ 3221225472 PreCru_Ctrl_EventinRange 86;
BA_ "SigType" SG_ 3221225472 AuxI_O03_RetarderLeverPos 4;
BA_ "SPN" SG_ 3221225472 AuxI_O03_RetarderLeverPos 702;
BA_ "SigType" SG_ 3221225472 GearShiftPriority 4;
BA_ "SPN" SG_ 3221225472 GearShiftPriority 2970;
BA_ "SPN" SG_ 3221225472 CruiseCtrlLowSetLimitSpeed 88;
BA_ "SigType" SG_ 3221225472 CruiseCtrlLowSetLimitSpeed 1;
BA_ "SPN" SG_ 3221225472 CruiseCtrlHighSetLimitSpeed 87;
BA_ "SigType" SG_ 3221225472 CruiseCtrlHighSetLimitSpeed 1;
BA_ "SPN" SG_ 3221225472 MaxVehicleSpeedLimit 74;
BA_ "SigType" SG_ 3221225472 MaxVehicleSpeedLimit 1;
BA_ "SPN" SG_ 3221225472 FlashRedStopLamp 3039;
BA_ "SigType" SG_ 3221225472 FlashRedStopLamp 4;
BA_ "SPN" SG_ 3221225472 FlashProtectLamp 3041;
BA_ "SigType" SG_ 3221225472 FlashProtectLamp 4;
BA_ "SPN" SG_ 3221225472 FlashMalfuncIndicatorLamp 3038;
BA_ "SigType" SG_ 3221225472 FlashMalfuncIndicatorLamp 4;
BA_ "SPN" SG_ 3221225472 FlashAmberWarningLamp 3040;
BA_ "SigType" SG_ 3221225472 FlashAmberWarningLamp 4;
BA_ "SPN" SG_ 3221225472 MalfunctionIndicatorLampStatus 1213;
BA_ "SigType" SG_ 3221225472 MalfunctionIndicatorLampStatus 4;
BA_ "SPN" SG_ 3221225472 AmberWarningLampStatus 624;
BA_ "SigType" SG_ 3221225472 AmberWarningLampStatus 4;
BA_ "SPN" SG_ 3221225472 ProtectLampStatus 987;
BA_ "SigType" SG_ 3221225472 ProtectLampStatus 4;
BA_ "SigType" SG_ 3221225472 DTC5 7;
BA_ "SigType" SG_ 3221225472 DTC4 7;
BA_ "SigType" SG_ 3221225472 DTC3 7;
BA_ "SigType" SG_ 3221225472 DTC2 7;
BA_ "SigType" SG_ 3221225472 DTC1 7;
BA_ "SPN" SG_ 3221225472 SCRThermalManagementActive 5400;
BA_ "SigType" SG_ 3221225472 SCRThermalManagementActive 4;
BA_ "SPN" SG_ 3221225472 MmntryEngMaxPowerEnableFeedback 5021;
BA_ "SigType" SG_ 3221225472 MmntryEngMaxPowerEnableFeedback 4;
BA_ "SPN" SG_ 3221225472 DPFThermalManagementActive 5399;
BA_ "SigType" SG_ 3221225472 DPFThermalManagementActive 4;
BA_ "SPN" SG_ 3221225472 TwoSpeedAxleSwitch 69;
BA_ "SigType" SG_ 3221225472 TwoSpeedAxleSwitch 4;
BA_ "SPN" SG_ 3221225472 EngIntakeManifold1Press 102;
BA_ "SigType" SG_ 3221225472 EngIntakeManifold1Press 1;
BA_ "SPN" SG_ 3221225472 FreezeFrameLength 1217;
BA_ "SPN" SG_ 3221225472 EngSpeed 190;
BA_ "SigType" SG_ 3221225472 EngSpeed 1;
BA_ "SPN" SG_ 3221225472 EngTorqueMode 899;
BA_ "SigType" SG_ 3221225472 EngTorqueMode 4;
BA_ "SPN" SG_ 3221225472 WheelBasedVehicleSpeed 84;
BA_ "SigType" SG_ 3221225472 WheelBasedVehicleSpeed 1;
BA_ "SPN" SG_ 3221225472 EngPercentLoadAtCurrentSpeed 92;
BA_ "SigType" SG_ 3221225472 EngPercentLoadAtCurrentSpeed 1;
BA_ "SPN" SG_ 3221225472 EngineCoolantTemperature 110;
BA_ "SigType" SG_ 3221225472 EngineCoolantTemperature 1;
BA_ "GenSigStartValue" SG_ 3221225472 MeasuredMotorControllerTemp 873.6;
BA_ "SPN" SG_ 3221225472 RedStopLampState 623;
BA_ "SigType" SG_ 3221225472 RedStopLampState 4;
BA_ "SPN" SG_ 3221225472 ParkingBrakeSwitch_BCM 70;
BA_ "SigType" SG_ 3221225472 ParkingBrakeSwitch_BCM 4;
BA_ "SPN" SG_ 3221225472 ParkBrakeReleaseInhibitRq 3807;
BA_ "SigType" SG_ 3221225472 ParkBrakeReleaseInhibitRq 4;
BA_ "SPN" SG_ 3221225472 CruiseCtrlPauseSwitch 1633;
BA_ "SigType" SG_ 3221225472 CruiseCtrlPauseSwitch 4;
BA_ "SPN" SG_ 3221225472 BremsomatConfiguration 2913;
BA_ "SPN" SG_ 3221225472 TotalNumberOfPacketsEoMA 2558;
BA_ "SPN" SG_ 3221225472 TotalMessageSizeEoMA 2557;
BA_ "SPN" SG_ 3221225472 TotalMessageSizeBAM 2557;
BA_ "SPN" SG_ 3221225472 TotalNumberOfPacketsBAM 2558;
BA_ "SPN" SG_ 3221225472 ConnectionAbortReason 2570;
BA_ "SPN" SG_ 3221225472 NextPacketNumberToBeSent 2562;
BA_ "SPN" SG_ 3221225472 NumberOfPacketsThatCanBeSent 2561;
BA_ "SPN" SG_ 3221225472 PGNumber 2560;
BA_ "SigType" SG_ 3221225472 PGNumber 6;
BA_ "SPN" SG_ 3221225472 MaximumNumberOfPackets 2559;
BA_ "SPN" SG_ 3221225472 TotalNumberOfPackets 2558;
BA_ "SPN" SG_ 3221225472 TotalMessageSize 2557;
BA_ "SPN" SG_ 3221225472 ControlByte 2556;
BA_ "SPN" SG_ 3221225472 SequenceNumber 2572;
BA_ "GenSigEVName" SG_ 3221225472 TesterReqPCCM "TesterReqPCCM";
BA_ "GenSigSendType" SG_ 3221225472 TesterReqPCCM 3;
BA_ "GenSigEVName" SG_ 3221225472 TesterReqIntarder "TesterReqIntarder";
BA_ "GenSigSendType" SG_ 3221225472 TesterReqIntarder 3;
BA_ "GenSigEVName" SG_ 3221225472 TesterReqEAPU "TesterReqEAPU";
BA_ "GenSigSendType" SG_ 3221225472 TesterReqEAPU 3;
BA_ "GenSigEVName" SG_ 3221225472 TesterReqECM "TesterReqECM";
BA_ "GenSigSendType" SG_ 3221225472 TesterReqECM 3;
BA_ "SigType" SG_ 3221225472 BremsomatSetSpeed 1;
BA_ "SPN" SG_ 3221225472 BremsomatSetSpeed 86;
BA_ "SigType" SG_ 3221225472 BremsomatControlPriority 4;
BA_ "SPN" SG_ 3221225472 BremsomatControlPriority 2970;
BA_ "SPN" SG_ 3221225472 TransGearShiftInhibitRq 681;
BA_ "SigType" SG_ 3221225472 TransGearShiftInhibitRq 4;
BA_ "SPN" SG_ 3221225472 Aftertreatment1OutletNOx 3226;
BA_ "SigType" SG_ 3221225472 Aftertreatment1OutletNOx 1;
BA_ "GenSigStartValue" SG_ 2566848801 ATS_Notdefined 255;
BA_ "SigType" SG_ 2566848801 AntitheftRandomNumber 1;
BA_ "SPN" SG_ 2566848801 AntitheftRandomNumber 1198;
BA_ "SigType" SG_ 2566848801 AntitheftComponentStatusStates 4;
BA_ "SPN" SG_ 2566848801 AntitheftComponentStatusStates 1196;
BA_ "SigType" SG_ 2566848801 AntthftEncryptnSdPrsntIndicator 4;
BA_ "SPN" SG_ 2566848801 AntthftEncryptnSdPrsntIndicator 1194;
BA_ "SigType" SG_ 2566848801 AntitheftModifyPwdStates 4;
BA_ "SPN" SG_ 2566848801 AntitheftModifyPwdStates 1197;
BA_ "SigType" SG_ 2566848801 AntitheftPwdValidIndicator 4;
BA_ "SPN" SG_ 2566848801 AntitheftPwdValidIndicator 1195;
BA_ "SPN" SG_ 2566849564 AntthftEncryptonIndicatorStates 1199;
BA_ "SigType" SG_ 2566849564 AntthftEncryptonIndicatorStates 4;
BA_ "SPN" SG_ 2566849564 AntitheftDesiredExitModeStates 1200;
BA_ "SigType" SG_ 2566849564 AntitheftDesiredExitModeStates 4;
BA_ "SPN" SG_ 2566849564 AntitheftCmdStates 1201;
BA_ "SPN" SG_ 2566849564 AntitheftPasswordRepresentation 1202;
BA_ "SigType" SG_ 2566849564 AntitheftPasswordRepresentation 1;
BA_ "GenSigStartValue" SG_ 2566848545 HeaterStatus 30;
BA_ "GenSigStartValue" SG_ 2566782999 HeaterTimer2Status_Temp 30;
BA_ "GenSigStartValue" SG_ 2566782999 HeaterTimer2Status_Day 1;
BA_ "GenSigStartValue" SG_ 2566782999 HeaterTimer3Status_Temp 30;
BA_ "GenSigStartValue" SG_ 2566782999 HeaterTimer3Status_Day 1;
BA_ "GenSigStartValue" SG_ 2566849052 HeaterReq 30;
BA_ "GenSigStartValue" SG_ 2566848535 HeaterTimer1Status_Temp 30;
BA_ "GenSigStartValue" SG_ 2566848535 HeaterTimer1Status_Day 1;
BA_ "SPN" SG_ 2566834694 FlashRedStopLamp 3039;
BA_ "SigType" SG_ 2566834694 FlashRedStopLamp 4;
BA_ "SPN" SG_ 2566834694 FlashProtectLamp 3041;
BA_ "SigType" SG_ 2566834694 FlashProtectLamp 4;
BA_ "SPN" SG_ 2566834694 FlashMalfuncIndicatorLamp 3038;
BA_ "SigType" SG_ 2566834694 FlashMalfuncIndicatorLamp 4;
BA_ "SPN" SG_ 2566834694 FlashAmberWarningLamp 3040;
BA_ "SigType" SG_ 2566834694 FlashAmberWarningLamp 4;
BA_ "SPN" SG_ 2566834694 MalfunctionIndicatorLampStatus 1213;
BA_ "SigType" SG_ 2566834694 MalfunctionIndicatorLampStatus 4;
BA_ "SPN" SG_ 2566834694 AmberWarningLampStatus 624;
BA_ "SigType" SG_ 2566834694 AmberWarningLampStatus 4;
BA_ "SPN" SG_ 2566834694 RedStopLampState 623;
BA_ "SigType" SG_ 2566834694 RedStopLampState 4;
BA_ "SPN" SG_ 2566834694 ProtectLampStatus 987;
BA_ "SigType" SG_ 2566834694 ProtectLampStatus 4;
BA_ "SPN" SG_ 2566834693 FlashRedStopLamp 3039;
BA_ "SigType" SG_ 2566834693 FlashRedStopLamp 4;
BA_ "SPN" SG_ 2566834693 FlashProtectLamp 3041;
BA_ "SigType" SG_ 2566834693 FlashProtectLamp 4;
BA_ "SPN" SG_ 2566834693 FlashMalfuncIndicatorLamp 3038;
BA_ "SigType" SG_ 2566834693 FlashMalfuncIndicatorLamp 4;
BA_ "SPN" SG_ 2566834693 FlashAmberWarningLamp 3040;
BA_ "SigType" SG_ 2566834693 FlashAmberWarningLamp 4;
BA_ "SPN" SG_ 2566834693 MalfunctionIndicatorLampStatus 1213;
BA_ "SigType" SG_ 2566834693 MalfunctionIndicatorLampStatus 4;
BA_ "SPN" SG_ 2566834693 AmberWarningLampStatus 624;
BA_ "SigType" SG_ 2566834693 AmberWarningLampStatus 4;
BA_ "SPN" SG_ 2566834693 RedStopLampState 623;
BA_ "SigType" SG_ 2566834693 RedStopLampState 4;
BA_ "SPN" SG_ 2566834693 ProtectLampStatus 987;
BA_ "SigType" SG_ 2566834693 ProtectLampStatus 4;
BA_ "GenSigStartValue" SG_ 2566849057 Upred_Next_Crank 2550;
BA_ "GenSigStartValue" SG_ 2566849057 Battery_Temperature 295;
BA_ "GenSigStartValue" SG_ 2566849057 Centre_tap_difference 382;
BA_ "GenSigStartValue" SG_ 2566849057 Battery_SOH 510;
BA_ "SPN" SG_ 2565472256 ParameterGroupNumber 2574;
BA_ "SigType" SG_ 2565472256 ParameterGroupNumber 6;
BA_ "SPN" SG_ 2566835968 RedStopLampState_DM2 623;
BA_ "SigType" SG_ 2566835968 RedStopLampState_DM2 4;
BA_ "SPN" SG_ 2566835968 ProtectLampStatus_DM2 987;
BA_ "SigType" SG_ 2566835968 ProtectLampStatus_DM2 4;
BA_ "SPN" SG_ 2566835968 FlashRedStopLamp 3039;
BA_ "SigType" SG_ 2566835968 FlashRedStopLamp 4;
BA_ "SPN" SG_ 2566835968 FlashProtectLamp 3041;
BA_ "SigType" SG_ 2566835968 FlashProtectLamp 4;
BA_ "SPN" SG_ 2566835968 FlashMalfuncIndicatorLamp 3038;
BA_ "SigType" SG_ 2566835968 FlashMalfuncIndicatorLamp 4;
BA_ "SPN" SG_ 2566835968 FlashAmberWarningLamp 3040;
BA_ "SigType" SG_ 2566835968 FlashAmberWarningLamp 4;
BA_ "SPN" SG_ 2566834944 RedStopLampState_DM2 623;
BA_ "SigType" SG_ 2566834944 RedStopLampState_DM2 4;
BA_ "SPN" SG_ 2566834944 ProtectLampStatus_DM2 987;
BA_ "SigType" SG_ 2566834944 ProtectLampStatus_DM2 4;
BA_ "SPN" SG_ 2566834944 FlashRedStopLamp 3039;
BA_ "SigType" SG_ 2566834944 FlashRedStopLamp 4;
BA_ "SPN" SG_ 2566834944 FlashProtectLamp 3041;
BA_ "SigType" SG_ 2566834944 FlashProtectLamp 4;
BA_ "SPN" SG_ 2566834944 FlashMalfuncIndicatorLamp 3038;
BA_ "SigType" SG_ 2566834944 FlashMalfuncIndicatorLamp 4;
BA_ "SPN" SG_ 2566834944 FlashAmberWarningLamp 3040;
BA_ "SigType" SG_ 2566834944 FlashAmberWarningLamp 4;
BA_ "SPN" SG_ 2348814341 MessageCounter 4206;
BA_ "GenSigStartValue" SG_ 2348814341 MessageCounter 15;
BA_ "SPN" SG_ 2348814341 EngRqedTorque_TorqueLimit 518;
BA_ "SigType" SG_ 2348814341 EngRqedTorque_TorqueLimit 1;
BA_ "GenSigStartValue" SG_ 2348814341 EngRqedTorque_TorqueLimit 250;
BA_ "SPN" SG_ 2348814341 OverrideCtrlModePriority 897;
BA_ "GenSigStartValue" SG_ 2348814341 OverrideCtrlModePriority 3;
BA_ "SPN" SG_ 2348814341 EngOverrideCtrlMode 695;
BA_ "SPN" SG_ 2348814341 MessageChecksum 4207;
BA_ "GenSigStartValue" SG_ 2348814341 MessageChecksum 15;
BA_ "SPN" SG_ 2632711987 SequenceNumber 2572;
BA_ "SPN" SG_ 2632777523 PGNumber 2560;
BA_ "SigType" SG_ 2632777523 PGNumber 6;
BA_ "SPN" SG_ 2632777523 TotalNumberOfPackets 2558;
BA_ "SPN" SG_ 2632777523 TotalMessageSize 2557;
BA_ "SPN" SG_ 2632777523 ControlByte 2556;
BA_ "SPN" SG_ 2633935619 RecommendedGear 1113;
BA_ "SigType" SG_ 2633935619 RecommendedGear 1;
BA_ "SPN" SG_ 2565603075 SequenceNumber 2572;
BA_ "SPN" SG_ 2565668611 TotalNumberOfPacketsBAM 2558;
BA_ "SPN" SG_ 2565668611 PGNofRequstedInformation 2552;
BA_ "SigType" SG_ 2565668611 PGNofRequstedInformation 6;
BA_ "SPN" SG_ 2565668611 TotalMessageSizeBAM 2557;
BA_ "SPN" SG_ 2565603088 SequenceNumber 2572;
BA_ "SPN" SG_ 2565668624 TotalNumberOfPacketsBAM 2558;
BA_ "SPN" SG_ 2565668624 PGNofRequstedInformation 2552;
BA_ "SigType" SG_ 2565668624 PGNofRequstedInformation 6;
BA_ "SPN" SG_ 2565668624 TotalMessageSizeBAM 2557;
BA_ "SPN" SG_ 2565603087 SequenceNumber 2572;
BA_ "SPN" SG_ 2565668623 TotalNumberOfPacketsBAM 2558;
BA_ "SPN" SG_ 2565668623 PGNofRequstedInformation 2552;
BA_ "SigType" SG_ 2565668623 PGNofRequstedInformation 6;
BA_ "SPN" SG_ 2565668623 TotalMessageSizeBAM 2557;
BA_ "SPN" SG_ 2565603072 SequenceNumber 2572;
BA_ "SPN" SG_ 2565668608 TotalNumberOfPacketsBAM 2558;
BA_ "SPN" SG_ 2565668608 PGNofRequstedInformation 2552;
BA_ "SigType" SG_ 2565668608 PGNofRequstedInformation 6;
BA_ "SPN" SG_ 2565668608 TotalMessageSizeBAM 2557;
BA_ "SPN" SG_ 2565406464 GroupFunctionValue 2542;
BA_ "SigType" SG_ 2565406464 GroupFunctionValue 1;
BA_ "SPN" SG_ 2565406464 ControlByte 2541;
BA_ "SPN" SG_ 2632777519 TotalNumberOfPacketsBAM 2558;
BA_ "SPN" SG_ 2632777519 PGNofRequstedInformation 2552;
BA_ "SigType" SG_ 2632777519 PGNofRequstedInformation 6;
BA_ "SPN" SG_ 2632777519 TotalMessageSizeBAM 2557;
BA_ "SPN" SG_ 2173632254 TotalNumberOfPacketsBAM 2558;
BA_ "SPN" SG_ 2173632254 PGNofRequstedInformation 2552;
BA_ "SigType" SG_ 2173632254 PGNofRequstedInformation 6;
BA_ "SPN" SG_ 2173632254 TotalMessageSizeBAM 2557;
BA_ "SPN" SG_ 2565603310 SequenceNumber 2572;
BA_ "SPN" SG_ 2565668846 TotalNumberOfPacketsBAM 2558;
BA_ "SPN" SG_ 2565668846 PGNofRequstedInformation 2552;
BA_ "SigType" SG_ 2565668846 PGNofRequstedInformation 6;
BA_ "SPN" SG_ 2565668846 TotalMessageSizeBAM 2557;
BA_ "SPN" SG_ 2565603095 SequenceNumber 2572;
BA_ "SPN" SG_ 2565668631 TotalNumberOfPacketsBAM 2558;
BA_ "SPN" SG_ 2565668631 PGNofRequstedInformation 2552;
BA_ "SigType" SG_ 2565668631 PGNofRequstedInformation 6;
BA_ "SPN" SG_ 2565668631 TotalMessageSizeBAM 2557;
BA_ "SPN" SG_ 2565603105 SequenceNumber 2572;
BA_ "SPN" SG_ 2565668641 TotalNumberOfPacketsEoMA 2558;
BA_ "SPN" SG_ 2565668641 TotalMessageSizeEoMA 2557;
BA_ "SPN" SG_ 2565668641 TotalMessageSizeBAM 2557;
BA_ "SPN" SG_ 2565668641 TotalNumberOfPacketsBAM 2558;
BA_ "SPN" SG_ 2565668641 ConnectionAbortReason 2570;
BA_ "SPN" SG_ 2565668641 NextPacketNumberToBeSent 2562;
BA_ "SPN" SG_ 2565668641 NumberOfPacketsThatCanBeSent 2561;
BA_ "SPN" SG_ 2565668641 PGNumber 2560;
BA_ "SigType" SG_ 2565668641 PGNumber 6;
BA_ "SPN" SG_ 2565668641 MaximumNumberOfPackets 2559;
BA_ "SPN" SG_ 2565668641 TotalNumberOfPackets 2558;
BA_ "SPN" SG_ 2565668641 TotalMessageSize 2557;
BA_ "SPN" SG_ 2565668641 ControlByte 2556;
BA_ "SPN" SG_ 2565537768 ParameterGroupNumber 2574;
BA_ "SigType" SG_ 2565537768 ParameterGroupNumber 6;
BA_ "SPN" SG_ 2565537578 ParameterGroupNumber 2574;
BA_ "SigType" SG_ 2565537578 ParameterGroupNumber 6;
BA_ "SPN" SG_ 2566844711 CruiseControlsetspeed 86;
BA_ "SigType" SG_ 2566844711 CruiseControlsetspeed 1;
BA_ "SPN" SG_ 2566844711 CruiseControlenableswitch 596;
BA_ "SigType" SG_ 2566844711 CruiseControlenableswitch 4;
BA_ "SigType" SG_ 2566844711 Wheelbasedvehiclespeed_CCVS_B27 1;
BA_ "SPN" SG_ 2566844711 Wheelbasedvehiclespeed_CCVS_B27 84;
BA_ "SPN" SG_ 2566834721 DM1_FlashRedStopLamp 3039;
BA_ "SigType" SG_ 2566834721 DM1_FlashRedStopLamp 4;
BA_ "SPN" SG_ 2566834721 DM1_FlashProtectLamp 3041;
BA_ "SigType" SG_ 2566834721 DM1_FlashProtectLamp 4;
BA_ "SPN" SG_ 2566834721 DM1_FlashMalfuncIndicatorLamp 3038;
BA_ "SigType" SG_ 2566834721 DM1_FlashMalfuncIndicatorLamp 4;
BA_ "SPN" SG_ 2566834721 DM1_FlashAmberWarningLamp 3040;
BA_ "SigType" SG_ 2566834721 DM1_FlashAmberWarningLamp 4;
BA_ "SPN" SG_ 2566834721 DM1_MalfunctionIndicatorLampSt 1213;
BA_ "SigType" SG_ 2566834721 DM1_MalfunctionIndicatorLampSt 4;
BA_ "SPN" SG_ 2566834721 DM1_AmberWarningLampStatus 624;
BA_ "SigType" SG_ 2566834721 DM1_AmberWarningLampStatus 4;
BA_ "SPN" SG_ 2566834721 DM1_RedStopLampState 623;
BA_ "SigType" SG_ 2566834721 DM1_RedStopLampState 4;
BA_ "SPN" SG_ 2566834721 DM1_ProtectLampStatus 987;
BA_ "SigType" SG_ 2566834721 DM1_ProtectLampStatus 4;
BA_ "SPN" SG_ 2348876549 MessageCounter 4206;
BA_ "SPN" SG_ 2348876549 MessageChecksum 4207;
BA_ "SPN" SG_ 2348876549 RollingModeRMFS 1855;
BA_ "SPN" SG_ 2348876549 PowerModeRMFS 1852;
BA_ "SPN" SG_ 2566834736 AmberWarningLampStatus 624;
BA_ "SigType" SG_ 2566834736 AmberWarningLampStatus 4;
BA_ "SPN" SG_ 2566775343 AirSuspensionSupplyPress 1090;
BA_ "SigType" SG_ 2566775343 AirSuspensionSupplyPress 1;
BA_ "SigType" SG_ 2566775343 AuxEquipSupplyPressure 1;
BA_ "SPN" SG_ 2566775343 ServiceBrakeAirPressRqCircuit2 2606;
BA_ "SigType" SG_ 2566775343 ServiceBrakeAirPressRqCircuit2 1;
BA_ "SPN" SG_ 2566775343 ServiceBrakeAirPressRqCircuit1 2605;
BA_ "SigType" SG_ 2566775343 ServiceBrakeAirPressRqCircuit1 1;
BA_ "GenSigSendType" SG_ 2566810903 EngOff_T_Actl_IC 3;
BA_ "GenSigStartValue" SG_ 2566810903 AuxHeaterOutputCoolantTemp 40;
BA_ "GenSigStartValue" SG_ 2566810903 CabInteriorTempCommand 80;
BA_ "SPN" SG_ 2566834691 FlashRedStopLamp 3039;
BA_ "SigType" SG_ 2566834691 FlashRedStopLamp 4;
BA_ "SPN" SG_ 2566834691 FlashProtectLamp 3041;
BA_ "SigType" SG_ 2566834691 FlashProtectLamp 4;
BA_ "SPN" SG_ 2566834691 FlashMalfuncIndicatorLamp 3038;
BA_ "SigType" SG_ 2566834691 FlashMalfuncIndicatorLamp 4;
BA_ "SPN" SG_ 2566834691 FlashAmberWarningLamp 3040;
BA_ "SigType" SG_ 2566834691 FlashAmberWarningLamp 4;
BA_ "SPN" SG_ 2566834691 MalfunctionIndicatorLampStatus 1213;
BA_ "SigType" SG_ 2566834691 MalfunctionIndicatorLampStatus 4;
BA_ "SPN" SG_ 2566834691 AmberWarningLampStatus 624;
BA_ "SigType" SG_ 2566834691 AmberWarningLampStatus 4;
BA_ "SPN" SG_ 2566834691 RedStopLampState 623;
BA_ "SigType" SG_ 2566834691 RedStopLampState 4;
BA_ "SPN" SG_ 2566834691 ProtectLampStatus 987;
BA_ "SigType" SG_ 2566834691 ProtectLampStatus 4;
BA_ "SPN" SG_ 2566834739 FlashRedStopLamp 3039;
BA_ "SigType" SG_ 2566834739 FlashRedStopLamp 4;
BA_ "SPN" SG_ 2566834739 FlashProtectLamp 3041;
BA_ "SigType" SG_ 2566834739 FlashProtectLamp 4;
BA_ "SPN" SG_ 2566834739 FlashMalfuncIndicatorLamp 3038;
BA_ "SigType" SG_ 2566834739 FlashMalfuncIndicatorLamp 4;
BA_ "SPN" SG_ 2566834739 FlashAmberWarningLamp 3040;
BA_ "SigType" SG_ 2566834739 FlashAmberWarningLamp 4;
BA_ "SPN" SG_ 2566834739 MalfunctionIndicatorLampStatus 1213;
BA_ "SigType" SG_ 2566834739 MalfunctionIndicatorLampStatus 4;
BA_ "SPN" SG_ 2566834739 AmberWarningLampStatus 624;
BA_ "SigType" SG_ 2566834739 AmberWarningLampStatus 4;
BA_ "SPN" SG_ 2566834739 RedStopLampState 623;
BA_ "SigType" SG_ 2566834739 RedStopLampState 4;
BA_ "SPN" SG_ 2566834739 ProtectLampStatus 987;
BA_ "SigType" SG_ 2566834739 ProtectLampStatus 4;
BA_ "SigType" SG_ 2566834739 DTC5 7;
BA_ "SigType" SG_ 2566834739 DTC4 7;
BA_ "SigType" SG_ 2566834739 DTC3 7;
BA_ "SigType" SG_ 2566834739 DTC2 7;
BA_ "SigType" SG_ 2566834739 DTC1 7;
BA_ "GenSigStartValue" SG_ 2566907443 TPMSTyreTemp 40;
VAL_ 3221225472 ACCSetDistanceMode 7 "Not available" 6 "Error condition" 5 "Conventional Cruise Control Mode" 4 "ACC Distance Mode 5- Shortest" 3 "ACC Distance Mode 4" 2 "ACC Distance Mode 3" 1 "ACC Distance Mode 2" 0 "ACC Distance Mode 1- Longest" ;
VAL_ 3221225472 ACCMode 3 "Dont Care" 2 "Reserved" 1 "Cruise Control Not Allowed" 0 "Cruise Control Allowed" ;
VAL_ 3221225472 TirePressThresholdDetection 7 "NotAvailable" 6 "ErrorIndicator" 5 "NotDefined" 4 "ExtrmUndrPrssTrPrssrIsAtALvlWhr" 3 "UndrPrssTrPrssrIsLwrThnThPrssrD" 2 "NWrnngPrssTrPrssrIsWthnThThrshl" 1 "OvrPrssTrPrssrIsHghrThnThPrssrD" 0 "ExtrmOvrPrssTrPrssrIsAtALvlWhrT" ;
VAL_ 3221225472 CTIWheelEndElectricalFault 3 "NotSupported" 2 "Error" 1 "NotDefined" 0 "Ok" ;
VAL_ 3221225472 CTITireStatus 3 "NotSupported" 2 "Error" 1 "TireLeakDetected" 0 "Ok" ;
VAL_ 3221225472 CTIWheelSensorStatus 3 "NotSupported" 2 "NotDefined" 1 "On" 0 "Off_IsolatedFromCTIPressCtrl" ;
VAL_ 3221225472 AntitheftComponentStatusStates 3 "NotDefined" 2 "BlckdThsSttIndctsThtALckUnlckCm" 1 "LckdThsSttIndctsThtCmpnntCnNOTB" 0 "UnlckdThsSttIndctsThtCmpnntCnBS" ;
VAL_ 3221225472 AntthftEncryptnSdPrsntIndicator 3 "NotAvailable" 2 "Error" 1 "RandomNumberIsPresent" 0 "RandomNumberIsNotPresent" ;
VAL_ 3221225472 AntitheftModifyPwdStates 3 "Notvalid" 2 "EmptyOfPwdsThsSttIndctsThtCmpnn" 1 "FullofPwds" 0 "OkThsSttIndctsThtRqWsSccssfllyP" ;
VAL_ 3221225472 AntitheftPwdValidIndicator 3 "NotAvailable" 2 "Error" 1 "PwdIsAValidatedPassword" 0 "PwdIsNotAValidatedPassword" ;
VAL_ 3221225472 EngBuildHoursReset 2 "Reserved" 3 "TakeNoAction" 1 "Reset" 0 "DoNotReset" ;
VAL_ 3221225472 SteerStraightAheadPosReset 3 "NotApplicable" 2 "ReservedTakeNoAction" 1 "Reset" 0 "TakeNoActionDoNotReset" ;
VAL_ 3221225472 TrnsShftSlctorDisplayModeSwitch 3 "NotAvailable" 2 "Error" 1 "On" 0 "Off" ;
VAL_ 3221225472 TransMode4 3 "TakeNoAction" 2 "Reserved" 1 "Enable" 0 "Disable" ;
VAL_ 3221225472 TransMode3 3 "TakeNoAction" 2 "Reserved" 1 "Enable" 0 "Disable" ;
VAL_ 3221225472 TransMode2 3 "TakeNoAction" 2 "Reserved" 1 "Enable" 0 "Disable" ;
VAL_ 3221225472 DisengageDiffLockRqCentralRear 3 "TakeNoAction" 2 "Reserved" 1 "DisengageDiffLock" 0 "EngageDiffLock" ;
VAL_ 3221225472 DisengageDiffLockRqCentralFront 3 "TakeNoAction" 2 "Reserved" 1 "DisengageDiffLock" 0 "EngageDiffLock" ;
VAL_ 3221225472 DisengageDiffLockRqCentral 3 "TakeNoAction" 2 "Reserved" 1 "DisengageDiffLock" 0 "EngageDiffLock" ;
VAL_ 3221225472 DisengageDiffLockRqRearAxle2 3 "TakeNoAction" 2 "Reserved" 1 "DisengageDiffLock" 0 "EngageDiffLock" ;
VAL_ 3221225472 DisengageDiffLockRqRearAxle1 3 "TakeNoAction" 2 "Reserved" 1 "DisengageDiffLock" 0 "EngageDiffLock" ;
VAL_ 3221225472 DisengageDiffLockRqFrontAxle2 3 "TakeNoAction" 2 "Reserved" 1 "DisengageDiffLock" 0 "EngageDiffLock" ;
VAL_ 3221225472 DisengageDiffLockRqFrontAxle1 3 "TakeNoAction" 2 "Reserved" 1 "DisengageDiffLock" 0 "EngageDiffLock" ;
VAL_ 3221225472 TransRqedGear 60 "Reserved" 61 "Reserved" 222 "NeutralSelectorPos" 223 "ReverseSelectorPos" 224 "PsUnknownAnd_OrNoButtonsPressed" 225 "PrssOfMmntryBttnTRslctCrrentPos" 226 "BtwnRvrsAndPrkShiftSelectorPoss" 227 "BtwnNtrlAndRvrsShftSelectorPoss" 228 "BtwnDrvAndNtrlShiftSelectorPoss" 229 "BtwnD1AndDriveShiftSelectorPoss" 230 "BetweenD2AndD1ShiftSelectorPoss" 231 "BetweenD3AndD2ShiftSelectorPoss" 232 "BetweenD4AndD3ShiftSelectorPoss" 233 "BetweenD5AndD4ShiftSelectorPoss" 234 "BetweenD6AndD5ShiftSelectorPoss" 235 "BetweenD7AndD6ShiftSelectorPoss" 236 "BtwnTwoForwardShiftSelectorPoss" 237 "BtwnTwoReverseShiftSelectorPoss" 238 "BetweenTwoShiftSelectorPoss" 239 "D77thFrwrdSlctrPsRfrncdFrmDrive" 240 "D66thFrwrdSlctrPsRfrncdFrmDrive" 241 "D55thFrwrdSlctrPsRfrncdFrmDrive" 242 "D44thFrwrdSlctrPsRfrncdFrmDrive" 243 "D33rdFrwrdSlctrPsRfrncdFrmDrive" 244 "D22ndFrwrdSlctrPsRfrncdFrmDrive" 245 "D11stFrwrdSlctrPsRfrncdFrmDrive" 246 "Downshift2GearsFromCurrentPos" 247 "Downshift1GearFromCurrentPos" 248 "Upshift2GearsFromCurrentPos" 249 "Upshift1GearFromCurrentPos" 250 "ForwardLowPos" 251 "ParkPos" 252 "ForwardDrivePos" 253 "HoldCurrentGear" ;
VAL_ 3221225472 DisengageDrivelineRq 2 "Reserved" 3 "TakeNoAction" 1 "DisengageDriveline" 0 "AllowDrivelineEngagement" ;
VAL_ 3221225472 TrnsTrqConverterLockupDisableRq 3 "TakeNoAction" 2 "Reserved" 1 "DisableTorqueConverterLockup" 0 "AllowTorqueConverterLockup" ;
VAL_ 3221225472 TransRqedLaunchGear 15 "NotAvailable" 14 "Error" 13 "Reserved" 12 "LaunchVehicleInReverse4" 11 "LaunchVehicleInReverse3" 10 "LaunchVehicleInReverse2" 9 "LaunchVehicleInReverse1" 8 "LaunchVehicleIn8thGear" 7 "LaunchVehicleIn7thGear" 6 "LaunchVehicleIn6thGear" 5 "LaunchVehicleIn5thGear" 4 "LaunchVehicleIn4thGear" 3 "LaunchVehicleIn3rdGear" 2 "LaunchVehicleIn2ndGear" 1 "LaunchVehicleIn1stGear" 0 "NSpcfcLnchGrRqdUsDfltLaunchGear" ;
VAL_ 3221225472 TransReverseGearShiftInhibitRq 3 "TakeNoAction" 2 "Reserved" 1 "InhbtShftsIntRvrsGrAndShftTrnsT" 0 "AllowShiftsIntoReverseGear" ;
VAL_ 3221225472 TransMode8 3 "TakeNoAction" 2 "Reserved" 1 "Enable" 0 "Disable" ;
VAL_ 3221225472 TransMode7 3 "TakeNoAction" 2 "Reserved" 1 "Enable" 0 "Disable" ;
VAL_ 3221225472 TransMode6 3 "TakeNoAction" 2 "Reserved" 1 "Enable" 0 "Disable" ;
VAL_ 3221225472 TransMode5 3 "TakeNoAction" 2 "Reserved" 1 "Enable" 0 "Disable" ;
VAL_ 3221225472 MessageCounter 14 "Reserved" 13 "Reserved" 12 "Reserved" 11 "Reserved" 10 "Reserved" 9 "Reserved" 8 "Reserved" 15 "Not Available" ;
VAL_ 3221225472 ControlPurpose 5 "TemporaryPowerTrainControl" 4 "EngineProtection" 3 "RoadSpeedGovernor" 2 "PTOGovernor" 1 "CruiseControl" 0 "AcceleratorPedal" ;
VAL_ 3221225472 TransmissionRate 7 "UseStandardRate" 6 "25ms" 5 "50ms" 4 "100ms" 3 "250ms" 2 "500ms" 1 "750ms" 0 "1000ms" ;
VAL_ 3221225472 EngineRequestedTorqueHiRes 15 "Not Available" 14 "Not Available" 13 "Not Available" 12 "Not Available" 11 "Not Available" 10 "Not Available" 9 "Not Available" 8 "Not Available" ;
VAL_ 3221225472 PrkngBrkeActuatorFullyActivated 3 "NotAvailable" 2 "Error" 1 "PrkngBrkeActuatorFullyActivated" 0 "PrkngBrkActtorNotFullyActivated" ;
VAL_ 3221225472 DslPrtcltFltrActvRgnrtnFrcdStts 7 "notAvailable" 6 "ReservedForSAEAssignment" 2 "ActiveForcedByServiceTool" 1 "ActiveForcedBySwitch" 0 "NotActive" ;
VAL_ 3221225472 ExhaustSystemHighTempLampCmd 7 "notAvailable" 6 "reservedForSAEAssignment" 1 "OnSolid" 0 "Off" ;
VAL_ 3221225472 DslPrtcltFltrAtmtcActvRgnrtnIntt 3 "notAvailable" 2 "reservedForSAEAssignment" 1 "enabled" 0 "notEnabled" ;
VAL_ 3221225472 DslPrtcltFltrActvRgnrtnInhbtdDTV 3 "notAvailable" 2 "reservedForSAEAssignment" 1 "inhibited" 0 "notInhibited" ;
VAL_ 3221225472 DslPrtcltFltrActvRgnrtnInhbtdDTE 3 "notAvailable" 2 "reservedForSAEAssignment" 1 "inhibited" 0 "notInhibited" ;
VAL_ 3221225472 DslPrtcltFltrActvRgnrtnInhbtdDTP 3 "notAvailable" 2 "reservedForSAEAssignment" 1 "inhibited" 0 "notInhibited" ;
VAL_ 3221225472 DslPrtcltFltrActvRgnrtnInhbtdDTT 3 "notAvailable" 2 "reservedForSAEAssignment" 1 "inhibited" 0 "notInhibited" ;
VAL_ 3221225472 DslPrtcltFltrActvRgnrtnInhbtdDTS 3 "notAvailable" 2 "reservedForSAEAssignment" 1 "inhibited" 0 "notInhibited" ;
VAL_ 3221225472 DslPrtcltFltrActvRgnrtnInhb_0000 3 "notAvailable" 2 "reservedForSAEAssignment" 1 "inhibited" 0 "notInhibited" ;
VAL_ 3221225472 DslPrtcltFltrActvRgnrtnInhbtdDTL 3 "notAvailable" 2 "reservedForSAEAssignment" 1 "inhibited" 0 "notInhibited" ;
VAL_ 3221225472 DslPrtcltFltrActvRgnrtnInhb_0001 3 "notAvailable" 2 "reservedForSAEAssignment" 1 "inhibited" 0 "notInhibited" ;
VAL_ 3221225472 DslPrtcltFltrActvRgnrtnInhb_0002 3 "notAvailable" 2 "reservedForSAEAssignment" 1 "inhibited" 0 "notInhibited" ;
VAL_ 3221225472 DslPrtcltFltrActvRgnrtnInhbtdDTO 3 "notAvailable" 2 "reservedForSAEAssignment" 1 "inhibited" 0 "notInhibited" ;
VAL_ 3221225472 DslPrtcltFltrActvRgnrtnInhbtdDTA 3 "notAvailable" 2 "reservedForSAEAssignment" 1 "inhibited" 0 "notInhibited" ;
VAL_ 3221225472 DslPrtcltFltrActvRgnrtnInhb_0003 3 "notAvailable" 2 "reservedForSAEAssignment" 1 "inhibited" 0 "notInhibited" ;
VAL_ 3221225472 DslPrtcltFltrActvRgnrtnInhb_0004 3 "notAvailable" 2 "reservedForSAEAssignment" 1 "inhibited" 0 "notInhibited" ;
VAL_ 3221225472 DslPrtcltFltrActvRgnrtnInhbtdDTC 3 "notAvailable" 2 "reservedForSAEAssignment" 1 "inhibited" 0 "notInhibited" ;
VAL_ 3221225472 DslPrtcltFltrActvRgnrtnInhbtdDTI 3 "notAvailable" 2 "reservedForSAEAssignment" 1 "inhibited" 0 "notInhibited" ;
VAL_ 3221225472 DslPrtcltFltrActvRgnrtnInhbtdStt 3 "notAvailable" 2 "reservedForSAEAssignment" 1 "inhibited" 0 "notInhibited" ;
VAL_ 3221225472 DslPrtcltFltrActvRgnrtionStatus 3 "notAvailable" 2 "rgnrtnNddAtmtcllyInttdActvRgnrt" 1 "active" 0 "notActive" ;
VAL_ 3221225472 DslPrtcltFltrPssvRgnrtionStatus 3 "notAvailable" 2 "reservedForSAEAssignment" 1 "active" 0 "notActive" ;
VAL_ 3221225472 DieselParticulateFilterLampCmd 7 "notAvailable" 4 "OnFastBlink" 6 "reservedForSAEAssignment" 1 "OnSolid" 0 "Off" ;
VAL_ 3221225472 AftrtrtmntSCROprtrIndcmntSvrity 7 "NotAvailable_NotSupported" 6 "Reserved" 5 "InducementLevel5" 4 "InducementLevel4" 3 "InducementLevel3" 2 "InducementLevel2" 1 "InducementLevel1" 0 "NoInducementActive" ;
VAL_ 3221225472 Aftrtrtmnt1DEFTnkLwLvlIndicator 7 "notAvailable" 4 "OnFastBlink" 6 "reservedForSAEAssignment" 1 "OnSolid" 0 "Off" ;
VAL_ 3221225472 Aftrtrtmnt1SCRCatalystTankLevel 4 "Full" 0 "Empty" ;
VAL_ 3221225472 EngShutdownOverrideSwitch 3 "NotAvailable" 2 "Error" 1 "On" 0 "Off" ;
VAL_ 3221225472 EngTestModeSwitch 3 "NotAvailable" 2 "Error" 1 "On" 0 "Off" ;
VAL_ 3221225472 EngIdleDecrementSwitch 3 "NotAvailable" 2 "Error" 1 "On" 0 "Off" ;
VAL_ 3221225472 EngIdleIncrementSwitch 3 "NotAvailable" 2 "Error" 1 "On" 0 "Off" ;
VAL_ 3221225472 CruiseCtrlStates 7 "NotAvailable" 6 "AccelOverride" 5 "Set" 4 "Resume" 3 "Decelerate" 2 "Accelerate" 1 "Hold" 0 "Off_Disabled" ;
VAL_ 3221225472 Hand_Lever_Signals 31 "Position 4" 15 "Position 3" 7 "Position 2" 3 "Position 1" 1 "Position 0" ;
VAL_ 3221225472 AuxI_O08_GearboxNeutralPos 3 "NotAvailable" 2 "Error" 1 "SecuredNeutralPosition" 0 "NotInSecuredNeutralPosition" ;
VAL_ 3221225472 AuxI_O07_TrailerABSFulOper 3 "NotAvailable" 2 "Error" 1 "TrailerABSFullyOperational" 0 "TrailerABSNotFullyOperational" ;
VAL_ 3221225472 AuxI_O06_TrailerABSDetected 3 "NotAvailable" 2 "Error" 1 "TrailerABSDetected" 0 "TrailerABSNotDetected" ;
VAL_ 3221225472 AuxI_O05_TrailerConnected 3 "NotAvailable" 1 "TrailerConnected" 0 "TrailerNotConnected" ;
VAL_ 3221225472 AuxI_O02_BlendingSwitchPos 3 "NotAvailable" 2 "Error" 1 "RetarderBlendingEnabled" 0 "RetarderBlendingDiasabled" ;
VAL_ 3221225472 TrailerBrakeStatus 3 "NotAvailable" 2 "ErrorCondition" 1 "Active" 0 "Inactive" ;
VAL_ 3221225472 AuxHeaterMode 15 "NotAvailable" 14 "Error" 4 "1101NotDefined" 3 "NormalMode" 2 "EconomyMode" 1 "OffDTADRPrErpnRgltnsFrTrnsprtOf" 0 "HeaterNotActive" ;
VAL_ 3221225472 AuxI_O03_RetarderLeverPos 7 "Not Available" 6 "Error" 3 "IntarderLeverPos on" 2 "IntarderLeverPos off" 1 "EngineBrakePos On" 0 "EngineBrakePos Off" ;
VAL_ 3221225472 ReverseGearState 252 "Forward Drive Position" 249 "Upshift 1 gear" 248 "Upshift 2 gears" 247 "Downshift 1 gear" 246 "Downshift 2 gears " 231 "Toggle btw Auto and Man" 228 "Forward Manv" 224 "No Command" 222 "Neutral Gear" 28 "Reverse Manv" 255 "Not Available" 254 "Error" 223 "Reverse Selector Position" ;
VAL_ 3221225472 AuxiliaryHeaterMode 15 "Not available" 14 "Error" 4 "Dry & wet type heater active" 3 "Dry type heater active" 2 "Wet type heater active" 1 "Off due to ADR" 0 "Heater not active" ;
VAL_ 3221225472 GearShiftPriority 21 "NotAvailable" 20 "Error" 6 "No command" 1 "Driver1st,ECM 2nd" 0 "Driver2nd,ECM 1st" ;
VAL_ 3221225472 FlashRedStopLamp 3 "Unavailable / Do Not Flash" 2 "Reserved" 1 "Fast Flash" 0 "Slow Flash" ;
VAL_ 3221225472 FlashProtectLamp 3 "Unavailable / Do Not Flash" 2 "Reserved" 1 "Fast Flash" 0 "Slow Flash" ;
VAL_ 3221225472 FlashMalfuncIndicatorLamp 3 "Unavailable / Do Not Flash" 2 "Reserved" 1 "Fast Flash" 0 "Slow Flash" ;
VAL_ 3221225472 FlashAmberWarningLamp 3 "Unavailable / Do Not Flash" 2 "Reserved" 1 "Fast Flash" 0 "Slow Flash" ;
VAL_ 3221225472 MalfunctionIndicatorLampStatus 3 "Not available" 2 "Reserved" 1 "Lamp on" 0 "Lamp off" ;
VAL_ 3221225472 AmberWarningLampStatus 3 "Not available" 2 "Reserved" 1 "Lamp on" 0 "Lamp off" ;
VAL_ 3221225472 ProtectLampStatus 3 "Not available" 2 "Reserved" 1 "Lamp on" 0 "Lamp off" ;
VAL_ 3221225472 SCRThermalManagementActive 3 "DontCare" 2 "Reserved" 1 "SCRThermalManagementIsActive" 0 "SCRThermalManagementIsNotActive" ;
VAL_ 3221225472 MmntryEngMaxPowerEnableFeedback 3 "dontCare" 2 "reserved" 1 "supported" 0 "disabled" ;
VAL_ 3221225472 DPFThermalManagementActive 3 "DontCare" 2 "Reserved" 1 "DPFThermalManagementIsActive" 0 "DPFThermalManagementIsNotActive" ;
VAL_ 3221225472 TwoSpeedAxleSwitch 3 "NotAvailable" 2 "Error" 1 "HighSpeedRange" 0 "LowSpeedRange" ;
VAL_ 3221225472 OTAUpdateRequest2 3 "Not available" 2 "Error" 1 "Request update" 0 "Default - No  request" ;
VAL_ 3221225472 ACC_Inhibit_CCVS 3 "Not Available" 2 "Error Indicator" 1 "ACC inhibited" 0 "ACC not inhibited" ;
VAL_ 3221225472 EngTorqueMode 15 "Not available" 11 "Remote accelerator" 10 "Braking system" 9 "High speed governor" 8 "Torque limiting" 7 "ABS control" 6 "Transmission control" 5 "ASR control" 4 "Road speed governor" 3 "PTO governor" 2 "Cruise control" 1 "Accelerator pedal/operator selec" 0 "Low idle governor/no request (de" ;
VAL_ 3221225472 AMTMode 3 "Take no action" 2 "Reserve" 1 "Enabled" 0 "Disabled" ;
VAL_ 3221225472 AMTMode_BCM 3 "Take no action" 2 "Reserve" 1 "Enabled" 0 "Disabled" ;
VAL_ 3221225472 RedStopLampState 3 "Not available" 2 "Reserved" 1 "Lamp on" 0 "Lamp off" ;
VAL_ 3221225472 ParkingBrakeSwitch_BCM 3 "NotAvailable" 2 "Error" 1 "ParkingBrakeSet" 0 "ParkingBrakeNotSet" ;
VAL_ 3221225472 ParkBrakeReleaseInhibitRq 3 "Unavailable" 2 "SAEReserved" 1 "ParkBrakeReleaseInhibitRqed" 0 "ParkBrakeReleaseInhibitNotRqed" ;
VAL_ 3221225472 CruiseCtrlPauseSwitch 3 "TakeNoAction" 2 "ErrorIndicator" 1 "On" 0 "Off" ;
VAL_ 3221225472 BremsomatConfiguration 7 "Not available" 6 "Reserved" 5 "Bremsomat Set Speed" 4 "Permanent Signal" 3 "Two buttons" 2 "One button" 1 "Bremsomat on pos 1 of hand lever" 0 "No Bremsomat" ;
VAL_ 3221225472 PGNumber 255 "NotAvailable" ;
VAL_ 3221225472 ControlByte 24 "EAbort" 23 "EEoMACK" 22 "EDPO" 21 "ECTS" 20 "ERTS" 255 "Abort" 32 "BAM" 19 "EoMA" 17 "CTS" 16 "RTS" ;
VAL_ 3221225472 OccuranceCount 127 "Not Available" 0 "Valid Values" ;
VAL_ 3221225472 FMI 31 "Not Available" 12 "No Signal" 4 "Source Low" 3 "Source High" 2 "Not Plausible" 1 "Below Normal" 0 "Above Normal" ;
VAL_ 3221225472 Memory2HeightRequest 1 "Active" 0 "Deactive" ;
VAL_ 3221225472 Memory2LevelSave 1 "Active" 0 "Deactive" ;
VAL_ 3221225472 Memory1LevelSave 1 "Active" 0 "Deactive" ;
VAL_ 3221225472 Memory1HeightRequest 1 "Active" 0 "Deactive" ;
VAL_ 3221225472 StopButtonPressed 1 "Active" 0 "Deactive" ;
VAL_ 3221225472 RideHeightRequest_RCU 1 "Active" 0 "Deactive" ;
VAL_ 3221225472 BremsomatControlPriority 21 "NotAvailable" 20 "Error" 6 "No command" 1 "Driver1st,ECM 2nd" 0 "Driver2nd,ECM 1st" ;
VAL_ 3221225472 TransGearShiftInhibitRq 2 "Reserved" 3 "TakeNoAction" 1 "GearShiftsAreInhibited" 0 "GearShiftsAreAllowed" ;
VAL_ 3221225472 UserLocationSelection 2 "Location On" 1 "Location Off" 0 "No Command" ;
VAL_ 2566848801 AntitheftComponentStatusStates 3 "NotDefined" 2 "BlckdThsSttIndctsThtALckUnlckCm" 1 "LckdThsSttIndctsThtCmpnntCnNOTB" 0 "UnlckdThsSttIndctsThtCmpnntCnBS" ;
VAL_ 2566848801 AntthftEncryptnSdPrsntIndicator 3 "NotAvailable" 2 "Error" 1 "RandomNumberIsPresent" 0 "RandomNumberIsNotPresent" ;
VAL_ 2566848801 AntitheftModifyPwdStates 3 "Notvalid" 2 "EmptyOfPwdsThsSttIndctsThtCmpnn" 1 "FullofPwds" 0 "OkThsSttIndctsThtRqWsSccssfllyP" ;
VAL_ 2566848801 AntitheftPwdValidIndicator 3 "NotAvailable" 2 "Error" 1 "PwdIsAValidatedPassword" 0 "PwdIsNotAValidatedPassword" ;
VAL_ 2566849564 AntthftEncryptonIndicatorStates 3 "NtAvlblThsSttIsUsdTIndctThtARnd" 2 "NotDefined" 1 "EncryptdCdPrsntThsSttIsUsdTIndc" 0 "EncryptnSdRqThsSttRprsntsARqstT" ;
VAL_ 2566849564 AntitheftDesiredExitModeStates 3 "NtAvlblThsSttIsIndctsThtOptnIsN" 2 "NotDefined" 1 "LckWhnKyffThsSttIsUsdTIndctThtC" 0 "LckUpnOprtrRqThsSttIsUsdTIndctT" ;
VAL_ 2566849564 AntitheftCmdStates 6 "111NotDefined" 5 "Login" 4 "ChckSttsThsSttRprsntsARqTChckTS" 3 "LockorUnlock" 2 "ChngPwdThsSttRprsntsARqTCmpnntT" 1 "DeletePwd" 0 "AddPwdThsSttRprsntsARqTCmpnntTA" ;
VAL_ 2566848545 PassWinPosStatus 7 "NA" 6 "NA" 5 "NA" 4 "Error" 3 "Not Calibrated" 2 "Open" 1 "Inprogress" 0 "Closed" ;
VAL_ 2566848545 DriverWinPosStatus 7 "NA" 6 "NA" 5 "NA" 4 "Error" 3 "Not Calibrated" 2 "Open" 1 "Inprogress" 0 "Closed" ;
VAL_ 2566848545 GlobalLampStatus 3 "NA" 2 "Reserved" 1 "On" 0 "Off" ;
VAL_ 2566848545 ParkLampStatus 3 "NA" 2 "Reserved" 1 "On" 0 "Off" ;
VAL_ 2566848545 LowBeamStatus 3 "Error" 2 "Reserved" 1 "On" 0 "Off" ;
VAL_ 2566848545 RmtCntrl_HighBeamStatus 3 "NA" 2 "Reserved" 1 "On" 0 "Off" ;
VAL_ 2566848545 RearFogLampStatus 3 "NA" 2 "Reserved" 1 "On" 0 "Off" ;
VAL_ 2566848545 PTOStatus 3 "NA" 2 "Reserved" 1 "On" 0 "Off" ;
VAL_ 2566848545 ConnectionStatus 3 "NA" 2 "Reserved" 1 "Connected" 0 "Not Connected" ;
VAL_ 2566848545 FrontFogLampStatus 3 "NA" 2 "Reserved" 1 "Front Fog On" 0 "Front Fog Off" ;
VAL_ 2566848545 TurnSignStatus 7 "Error" 6 "Hazard Off" 5 "RightSignal Off" 4 "Left Signal Off" 3 "Hazard On" 2 "Left Signal On" 1 "Right Signal On" 0 "No Status" ;
VAL_ 2566848545 DoorLockStatus 3 "NA" 2 "Error" 1 "Door Status is Locked" 0 "Door Status is Unlocked" ;
VAL_ 2566848545 SunroofStatus 3 "In Progress" 2 "Error" 1 "Open" 0 "Close" ;
VAL_ 2566848545 BedAreaLampDimmSt 15 "Not Available" 14 "Error" 10 "10%" 9 "20%" 8 "30%" 7 "40%" 6 "50%" 5 "60%" 4 "70%" 3 "80%" 2 "90%" 1 "100%" 0 "Off" ;
VAL_ 2566848545 DomeLampDimmSt 15 "Not Available" 14 "Error" 10 "10%" 9 "20%" 8 "30%" 7 "40%" 6 "50%" 5 "60%" 4 "70%" 3 "80%" 2 "90%" 1 "100%" 0 "Off" ;
VAL_ 2566848545 MapReadDimmLeftSt 15 "Not Available" 14 "Error" 10 "10%" 9 "20%" 8 "30%" 7 "40%" 6 "50%" 5 "60%" 4 "70%" 3 "80%" 2 "90%" 1 "100%" 0 "Off" ;
VAL_ 2566848545 MapReadDimmRightSt 15 "Not Available" 14 "Error" 10 "10%" 9 "20%" 8 "30%" 7 "40%" 6 "50%" 5 "60%" 4 "70%" 3 "80%" 2 "90%" 1 "100%" 0 "Off" ;
VAL_ 2566848545 AmbientLightSt 3 "Not Available" 2 "Error" 1 "On" 0 "Off" ;
VAL_ 2566782999 HeaterTimer2Status_Recurrence 3 "NA" 2 "Error" 1 "Repetitive" 0 "One Time" ;
VAL_ 2566782999 HeaterTimer2Status_Day 10 "Everyday" 9 "Weekends" 8 "Weekdays" 7 "Sunday" 6 "Saturday" 5 "Friday" 4 "Thursday" 3 "Wednesday" 2 "Tuesday" 1 "Monday" ;
VAL_ 2566782999 HeaterTimer2Status 1 "Active" 0 "Not Active" ;
VAL_ 2566782999 HeaterTimer3Status_Recurrence 3 "NA" 2 "Error" 1 "Repetitive" 0 "One Time" ;
VAL_ 2566782999 HeaterTimer3Status_Day 10 "Everyday" 9 "Weekends" 8 "Weekdays" 7 "Sunday" 6 "Saturday" 5 "Friday" 4 "Thursday" 3 "Wednesday" 2 "Tuesday" 1 "Monday" ;
VAL_ 2566782999 HeaterTimer3Status 1 "Active" 0 "Not Active" ;
VAL_ 2566849052 WetFFHReq 3 "NA" 2 "DeActivate Heater" 1 "Activate Heater" 0 "NoRequest" ;
VAL_ 2566849052 DryFFHReq 3 "NA" 2 "DeActivate Heater" 1 "Activate Heater" 0 "NoRequest" ;
VAL_ 2566849052 CabTiltReq 3 "NA" 2 "Lower Cab" 1 "Raise Cab" 0 "NoRequest" ;
VAL_ 2566849052 PTOReq 3 "NA" 2 "PTO Off" 1 "PTO On" 0 "NoRequest" ;
VAL_ 2566849052 EngStartReq 3 "NA" 2 "Engine Stop" 1 "Engine Start" 0 "NoRequest" ;
VAL_ 2566849052 VolumeReq 3 "NA" 2 "Down" 1 "Up" 0 "NoRequest" ;
VAL_ 2566849052 RearFogLampReq 3 "NA" 2 "Off" 1 "On" 0 "NoRequest" ;
VAL_ 2566849052 FrontFogLampReq 3 "NA" 2 "Off" 1 "On" 0 "NoRequest" ;
VAL_ 2566849052 ParkLampReq 3 "NA" 2 "Off" 1 "On" 0 "NoRequest" ;
VAL_ 2566849052 TurnSignReq 7 "NA" 6 "Reserved" 5 "Reserved" 4 "Off" 3 "Hazard On" 2 "Left Signal On" 1 "Right Signal On" 0 "NoRequest" ;
VAL_ 2566849052 HighBeamSignReq 3 "NA" 2 "Off" 1 "On" 0 "NoRequest" ;
VAL_ 2566849052 LowBeamSignReq 3 "NA" 2 "Off" 1 "On" 0 "NoRequest" ;
VAL_ 2566849052 BedAreaLampDimmReq 15 "Not Available" 14 "Error" 11 "Off" 10 "10%" 9 "20%" 8 "30%" 7 "40%" 6 "50%" 5 "60%" 4 "70%" 3 "80%" 2 "90%" 1 "100%" 0 "NoRequest" ;
VAL_ 2566849052 DomeLampDimmReq 15 "Not Available" 14 "Error" 11 "Off" 10 "10%" 9 "20%" 8 "30%" 7 "40%" 6 "50%" 5 "60%" 4 "70%" 3 "80%" 2 "90%" 1 "100%" 0 "NoRequest" ;
VAL_ 2566849052 MapReadDimmL 15 "Not Available" 14 "Error" 11 "Off" 10 "10%" 9 "20%" 8 "30%" 7 "40%" 6 "50%" 5 "60%" 4 "70%" 3 "80%" 2 "90%" 1 "100%" 0 "NoRequest" ;
VAL_ 2566849052 MapReadDimmR 15 "Not Available" 14 "Error" 11 "Off" 10 "10%" 9 "20%" 8 "30%" 7 "40%" 6 "50%" 5 "60%" 4 "70%" 3 "80%" 2 "90%" 1 "100%" 0 "NoRequest" ;
VAL_ 2566849052 GlobLampOffReq 3 "NA" 2 "Off" 1 "On" 0 "NoRequest" ;
VAL_ 2566849052 AmbLightReq 3 "NA" 2 "Off" 1 "On" 0 "NoRequest" ;
VAL_ 2566849052 CentralLockUnlock 3 "Not Available" 2 "Unlock" 1 "Lock" 0 "Not Requested" ;
VAL_ 2566849052 SunroofPos 3 "Not Available" 2 "Close" 1 "Open" 0 "Not Requested" ;
VAL_ 2566849052 PassWinPos 3 "Not Available" 2 "Down" 1 "Up" 0 "Not Requested" ;
VAL_ 2566849052 DriverWinPos 3 "Not Available" 2 "Down" 1 "Up" 0 "Not Requested" ;
VAL_ 2566849052 RemConnectionStatus 3 "Not Available" 2 "Error" 1 "Connected" 0 "Not Connected" ;
VAL_ 2566848535 SeatbeltStatus 3 "NA" 2 "Error" 1 "Not Belted" 0 "Belted" ;
VAL_ 2566848535 HeaterTimer1Status_Recurrence 3 "NA" 2 "Error" 1 "Repetitive" 0 "One Time" ;
VAL_ 2566848535 HeaterTimer1Status_Day 10 "Everyday" 9 "Weekends" 8 "Weekdays" 7 "Sunday" 6 "Saturday" 5 "Friday" 4 "Thursday" 3 "Wednesday" 2 "Tuesday" 1 "Monday" ;
VAL_ 2566848535 HeaterTimer1Status 1 "Active" 0 "Not Active" ;
VAL_ 2566834694 OccuranceCount 127 "Not Available" 0 "Valid Values" ;
VAL_ 2566834694 FMI 31 "Not Available" 12 "No Signal" 4 "Source Low" 3 "Source High" 2 "Not Plausible" 1 "Below Normal" 0 "Above Normal" ;
VAL_ 2566834694 FlashRedStopLamp 3 "Unavailable / Do Not Flash" 2 "Reserved" 1 "Fast Flash" 0 "Slow Flash" ;
VAL_ 2566834694 FlashProtectLamp 3 "Unavailable / Do Not Flash" 2 "Reserved" 1 "Fast Flash" 0 "Slow Flash" ;
VAL_ 2566834694 FlashMalfuncIndicatorLamp 3 "Unavailable / Do Not Flash" 2 "Reserved" 1 "Fast Flash" 0 "Slow Flash" ;
VAL_ 2566834694 FlashAmberWarningLamp 3 "Unavailable / Do Not Flash" 2 "Reserved" 1 "Fast Flash" 0 "Slow Flash" ;
VAL_ 2566834694 MalfunctionIndicatorLampStatus 3 "Not available" 2 "Reserved" 1 "Lamp on" 0 "Lamp off" ;
VAL_ 2566834694 AmberWarningLampStatus 3 "Not available" 2 "Reserved" 1 "Lamp on" 0 "Lamp off" ;
VAL_ 2566834694 RedStopLampState 3 "Not available" 2 "Reserved" 1 "Lamp on" 0 "Lamp off" ;
VAL_ 2566834694 ProtectLampStatus 3 "Not available" 2 "Reserved" 1 "Lamp on" 0 "Lamp off" ;
VAL_ 2566834693 OccuranceCount 127 "Not Available" 0 "Valid Values" ;
VAL_ 2566834693 FMI 31 "Not Available" 12 "No Signal" 4 "Source Low" 3 "Source High" 2 "Not Plausible" 1 "Below Normal" 0 "Above Normal" ;
VAL_ 2566834693 FlashRedStopLamp 3 "Unavailable / Do Not Flash" 2 "Reserved" 1 "Fast Flash" 0 "Slow Flash" ;
VAL_ 2566834693 FlashProtectLamp 3 "Unavailable / Do Not Flash" 2 "Reserved" 1 "Fast Flash" 0 "Slow Flash" ;
VAL_ 2566834693 FlashMalfuncIndicatorLamp 3 "Unavailable / Do Not Flash" 2 "Reserved" 1 "Fast Flash" 0 "Slow Flash" ;
VAL_ 2566834693 FlashAmberWarningLamp 3 "Unavailable / Do Not Flash" 2 "Reserved" 1 "Fast Flash" 0 "Slow Flash" ;
VAL_ 2566834693 MalfunctionIndicatorLampStatus 3 "Not available" 2 "Reserved" 1 "Lamp on" 0 "Lamp off" ;
VAL_ 2566834693 AmberWarningLampStatus 3 "Not available" 2 "Reserved" 1 "Lamp on" 0 "Lamp off" ;
VAL_ 2566834693 RedStopLampState 3 "Not available" 2 "Reserved" 1 "Lamp on" 0 "Lamp off" ;
VAL_ 2566834693 ProtectLampStatus 3 "Not available" 2 "Reserved" 1 "Lamp on" 0 "Lamp off" ;
VAL_ 2566835968 OccuranceCount 127 "Not Available" 0 "Valid Values" ;
VAL_ 2566835968 FMI 31 "Not Available" 12 "No Signal" 4 "Source Low" 3 "Source High" 2 "Not Plausible" 1 "Below Normal" 0 "Above Normal" ;
VAL_ 2566835968 MalfuncIndicatorLampStatus_DM2 1 "Lamp on" 0 "Lamp off" ;
VAL_ 2566835968 RedStopLampState_DM2 1 "Lamp on" 0 "Lamp off" ;
VAL_ 2566835968 AmberWarningLampStatus_DM2 1 "Lamp on" 0 "Lamp off" ;
VAL_ 2566835968 ProtectLampStatus_DM2 1 "Lamp on" 0 "Lamp off" ;
VAL_ 2566835968 FlashRedStopLamp 3 "Unavailable / Do Not Flash" 2 "Reserved" 1 "Fast Flash" 0 "Slow Flash" ;
VAL_ 2566835968 FlashProtectLamp 3 "Unavailable / Do Not Flash" 2 "Reserved" 1 "Fast Flash" 0 "Slow Flash" ;
VAL_ 2566835968 FlashMalfuncIndicatorLamp 3 "Unavailable / Do Not Flash" 2 "Reserved" 1 "Fast Flash" 0 "Slow Flash" ;
VAL_ 2566835968 FlashAmberWarningLamp 3 "Unavailable / Do Not Flash" 2 "Reserved" 1 "Fast Flash" 0 "Slow Flash" ;
VAL_ 2566834944 OccuranceCount 127 "Not Available" 0 "Valid Values" ;
VAL_ 2566834944 FMI 31 "Not Available" 12 "No Signal" 4 "Source Low" 3 "Source High" 2 "Not Plausible" 1 "Below Normal" 0 "Above Normal" ;
VAL_ 2566834944 MalfuncIndicatorLampStatus_DM2 1 "Lamp on" 0 "Lamp off" ;
VAL_ 2566834944 RedStopLampState_DM2 1 "Lamp on" 0 "Lamp off" ;
VAL_ 2566834944 AmberWarningLampStatus_DM2 1 "Lamp on" 0 "Lamp off" ;
VAL_ 2566834944 ProtectLampStatus_DM2 1 "Lamp on" 0 "Lamp off" ;
VAL_ 2566834944 FlashRedStopLamp 3 "Unavailable / Do Not Flash" 2 "Reserved" 1 "Fast Flash" 0 "Slow Flash" ;
VAL_ 2566834944 FlashProtectLamp 3 "Unavailable / Do Not Flash" 2 "Reserved" 1 "Fast Flash" 0 "Slow Flash" ;
VAL_ 2566834944 FlashMalfuncIndicatorLamp 3 "Unavailable / Do Not Flash" 2 "Reserved" 1 "Fast Flash" 0 "Slow Flash" ;
VAL_ 2566834944 FlashAmberWarningLamp 3 "Unavailable / Do Not Flash" 2 "Reserved" 1 "Fast Flash" 0 "Slow Flash" ;
VAL_ 2348814341 MessageCounter 15 "Not Available" ;
VAL_ 2348814341 OverrideCtrlModePriority 3 "LowPriority" ;
VAL_ 2348814341 EngOverrideCtrlMode 2 "Torque control" 0 "Override disabled" ;
VAL_ 2348814341 MessageChecksum 15 "Not Available" ;
VAL_ 2632777523 PGNumber 255 "NotAvailable" ;
VAL_ 2632777523 ControlByte 24 "EAbort" 23 "EEoMACK" 22 "EDPO" 21 "ECTS" 20 "ERTS" 255 "Abort" 32 "BAM" 19 "EoMA" 17 "CTS" 16 "RTS" ;
VAL_ 2633935619 RecommendedGear 251 "Park" ;
VAL_ 2565406464 ControlByte 3 "CannotRespond" 2 "AccessDenied" 1 "NACK" 0 "ACK" ;
VAL_ 2565668641 PGNumber 255 "NotAvailable" ;
VAL_ 2565668641 ControlByte 24 "EAbort" 23 "EEoMACK" 22 "EDPO" 21 "ECTS" 20 "ERTS" 255 "Abort" 32 "BAM" 19 "EoMA" 17 "CTS" 16 "RTS" ;
VAL_ 2565537768 ParameterGroupNumber 65254 "Time Date" 65253 "Engine Hours" 65251 "Engine Configuration" 65249 "Retarder Configuration" 65217 "Vehicle Distance High Resolution" 65031 "CVW (Combined Vehicle Weight)" ;
VAL_ 2565537578 ParameterGroupNumber 65254 "Time Date" 65253 "Engine Hours" 65251 "Engine Configuration" 65249 "Retarder Configuration" 65217 "Vehicle Distance High Resolution" 65031 "CVW (Combined Vehicle Weight)" ;
VAL_ 2566844711 ACC_GAPButtonStatus 3 "Not available" 2 "Error Indicator" 1 "Not Pressed" 0 "Pressed" ;
VAL_ 2566844711 CruiseControlstate 7 "Not Available" 6 "Accelerator Override" 5 "Set" 4 "Resume" 3 "Decelerate " 2 "Accelerate" 1 "Hold" 0 "Off / Disabled" ;
VAL_ 2566844711 CruiseControlactive 3 "Not Available" 2 "Error Indicator" 1 "CC Switched On" 0 "CC Switched Off" ;
VAL_ 2566844711 CruiseControlenableswitch 3 "NotAvailable" 2 "Error" 1 "CruiseCtrlEnabled" 0 "CruiseCtrlDisabled" ;
VAL_ 2566844711 ACCInhibit 3 "Not Available" 2 "Error Indicator" 1 "ACC inhibited" 0 "ACC not inhibited" ;
VAL_ 2566844711 ACCStateWarning 15 "Error" 14 "Warning 14 - Other Reason" 13 "Warning 13" 12 "Warning 12" 11 "Warning 11" 10 "Warning 10" 9 "Warning 9" 8 "ACC Brake Capacity Warning" 7 "Normal Cruise Active" 6 "Extended Braking Active" 5 "ACC Cancelled" 4 "Brake Temp Reduced Performance" 3 "Brake Temp Cancellation" 2 "Radar Blocked" 1 "Extended Braking Stopped" 0 "No warning" ;
VAL_ 2566907955 ManualLearnStatus 15 "Signal Not Available" 14 "Error" 8 "Failed (Vehicle Speed Not Zero)" 7 "Failed (Parking Brake Off)" 6 "Failed (Engine Speed Not Zero)" 5 "Failed (Sensor ID Conflict)" 4 "Failed (Session Expired)" 3 "Complete" 2 "In progress" 0 "Inactive" ;
VAL_ 2566907955 TruckTrailerFlag 3 "Reserved" 2 "Reserved" 1 "Trailer Use" 0 "Tractor Use" ;
VAL_ 2566907955 PageSelection 0 "Field definitions for each bit" ;
VAL_ 2566834721 OccuranceCount 127 "Not Available" 0 "Valid Values" ;
VAL_ 2566834721 FMI 31 "Not Available" 12 "No Signal" 4 "Source Low" 3 "Source High" 2 "Not Plausible" 1 "Below Normal" 0 "Above Normal" ;
VAL_ 2566834721 DM1_FlashRedStopLamp 3 "Unavailable / Do Not Flash" 2 "Reserved" 1 "Fast Flash" 0 "Slow Flash" ;
VAL_ 2566834721 DM1_FlashProtectLamp 3 "Unavailable / Do Not Flash" 2 "Reserved" 1 "Fast Flash" 0 "Slow Flash" ;
VAL_ 2566834721 DM1_FlashMalfuncIndicatorLamp 3 "Unavailable / Do Not Flash" 2 "Reserved" 1 "Fast Flash" 0 "Slow Flash" ;
VAL_ 2566834721 DM1_FlashAmberWarningLamp 3 "Unavailable / Do Not Flash" 2 "Reserved" 1 "Fast Flash" 0 "Slow Flash" ;
VAL_ 2566834721 DM1_MalfunctionIndicatorLampSt 3 "Not available" 2 "Reserved" 1 "Lamp on" 0 "Lamp off" ;
VAL_ 2566834721 DM1_AmberWarningLampStatus 3 "Not available" 2 "Reserved" 1 "Lamp on" 0 "Lamp off" ;
VAL_ 2566834721 DM1_RedStopLampState 3 "Not available" 2 "Reserved" 1 "Lamp on" 0 "Lamp off" ;
VAL_ 2566834721 DM1_ProtectLampStatus 3 "Not available" 2 "Reserved" 1 "Lamp on" 0 "Lamp off" ;
VAL_ 2566852650 CMTInstalledandEnabled 1 "Not enabled" 0 "Enabled" ;
VAL_ 2566852650 TSRWarningFlag 1 "False" 0 "True" ;
VAL_ 2566852650 TSROveruse 1 "False" 0 "True" ;
VAL_ 2566852650 FusionEnableFlag 1 "Disabled" 0 "Enabled" ;
VAL_ 2566852650 FLRErrorStatus 1 "No error" 0 "Error" ;
VAL_ 2566852650 CMTFoundationBrakeRequest 1 "Not active" 0 "Active" ;
VAL_ 2566852650 CMTInterventionStatus 1 "Not active" 0 "Active" ;
VAL_ 2566852650 AEBPossible 1 "False" 0 "True" ;
VAL_ 2566852650 BendixPowerOnSelfTest 3 "Not ready" 2 "Test failed" 1 "Test passed" 0 "In progress" ;
VAL_ 2566852650 TargetFusedIndicator 1 "Fused" 0 "Not fused" ;
VAL_ 2566852650 FusionAvailableFlag 1 "Not available" 0 "Available" ;
VAL_ 2566852650 WingmanSensorBlockedNoObjectsDet 3 "Not available" 2 "Error" 1 "Active" 0 "Not active" ;
VAL_ 2566852650 WingmanTargetDetectLamp 3 "Not available" 2 "Error" 1 "Active" 0 "Not active" ;
VAL_ 2566852650 CruiseControlONTelltale 3 "Not available" 2 "Error" 1 "Active" 0 "Not active" ;
VAL_ 2566852650 VehicleCruiseControlSetSpeed 255 "Not available" 254 "Error" ;
VAL_ 2566852650 VehicleFollowingInterval 255 "Not available" 254 "Error" ;
VAL_ 2566852650 VehicleFollowingDistance 255 "Not available" 254 "Error" ;
VAL_ 2566852650 ACBDisDueToExcBrakeUse 3 "Error" 2 "Not available" 1 "Active" 0 "Not active" ;
VAL_ 2566852650 VisualFollowingDistanceAlertRec 7 "Not available" 6 "Error" 5 "Dynamometer mode active" 4 "Red lamp" 3 "SOW visual (icon or lamp)" 2 "Yellow / amber lamp" 1 "Power on self-test (POST) active" 0 "Off - No visual alert" ;
VAL_ 2566852650 AudibleFollowingDistanceAlertRec 7 "Not available" 6 "Error" 5 "Solid tone for dur.ofmsg(min 3s)" 4 "Single one second beep at event" 3 "Audible 3 - Continuous beeping" 2 "Audible 2 - Double beep/second" 1 "Audible 1 - Single beep/second" 0 "Off - No Alert" ;
VAL_ 2566852650 NetVehFollowingDistanceInterval 255 "Not available" 254 "Error indicator" ;
VAL_ 2566849866 VINACK_status 5 "VIN vaildate with previously VIN" 4 "Timout during VIN validation" 3 "Timout during VIN configuration" 2 "VIN not match previosly VIN" 1 "VIN Configuration done " 0 "Factory Def.:Config. not start" ;
VAL_ 2566849866 Comm_module_failure 3 "Not available" 2 "Error" 1 "DTC exist" 0 "DTC not exist" ;
VAL_ 2566849866 Last_failure 3 "Not available" 2 "Error" 1 "DTC exist" 0 "DTC not exist" ;
VAL_ 2566849866 Other_not_critical_failures 3 "Not available" 2 "Error" 1 "DTC exist" 0 "DTC not exist" ;
VAL_ 2566849866 Other_critical_failures 3 "Not available" 2 "Error" 1 "DTC exist" 0 "DTC not exist" ;
VAL_ 2566849866 Crash_profile_memory_overflow 3 "Not available" 2 "Error" 1 "DTC exist" 0 "DTC not exist" ;
VAL_ 2566849866 Events_memory_overflow 3 "Not available" 2 "Error" 1 "DTC exist" 0 "DTC not exist" ;
VAL_ 2566849866 Gnss_antenna_failure 3 "Not available" 2 "Error" 1 "DTC exist" 0 "DTC not exist" ;
VAL_ 2566849866 Raim_problem 3 "Not available" 2 "Error" 1 "DTC exist" 0 "DTC not exist" ;
VAL_ 2566849866 Gnss_receiver_failure 3 "Not available" 2 "Error" 1 "DTC exist" 0 "DTC not exist" ;
VAL_ 2566849866 Comm_module_iterface_failure 3 "Not available" 2 "Error" 1 "DTC exist" 0 "DTC not exist" ;
VAL_ 2566849866 Firmware_image_corruption 3 "Not available" 2 "Error" 1 "DTC exist" 0 "DTC not exist" ;
VAL_ 2566849866 Crash_sens_failure 3 "Not available" 2 "Error" 1 "DTC exist" 0 "DTC not exist" ;
VAL_ 2566849866 Battery_voltage_low 3 "Not available" 2 "Error" 1 "DTC exist" 0 "DTC not exist" ;
VAL_ 2566849866 Battery_failure 3 "Not available" 2 "Error" 1 "DTC exist" 0 "DTC not exist" ;
VAL_ 2566849866 Status_indicator_failure 3 "Not available" 2 "Error" 1 "DTC exist" 0 "DTC not exist" ;
VAL_ 2566849866 Uim_failure 3 "Not available" 2 "Error" 1 "DTC exist" 0 "DTC not exist" ;
VAL_ 2566849866 Ignition_line_failure 3 "Not available" 2 "Error" 1 "DTC exist" 0 "DTC not exist" ;
VAL_ 2566849866 Speakers_failure 3 "Not available" 2 "Error" 1 "DTC exist" 0 "DTC not exist" ;
VAL_ 2566849866 Mic_failure 3 "Not available" 2 "Error" 1 "DTC exist" 0 "DTC not exist" ;
VAL_ 2566849866 Mic_connection_failure 3 "Not available" 2 "Error" 1 "DTC exist" 0 "DTC not exist" ;
VAL_ 2566856958 DriverRequestRCU 8 "Memory 2 Level Save" 7 "Memory 2 Height Request" 6 "Memory 1 Level Save" 5 "Memory 1 Height Request" 4 "Raise Chassis Height" 3 "Lower Chassis Height" 2 "Stop Button Pressed" 1 "Ride Height Request" ;
VAL_ 2566870278 Washer 3 "Not available" 2 "Error" 1 "On" 0 "Off" ;
VAL_ 2566870278 FlashToPass 3 "Not available" 2 "Error" 1 "On" 0 "Off" ;
VAL_ 2566870278 HighBeamStatus 3 "Not available" 2 "Error" 1 "On" 0 "Off" ;
VAL_ 2566870278 TurnSignalSwitch_LMFSwitch 15 "Not available" 14 "Error" 2 "Right turn to be flashing" 1 "Left turn tp be flashing" 0 "No turn being signalled" ;
VAL_ 2566870278 Wiper 15 "Not available" 4 "Continuous Speed 2 (High)" 3 "Continuous Speed 1 (Low)" 2 "Intermittent 2" 1 "Intermittent 1" 0 "Off" ;
VAL_ 2566870277 Hand_Lever_Signals_INTARDER 255 "Not available" 0 "Position 0" 31 "Position 5" 15 "Position 4" 7 "Position 3" 3 "Position 2" 1 "Position 1" ;
VAL_ 2566870277 Hand_Lever_Signals_PROP_IT3 255 "Not available" 0 "Position 0" 31 "Position 5" 15 "Position 4" 7 "Position 3" 3 "Position 2" 1 "Position 1" ;
VAL_ 2348876549 TransmissionRequestedGear 252 "Forward Drive Position" 249 "Upshift 1 gear" 248 "Upshift 2 gears" 247 "Downshift 1 gear" 246 "Downshift 2 gears " 231 "Toggle btw Auto and Man" 228 "Forward Manv" 224 "No Command" 222 "Neutral Gear" 28 "Reverse Manv" 255 "Not Available" 254 "Error" 223 "Reverse Selector Position" ;
VAL_ 2348876549 MessageCounter 14 "Reserved" 13 "Reserved" 12 "Reserved" 11 "Reserved" 10 "Reserved" 9 "Reserved" 8 "Reserved" 15 "Not Available" ;
VAL_ 2348876549 MessageChecksum 15 "Not Available" ;
VAL_ 2348876549 RollingModeRMFS 3 "TakeNoAction" 2 "Reserve" 1 "Enabled" 0 "Disabled" ;
VAL_ 2348876549 RockingModeRMFS 3 "TakeNoAction" 2 "Reserve" 1 "Enabled" 0 "Disabled" ;
VAL_ 2348876549 OffRaodModeRMFS 3 "TakeNoAction" 2 "Reserve" 1 "Enabled" 0 "Disabled" ;
VAL_ 2348876549 PowerModeRMFS 3 "TakeNoAction" 2 "Reserve" 1 "Enabled" 0 "Disabled" ;
VAL_ 2566848796 DrvTips_State 255 "Error" 20 "Tip 20" 19 "Tip 19" 18 "Tip 18" 17 "Tip 17" 16 "Tip 16" 15 "Tip 15" 14 "Tip 14" 13 "Tip 13" 12 "Tip 12" 11 "Tip 11" 10 "Tip 10" 9 "Tip 9" 8 "Tip 8" 7 "Tip 7" 6 "Tip 6" 5 "Tip 5" 4 "Tip 4" 3 "Tip 3" 2 "Tip 2" 1 "Tip 1" 0 "No tips shown" ;
VAL_ 2566834736 AmberWarningLampStatus 3 "Not available" 2 "Reserved" 1 "Lamp on" 0 "Lamp off" ;
VAL_ 2566849024 SootLoad 15 "Error" 14 "Error" 13 "Error" 12 "Error" 11 "Error" 10 "All bars blinking" 9 "First 9 bar are filled & blinks" 8 "8th bar filled" 7 "7th bar filled" 6 "6th bar filled" 5 "5th bar filled" 4 "4th bar filled" 3 "3rd bar filled" 2 "2nd bar filled" 1 "1st bar filled" 0 "No bar filled" ;
VAL_ 2566849024 ManualRegenStatus 3 "Not available" 2 "Error" 1 "Regen in progress" 0 "Regen not in progress" ;
VAL_ 2566864417 ContactLockKL15 3 "Not available" 2 "Reserved" 1 "Contact lock KL 15 on" 0 "Contact lock KL 15 off" ;
VAL_ 2566810903 EngOff_T_Actl_IC 65535 "Invalid" ;
VAL_ 2566810903 AirRefreshMode 3 "Not available" 2 "Error" 1 "Active" 0 "Deactive" ;
VAL_ 2566810903 WaterHeaterMode 3 "Not available" 2 "Error" 1 "Active" 0 "Deactive" ;
VAL_ 2566810903 AirDistributionMode_IPC 6 "Windshield & Panel & Foot" 15 "Not available" 14 "Error" 5 "Panel & Foot" 4 "Windshield & Foot" 3 "Windshield & Panel" 2 "Foot" 1 "Panel" 0 "Windshield" ;
VAL_ 2566810903 AirHeaterMode 3 "Not available" 2 "Error" 1 "Active" 0 "Deactive" ;
VAL_ 2566907927 ManualLearnStatus 1 "Active" 0 "Inactive" ;
VAL_ 2566907927 TruckTrailerFlag 3 "Reserved" 2 "Reserved" 1 "Trailer Use" 0 "Tractor Use" ;
VAL_ 2566907927 PageSelection 0 "Field definitions for each bit" ;
VAL_ 2566834691 OccuranceCount 127 "Not Available" 0 "Valid Values" ;
VAL_ 2566834691 FMI 31 "Not Available" 12 "No Signal" 4 "Source Low" 3 "Source High" 2 "Not Plausible" 1 "Below Normal" 0 "Above Normal" ;
VAL_ 2566834691 FlashRedStopLamp 3 "Unavailable / Do Not Flash" 2 "Reserved" 1 "Fast Flash" 0 "Slow Flash" ;
VAL_ 2566834691 FlashProtectLamp 3 "Unavailable / Do Not Flash" 2 "Reserved" 1 "Fast Flash" 0 "Slow Flash" ;
VAL_ 2566834691 FlashMalfuncIndicatorLamp 3 "Unavailable / Do Not Flash" 2 "Reserved" 1 "Fast Flash" 0 "Slow Flash" ;
VAL_ 2566834691 FlashAmberWarningLamp 3 "Unavailable / Do Not Flash" 2 "Reserved" 1 "Fast Flash" 0 "Slow Flash" ;
VAL_ 2566834691 MalfunctionIndicatorLampStatus 3 "Not available" 2 "Reserved" 1 "Lamp on" 0 "Lamp off" ;
VAL_ 2566834691 AmberWarningLampStatus 3 "Not available" 2 "Reserved" 1 "Lamp on" 0 "Lamp off" ;
VAL_ 2566834691 RedStopLampState 3 "Not available" 2 "Reserved" 1 "Lamp on" 0 "Lamp off" ;
VAL_ 2566834691 ProtectLampStatus 3 "Not available" 2 "Reserved" 1 "Lamp on" 0 "Lamp off" ;
VAL_ 2566834739 FlashRedStopLamp 3 "Unavailable / Do Not Flash" 2 "Reserved" 1 "Fast Flash" 0 "Slow Flash" ;
VAL_ 2566834739 FlashProtectLamp 3 "Unavailable / Do Not Flash" 2 "Reserved" 1 "Fast Flash" 0 "Slow Flash" ;
VAL_ 2566834739 FlashMalfuncIndicatorLamp 3 "Unavailable / Do Not Flash" 2 "Reserved" 1 "Fast Flash" 0 "Slow Flash" ;
VAL_ 2566834739 FlashAmberWarningLamp 3 "Unavailable / Do Not Flash" 2 "Reserved" 1 "Fast Flash" 0 "Slow Flash" ;
VAL_ 2566834739 MalfunctionIndicatorLampStatus 3 "Not available" 2 "Reserved" 1 "Lamp on" 0 "Lamp off" ;
VAL_ 2566834739 AmberWarningLampStatus 3 "Not available" 2 "Reserved" 1 "Lamp on" 0 "Lamp off" ;
VAL_ 2566834739 RedStopLampState 3 "Not available" 2 "Reserved" 1 "Lamp on" 0 "Lamp off" ;
VAL_ 2566834739 ProtectLampStatus 3 "Not available" 2 "Reserved" 1 "Lamp on" 0 "Lamp off" ;
VAL_ 2566907699 AxlePlacardPressureUpd 15 "Not available" 14 "Error" 13 "Reserved for future use" 12 "Reserved for future use" 11 "Reserved for future use" 10 "Reserved for future use" 9 "Reserved for future use" 8 "Reserved for future use" 7 "Reserved for future use" 6 "Reserved for future use" 5 "Reserved for future use" 4 "Axle 5" 3 "Axle 4" 2 "Axle 3" 1 "Axle 2" 0 "Axle 1" ;
VAL_ 2566907443 SensorIDMissingWarning 3 "Not available" 2 "Error" 1 "LearntSensorIDSupported&Missing" 0 "LearntSensorIDSupported&Present" ;
VAL_ 2566907443 TPMSTyreFillAssistant 15 "Description for the value '0xF'" 14 "Error" 13 "Reserved" 12 "Reserved" 11 "Reserved" 10 "Reserved" 9 "Reserved" 8 "Reserved" 7 "Reserved" 6 "Reserved" 5 "Reserved" 4 "Description for the value '0x4'" 3 "Target tyre pressure is reached" 2 "Event occurs&tyre is deflating" 1 "Event occurs&tyre is inflating " 0 "Supported but no event detected" ;
VAL_ 2566907443 TPMSTyreLockDetectedStts 3 "Not available" 2 "Error" 1 "Event is occuring" 0 "Supported but no event detected" ;
VAL_ 2566907443 TPMSTyreOverTempStts 3 "Description for the value '0x3'" 2 "Error" 1 "Event is occurring" 0 "Supported but no detection" ;
VAL_ 2566907443 TPMSTyreBurstStts 3 "Not available" 2 "Error" 1 "Tyre burst event occurs" 0 "Tyre over  temp status supported" ;
VAL_ 2566907443 TPMSTyrePresStts 15 "Description for the value '0xF'" 14 "Error" 13 "Signal not supported" 12 "Not defined" 11 "Not defined" 10 "Not defined" 9 "Not defined" 8 "Not defined" 7 "Not defined" 6 "Extreme under pressure" 5 "Under pressure" 4 "ECO under pressure" 3 "Extreme over pressure" 2 "Over pressure" 1 "ECO over pressure" 0 "Nominal Pressure" ;
VAL_ 2566907443 TPMSFastPresLssStats 3 "Description for the value '0x3'" 2 "Error" 1 "Fast pressure loss event occurs" 0 "Fast pressure lost status" ;
